[part 4 of 23: package /Cluster]
AUTOSAR XML (schema 4-3-0)
package /Cluster  (continued)
  can cluster E3V_EVCANFD: baudrate=500000, protocol-name=CAN, protocol-version=2.0, bus-off-recovery={bor-counter-l-1-to-l-2=1, bor-time-l-1=0.05, bor-time-l-2=0.2}, can-fd-baudrate=2000000  (continued)
    can physical channel CHNL: comm-connectors=CN_E3V_EVCANFD  (continued)
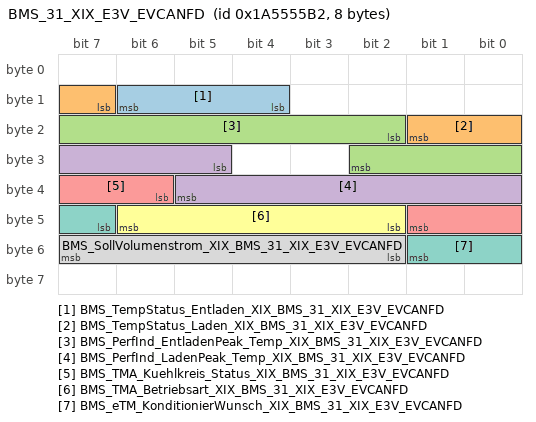
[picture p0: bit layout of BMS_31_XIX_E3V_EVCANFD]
      frame BMS_31_XIX_E3V_EVCANFD: id 0x1A5555B2, to Klima, frame-length=8, can-addressing-mode=EXTENDED, can-frame-rx-behavior=CAN-FD, can-frame-tx-behavior=CAN-FD
        pdu BMS_31_XIX_E3V_EVCANFD: length=8, transmission-mode-true-timing=cyclic-timing={time-offset=0.0, time-period=0.5}, unused-bit-pattern=0
          signal BMS_TempStatus_Entladen_XIX_BMS_31_XIX_E3V_EVCANFD: start 12, 3 bit, little-endian, data-type-policy=OVERRIDE, i-signal-type=PRIMITIVE, init-value=0, base-type=BT_BMS_TempStatus_Entladen, invalid-value=Invalid_BMS_TempStatus_Entladen_XIX_BMS_31_XIX_E3V_EVCANFD:7, compu {0=Cx0_Init (CM_BMS_TempStatus_Entladen_Cx0_Init), 1=Cx1_Temperatur_kleiner_optimal (CM_BMS_TempStatus_Entladen_Cx1_Temperatur_kleiner_optimal), 2=Cx2_Temperatur_optimal (CM_BMS_TempStatus_Entladen_Cx2_Temperatur_optimal), 3=Cx3_Temperatur_groesser_optimal (CM_BMS_TempStatus_Entladen_Cx3_Temperatur_groesser_optimal), 7=Cx7_Fehler (CM_BMS_TempStatus_Entladen_Cx7_Fehler)}, range raw 0..7, transfer-property=PENDING  # Signalisiert den Temperaturzustand der Batterie aufgrund dessen eine evt. Leistungseinschränkung beim Entladen besteht.
          signal BMS_TempStatus_Laden_XIX_BMS_31_XIX_E3V_EVCANFD: start 15, 3 bit, little-endian, data-type-policy=OVERRIDE, i-signal-type=PRIMITIVE, init-value=0, base-type=BT_BMS_TempStatus_Laden, invalid-value=Invalid_BMS_TempStatus_Laden_XIX_BMS_31_XIX_E3V_EVCANFD:7, compu {0=Cx0_Init (CM_BMS_TempStatus_Laden_Cx0_Init), 1=Cx1_Temperatur_kleiner_optimal (CM_BMS_TempStatus_Laden_Cx1_Temperatur_kleiner_optimal), 2=Cx2_Temperatur_optimal (CM_BMS_TempStatus_Laden_Cx2_Temperatur_optimal), 3=Cx3_Temperatur_groesser_optimal (CM_BMS_TempStatus_Laden_Cx3_Temperatur_groesser_optimal), 7=Cx7_Fehler (CM_BMS_TempStatus_Laden_Cx7_Fehler)}, range raw 0..7, transfer-property=PENDING  # Signalisiert den Temperaturzustand der Batterie aufgrund dessen eine evt. Leistungseinschränkung beim Laden besteht.
          signal BMS_PerfInd_EntladenPeak_Temp_XIX_BMS_31_XIX_E3V_EVCANFD: start 18, 9 bit, little-endian, data-type-policy=OVERRIDE, i-signal-type=PRIMITIVE, init-value=510, base-type=BT_BMS_PerfInd_EntladenPeak_Temp, invalid-value=Invalid_BMS_PerfInd_EntladenPeak_Temp_XIX_BMS_31_XIX_E3V_EVCANFD:511, compu {phys=raw*0.2 for raw 0..500, 510=Cx1fe_Init (CM_BMS_PerfInd_EntladenPeak_Temp_Cx1fe_Init), 511=Cx1ff_Fehler (CM_BMS_PerfInd_EntladenPeak_Temp_Cx1ff_Fehler); unit Unit_PerCent}, range phys 0..100 Unit_PerCent, raw 0..511, unit=Unit_PerCent, transfer-property=PENDING  # Peformanceindikator für temperaturabhängige Leistungsreduzierung beim Entladen (bezogen auf Peakleistung entsprechend des SOCs bei Wohlfühltemperatur)
          signal BMS_PerfInd_LadenPeak_Temp_XIX_BMS_31_XIX_E3V_EVCANFD: start 29, 9 bit, little-endian, data-type-policy=OVERRIDE, i-signal-type=PRIMITIVE, init-value=510, base-type=BT_BMS_PerfInd_LadenPeak_Temp, invalid-value=Invalid_BMS_PerfInd_LadenPeak_Temp_XIX_BMS_31_XIX_E3V_EVCANFD:511, compu {phys=raw*0.2 for raw 0..500, 510=Cx1fe_Init (CM_BMS_PerfInd_LadenPeak_Temp_Cx1fe_Init), 511=Cx1ff_Fehler (CM_BMS_PerfInd_LadenPeak_Temp_Cx1ff_Fehler); unit Unit_PerCent}, range phys 0..100 Unit_PerCent, raw 0..511, unit=Unit_PerCent, transfer-property=PENDING  # Peformanceindikator für temperaturabhängige Leistungsreduzierung beim Laden (bezogen auf Peakleistung entsprechend des SOCs bei Wohlfühltemperatur)
          signal BMS_TMA_Kuehlkreis_Status_XIX_BMS_31_XIX_E3V_EVCANFD: start 38, 4 bit, little-endian, data-type-policy=OVERRIDE, i-signal-type=PRIMITIVE, init-value=0, base-type=BT_BMS_TMA_Kuehlkreis_Status, invalid-value=Invalid_BMS_TMA_Kuehlkreis_Status_XIX_BMS_31_XIX_E3V_EVCANFD:15, compu {0=Cx0_Off (CM_BMS_TMA_Kuehlkreis_Status_Cx0_Off), 1=Cx1_Umwaelzbetrieb (CM_BMS_TMA_Kuehlkreis_Status_Cx1_Umwaelzbetrieb), 2=Cx2_Kuehlung_1_Kreis_Betrieb (CM_BMS_TMA_Kuehlkreis_Status_Cx2_Kuehlung_1_Kreis_Betrieb), 3=Cx3_Heizung_1_Kreis_Betrieb (CM_BMS_TMA_Kuehlkreis_Status_Cx3_Heizung_1_Kreis_Betrieb), 4=Cx4_Aktive_Kuehlung_2_Kreis_Betrieb (CM_BMS_TMA_Kuehlkreis_Status_Cx4_Aktive_Kuehlung_2_Kreis_Betrieb), 5=Cx5_Aktive_Heizung_2_Kreis_Betrieb (CM_BMS_TMA_Kuehlkreis_Status_Cx5_Aktive_Heizung_2_Kreis_Betrieb), 15=Cxf_Fehler (CM_BMS_TMA_Kuehlkreis_Status_Cxf_Fehler)}, range raw 0..15, transfer-property=PENDING, to Klima(timeout 5 s)  # HVBat meldet den seitens Batterie gerade aktiven Zustand des Kühlkreises/Kühlsystems. 0 = Batterieklimatisierung abgeschaltet, Pumpe abgeschaltet. Ventilstellung im 2-Kreis-Betrieb, so daß NT-Kreis weiterhin betrieben werden kann. 1 = Umwälzbetrieb, thermisches Balancing; Batteriekreis vom NT-Kreis getrennt. 2 = Batteriekühlung im 1-Kreis-Betrieb, Batterie-Kühlkreis mit NT-Kreis gekoppelt. 3 = Batterieheizung im 1-Kreis-Betrieb, Batterie-Kühlkreis mit NT-Kreis gekoppelt. 4 = aktive Batteriekühlung über Chiller im 2-Kreis-Betrieb; Batteriekreis vom NT-Kreis getrennt.. 5 = aktive Batterieheizung über HV-Heizer im 2-Kreis-Betrieb; Batteriekreis vom NT-Kreis getrennt. 15 = Allgemeiner Kühlsystem-Fehler
          signal BMS_TMA_Betriebsart_XIX_BMS_31_XIX_E3V_EVCANFD: start 42, 5 bit, little-endian, data-type-policy=OVERRIDE, i-signal-type=PRIMITIVE, init-value=30, base-type=BT_BMS_TMA_Betriebsart, invalid-value=Invalid_BMS_TMA_Betriebsart_XIX_BMS_31_XIX_E3V_EVCANFD:31, compu {0=Cx0_BA_TMA_Off (CM_BMS_TMA_Betriebsart_Cx0_BA_TMA_Off), 1=Cx1_BA_TMA_Drv (CM_BMS_TMA_Betriebsart_Cx1_BA_TMA_Drv), 2=Cx2_BA_TMA_DrvLadVoKo (CM_BMS_TMA_Betriebsart_Cx2_BA_TMA_DrvLadVoKo), 3=Cx3_BA_TMA_AC (CM_BMS_TMA_Betriebsart_Cx3_BA_TMA_AC), 4=Cx4_BA_TMA_DC (CM_BMS_TMA_Betriebsart_Cx4_BA_TMA_DC), 5=Cx5_BA_TMA_BiDi (CM_BMS_TMA_Betriebsart_Cx5_BA_TMA_BiDi), 6=Cx6_BA_TMA_HeatTransferWP (CM_BMS_TMA_Betriebsart_Cx6_BA_TMA_HeatTransferWP), 7=Cx7_BA_TMA_VoKo (CM_BMS_TMA_Betriebsart_Cx7_BA_TMA_VoKo), 8=Cx8_BA_TMA_Nachlauf (CM_BMS_TMA_Betriebsart_Cx8_BA_TMA_Nachlauf), 9=Cx9_BA_TMA_OffgridAuto (CM_BMS_TMA_Betriebsart_Cx9_BA_TMA_OffgridAuto), 10=Cxa_BA_TMA_OffgridBCCM (CM_BMS_TMA_Betriebsart_Cxa_BA_TMA_OffgridBCCM), 11=Cxb_BA_TMA_KonservierungBCCM (CM_BMS_TMA_Betriebsart_Cxb_BA_TMA_KonservierungBCCM), 12=Cxc_BA_TMA_NachlaufBCCM (CM_BMS_TMA_Betriebsart_Cxc_BA_TMA_NachlaufBCCM), 13=Cxd_BA_TMA_Enteisung_Klima (CM_BMS_TMA_Betriebsart_Cxd_BA_TMA_Enteisung_Klima), 26=Cx1a_BA_TMA_Transport (CM_BMS_TMA_Betriebsart_Cx1a_BA_TMA_Transport), 27=Cx1b_BA_TMA_BremsReku (CM_BMS_TMA_Betriebsart_Cx1b_BA_TMA_BremsReku), 28=Cx1c_BA_TMA_Befuellung (CM_BMS_TMA_Betriebsart_Cx1c_BA_TMA_Befuellung), 29=Cx1d_BA_TMA_RoutineControl (CM_BMS_TMA_Betriebsart_Cx1d_BA_TMA_RoutineControl), 30=Cx1e_Init (CM_BMS_TMA_Betriebsart_Cx1e_Init), 31=Cx1f_Fehler (CM_BMS_TMA_Betriebsart_Cx1f_Fehler)}, range raw 0..31, transfer-property=PENDING, to Klima(timeout 5 s)  # Interne Betriebsart des Batterie-Thermomanagements. 0 = Klimatisierung abgeschaltet 1 = für "normalen" Fahrbetrieb aktiv 2 = Vorkonditionierung auf Schnelladung während Fahrt 3 = reduzierte Klimatisierung im AC-Laden 4 = maximale Klimatisierung im DC-Schnelladen 5 = reduzierte Klimatisierung im Bidirektionalen Laden 6 = Wärmetransfer Batterie zu Innenraum 7 = Vorkonditionierung/Standklima 8 = Klimatisierungs-Nachlauf 9 = Dauerkond. selbständig ausgelösst 10= Dauerkond. Care-Mode-getriggert 11= Konservierung; lebensdauerschonendes Einlagern der Batterie, veranlasst durch Care-Mode 12= Erweiterter Klimatisierungs-Nachlauf, veranlasst durch Care-Mode 13= Enteisung NTK; Klima hat Priorität, HVBat stellt ihren Bedarf zurück. 26= Transportmode / Transportschutz aktiv; Thermomanagement deaktiviert 27= Heizer für Bremsrekuperation aktiviert 28= Kühlkreis-Befüllung/Entlüftung 29= Stellgliedtest/Routine Control 30= Init 31= Fehler
          signal BMS_eTM_KonditionierWunsch_XIX_BMS_31_XIX_E3V_EVCANFD: start 47, 3 bit, little-endian, data-type-policy=OVERRIDE, i-signal-type=PRIMITIVE, init-value=0, base-type=BT_BMS_eTM_KonditionierWunsch, compu {0=Cx0_kein_Temperierwunsch (CM_BMS_eTM_KonditionierWunsch_Cx0_kein_Temperierwunsch), 1=Cx1_Kuehlwunsch (CM_BMS_eTM_KonditionierWunsch_Cx1_Kuehlwunsch), 2=Cx2_Heizwunsch (CM_BMS_eTM_KonditionierWunsch_Cx2_Heizwunsch)}, range raw 0..2, transfer-property=PENDING  # Über dieses Signal teilt die HV-Batterie mit, daß sie gerne über den NT-Kreis gekühlt oder geheizt werden möchte. Die potentielle Umsetzbarkeit dieses Konditionierungswunsches muß über ein CAN-Signal von der Antriebssteuerung bestätigt werden, bevor die HV-Batterie ihr Kühlsystem in den NT-Kreis schaltet.
          signal BMS_SollVolumenstrom_XIX_BMS_31_XIX_E3V_EVCANFD: start 50, 6 bit, little-endian, data-type-policy=OVERRIDE, i-signal-type=PRIMITIVE, init-value=62, base-type=BT_BMS_SollVolumenstrom, invalid-value=Invalid_BMS_SollVolumenstrom_XIX_BMS_31_XIX_E3V_EVCANFD:63, compu {phys=raw for raw 0..61, 62=Cx3e_Init (CM_BMS_SollVolumenstrom_Cx3e_Init), 63=Cx3f_Fehler (CM_BMS_SollVolumenstrom_Cx3f_Fehler); unit Unit_LiterPerMinut}, range phys 0..61 Unit_LiterPerMinut, raw 0..63, unit=Unit_LiterPerMinut, transfer-property=PENDING  # Soll Volumenstrom für Kühlkreislauf Batterie
      frame BMS_34_XIX_E3V_EVCANFD: id 0xAF95450, to Klima, frame-length=32, can-addressing-mode=EXTENDED, can-frame-rx-behavior=CAN-FD, can-frame-tx-behavior=CAN-FD
        pdu BMS_34_XIX_E3V_EVCANFD: length=24, minimum-delay=0.01, transmission-mode-true-timing={cyclic-timing={time-offset=0.0, time-period=0.1}, event-controlled-timing={number-of-repetitions=0, repetition-period=0.0}}, unused-bit-pattern=0
          signal BMS_Crashfall_erkannt_XIX_BMS_34_XIX_E3V_EVCANFD: start 14, 2 bit, little-endian, data-type-policy=OVERRIDE, i-signal-type=PRIMITIVE, init-value=0, base-type=BT_BMS_Crashfall_erkannt, compu {0=Cx0_Kein_Crash_erkannt (CM_BMS_Crashfall_erkannt_Cx0_Kein_Crash_erkannt), 1=Cx1_Crash_erkannt (CM_BMS_Crashfall_erkannt_Cx1_Crash_erkannt)}, range raw 0..1, transfer-property=PENDING  # Das Signal wird für den in der EU BattVO Art. 77 geforderten Batteriepass benötigt. Es zeigt an, ob die HV-Batterie einen Crashfall erlebt hat.
          signal BMS_UBE_XIX_BMS_34_XIX_E3V_EVCANFD: start 16, 16 bit, little-endian, data-type-policy=OVERRIDE, i-signal-type=PRIMITIVE, init-value=65534, base-type=BT_BMS_UBE, invalid-value=Invalid_BMS_UBE_XIX_BMS_34_XIX_E3V_EVCANFD:65535, compu {phys=raw*5-7400 for raw 0..65480, 65534=Cxfffe_Init (CM_BMS_UBE_Cxfffe_Init), 65535=Cxffff_Fehler (CM_BMS_UBE_Cxffff_Fehler); unit Unit_WattHour}, range phys -7400..320000 Unit_WattHour, raw 0..65535, unit=Unit_WattHour, transfer-property=PENDING  # „Usable Battery Energy“ = Nutzbare Entladeenergie der HV Batterie vom aktuellen Ladezustand bis zum Ende des elektrischen Fahrens unter Annahme von Homologationsbedingungen (Lastprofil, Temperatur). Ein negativer Wert bedeutet, dass der aktuelle Ladezustand kleiner als EV Abwurfschwelle ist. Bei BMS_UBE <= 0 muss die Betriebsstrategie das normale EV Fahrenn (homologierte Reichweite) beenden. Unter Einhaltung der Strom- und Leistungsgrenzen darf der Nullwert z.B. für Notstarts und Hybridstrategie unterschritten werden.
          signal BMS_UBE_T_XIX_BMS_34_XIX_E3V_EVCANFD: start 32, 16 bit, little-endian, data-type-policy=OVERRIDE, i-signal-type=PRIMITIVE, init-value=65534, base-type=BT_BMS_UBE_T, invalid-value=Invalid_BMS_UBE_T_XIX_BMS_34_XIX_E3V_EVCANFD:65535, compu {phys=raw*5-7400 for raw 0..65480, 65534=Cxfffe_Init (CM_BMS_UBE_T_Cxfffe_Init), 65535=Cxffff_Fehler (CM_BMS_UBE_T_Cxffff_Fehler); unit Unit_WattHour}, range phys -7400..320000 Unit_WattHour, raw 0..65535, unit=Unit_WattHour, transfer-property=PENDING, to Klima(timeout 1 s)  # Gleiche Bedeutung wie das Signal BMS_UBE unter Berücksichtigung der aktuellen Batterietemperatur. Eine Temperaturänderung wird nicht angenommen. Dieses Signal kann zum Beispiel verwendet werden, um eine Restenergie der HV Batterie zu berechnen.
          signal BMS_Max_UBE_XIX_BMS_34_XIX_E3V_EVCANFD: start 48, 16 bit, little-endian, data-type-policy=OVERRIDE, i-signal-type=PRIMITIVE, init-value=65534, base-type=BT_BMS_Max_UBE, invalid-value=Invalid_BMS_Max_UBE_XIX_BMS_34_XIX_E3V_EVCANFD:65535, compu {phys=raw*5-7400 for raw 0..65480, 65534=Cxfffe_Init (CM_BMS_Max_UBE_Cxfffe_Init), 65535=Cxffff_Fehler (CM_BMS_Max_UBE_Cxffff_Fehler); unit Unit_WattHour}, range phys -7400..320000 Unit_WattHour, raw 0..65535, unit=Unit_WattHour, transfer-property=PENDING  # BMS_UBE bei BMS_Ladezustand = BMS_Max_Ladezustand. Das Verhältnis BMS_UBE/BMS_UBE_Max ergibt den energetischen Kunden-SOC (ohne Berücksichtigung eventueller Anzeigereserven)
          signal BMS_Nennspannung_XIX_BMS_34_XIX_E3V_EVCANFD: start 64, 11 bit, little-endian, data-type-policy=OVERRIDE, i-signal-type=PRIMITIVE, init-value=2046, base-type=BT_BMS_Nennspannung, compu {phys=raw*0.5 for raw 0..2000, 2046=Cx7fe_Init (CM_BMS_Nennspannung_Cx7fe_Init); unit Unit_Volt}, range phys 0..1000 Unit_Volt, raw 0..2046, unit=Unit_Volt, transfer-property=PENDING  # Nennspannung der HV Batterie (Nennspannung der Zelle nach PV8450 multipliziert mal Anzahl in Serie geschalteter Zellen)
          signal BMS_DC_Ladeschuetze_Ist_XIX_BMS_34_XIX_E3V_EVCANFD: start 75, 3 bit, little-endian, data-type-policy=OVERRIDE, i-signal-type=PRIMITIVE, init-value=6, base-type=BT_BMS_DC_Ladeschuetze_Ist, compu {0=Cx0_geoeffnet (CM_BMS_DC_Ladeschuetze_Ist_Cx0_geoeffnet), 1=Cx1_geschlossen (CM_BMS_DC_Ladeschuetze_Ist_Cx1_geschlossen), 2=Cx2_reserviert (CM_BMS_DC_Ladeschuetze_Ist_Cx2_reserviert), 3=Cx3_reserviert (CM_BMS_DC_Ladeschuetze_Ist_Cx3_reserviert), 4=Cx4_reserviert (CM_BMS_DC_Ladeschuetze_Ist_Cx4_reserviert), 5=Cx5_nicht_verbaut (CM_BMS_DC_Ladeschuetze_Ist_Cx5_nicht_verbaut), 6=Cx6_Init (CM_BMS_DC_Ladeschuetze_Ist_Cx6_Init), 7=Cx7_Schuetzfehler (CM_BMS_DC_Ladeschuetze_Ist_Cx7_Schuetzfehler)}, range raw 0..7, transfer-property=TRIGGERED-ON-CHANGE-WITHOUT-REPETITION  # Status der DC-Ladeschütze der HV-Batterie
          signal BMS_Hauptschuetze_Ist_XIX_BMS_34_XIX_E3V_EVCANFD: start 78, 3 bit, little-endian, data-type-policy=OVERRIDE, i-signal-type=PRIMITIVE, init-value=6, base-type=BT_BMS_Hauptschuetze_Ist, compu {0=Cx0_geoeffnet (CM_BMS_Hauptschuetze_Ist_Cx0_geoeffnet), 1=Cx1_geschlossen (CM_BMS_Hauptschuetze_Ist_Cx1_geschlossen), 2=Cx2_reserviert (CM_BMS_Hauptschuetze_Ist_Cx2_reserviert), 3=Cx3_reserviert (CM_BMS_Hauptschuetze_Ist_Cx3_reserviert), 4=Cx4_reserviert (CM_BMS_Hauptschuetze_Ist_Cx4_reserviert), 5=Cx5_nicht_verbaut (CM_BMS_Hauptschuetze_Ist_Cx5_nicht_verbaut), 6=Cx6_Init (CM_BMS_Hauptschuetze_Ist_Cx6_Init), 7=Cx7_Schuetzfehler (CM_BMS_Hauptschuetze_Ist_Cx7_Schuetzfehler)}, range raw 0..7, transfer-property=TRIGGERED-ON-CHANGE-WITHOUT-REPETITION  # Status der Hauptschütze der HV-Batterie
          signal BMS_UBE_Indikator_XIX_BMS_34_XIX_E3V_EVCANFD: start 81, 11 bit, little-endian, data-type-policy=OVERRIDE, i-signal-type=PRIMITIVE, init-value=2046, base-type=BT_BMS_UBE_Indikator, invalid-value=Invalid_BMS_UBE_Indikator_XIX_BMS_34_XIX_E3V_EVCANFD:2047, compu {phys=raw*0.05 for raw 0..2000, 2042=Cx7fa_Funktion_nicht_vorhanden (CM_BMS_UBE_Indikator_Cx7fa_Funktion_nicht_vorhanden), 2043=Cx7fb_kleiner_0 (CM_BMS_UBE_Indikator_Cx7fb_kleiner_0), 2044=Cx7fc_groesser_100 (CM_BMS_UBE_Indikator_Cx7fc_groesser_100), 2045=Cx7fd_nicht_angelernt (CM_BMS_UBE_Indikator_Cx7fd_nicht_angelernt), 2046=Cx7fe_Init (CM_BMS_UBE_Indikator_Cx7fe_Init), 2047=Cx7ff_Fehler (CM_BMS_UBE_Indikator_Cx7ff_Fehler); unit Unit_PerCent}, range phys 0..100 Unit_PerCent, raw 0..2047, unit=Unit_PerCent, transfer-property=PENDING  # Der UBE Indikator gibt das Verhältnis der aktuellen maximalen UBE (BMS_Max_UBE) zur maximalen UBE einer neuen HV Batterie wieder.
          signal BMS_UBE_Indik_last_update_km_XIX_BMS_34_XIX_E3V_EVCANFD: start 92, 20 bit, little-endian, data-type-policy=OVERRIDE, i-signal-type=PRIMITIVE, init-value=1048574, base-type=BT_BMS_UBE_Indik_last_update_km, invalid-value=Invalid_BMS_UBE_Indik_last_update_km_XIX_BMS_34_XIX_E3V_EVCANFD:1048575, compu {phys=raw for raw 0..1000000, 1048573=Cxffffd_Funktion_nicht_umgesetzt (CM_BMS_UBE_Indik_last_update_km_Cxffffd_Funktion_nicht_umgesetzt), 1048574=Cxffffe_Init (CM_BMS_UBE_Indik_last_update_km_Cxffffe_Init), 1048575=Cxfffff_Fehler (CM_BMS_UBE_Indik_last_update_km_Cxfffff_Fehler); unit Unit_KiloMeter}, range phys 0..1000000 Unit_KiloMeter, raw 0..1048575, unit=Unit_KiloMeter, transfer-property=PENDING  # Strecke seit letzter Aktualisierung des UBE-Indikators. Ausgabe in der Einheit [km]
          signal BMS_OCV_Dauer_Relaxation_XIX_BMS_34_XIX_E3V_EVCANFD: start 112, 8 bit, little-endian, data-type-policy=OVERRIDE, i-signal-type=PRIMITIVE, init-value=0, base-type=BT_BMS_OCV_Dauer_Relaxation, invalid-value=Invalid_BMS_OCV_Dauer_Relaxation_XIX_BMS_34_XIX_E3V_EVCANFD:255, compu {phys=raw for raw 0..250, 254=Cxfe_Init (CM_BMS_OCV_Dauer_Relaxation_Cxfe_Init), 255=Cxff_Fehler (CM_BMS_OCV_Dauer_Relaxation_Cxff_Fehler); unit Unit_Minut}, range phys 0..250 Unit_Minut, raw 0..255, unit=Unit_Minut, transfer-property=PENDING  # Erforderliche Dauer der Relaxation für SOC-Kalibrierung
          signal BMS_SoC_Genauigkeit_XIX_BMS_34_XIX_E3V_EVCANFD: start 120, 7 bit, little-endian, data-type-policy=OVERRIDE, i-signal-type=PRIMITIVE, init-value=0, base-type=BT_BMS_SoC_Genauigkeit, invalid-value=Invalid_BMS_SoC_Genauigkeit_XIX_BMS_34_XIX_E3V_EVCANFD:127, compu {phys=raw for raw 0..100, 126=Cx7e_Init (CM_BMS_SoC_Genauigkeit_Cx7e_Init), 127=Cx7f_Fehler (CM_BMS_SoC_Genauigkeit_Cx7f_Fehler); unit Unit_PerCent}, range phys 0..100 Unit_PerCent, raw 0..127, unit=Unit_PerCent, transfer-property=PENDING  # Worst-Case-Wert für Fehler der SOC-Bestimmung
          signal BMS_VTD_FreezeReq_XIX_BMS_34_XIX_E3V_EVCANFD: start 127, 1 bit, little-endian, data-type-policy=OVERRIDE, i-signal-type=PRIMITIVE, init-value=0, base-type=BT_BMS_VTD_FreezeReq, compu {0=Cx0_Update_VDT (CM_BMS_VTD_FreezeReq_Cx0_Update_VDT), 1=Cx1_Freeze_VDT (CM_BMS_VTD_FreezeReq_Cx1_Freeze_VDT)}, range raw 0..1, transfer-property=PENDING  # Freeze-Request des BECM (BMC) zum Stoppen der fahrzeugweiten Berechnung der VehicleTrackingData
          signal BMS_EnergieVorhalt_XIX_BMS_34_XIX_E3V_EVCANFD: start 128, 16 bit, little-endian, data-type-policy=OVERRIDE, i-signal-type=PRIMITIVE, init-value=65534, base-type=BT_BMS_EnergieVorhalt, invalid-value=Invalid_BMS_EnergieVorhalt_XIX_BMS_34_XIX_E3V_EVCANFD:65535, compu {phys=raw*0.1 for raw 0..64000, 65533=Cxfffd_Funktion_nicht_umgesetzt (CM_BMS_EnergieVorhalt_Cxfffd_Funktion_nicht_umgesetzt), 65534=Cxfffe_Init (CM_BMS_EnergieVorhalt_Cxfffe_Init), 65535=Cxffff_Fehler (CM_BMS_EnergieVorhalt_Cxffff_Fehler); unit Unit_KiloWattHour}, range phys 0..6400 Unit_KiloWattHour, raw 0..65535, unit=Unit_KiloWattHour, transfer-property=PENDING  # Energievorhalt der Batterie (z.B. als Alterungsreserve), welcher nicht in der aktuellen Betriebsstrategie verwendet werden kann, aber zur Kompensation der Alterung genutzt werden kann.
          signal BMS_Range_Indikator_XIX_BMS_34_XIX_E3V_EVCANFD: start 144, 11 bit, little-endian, data-type-policy=OVERRIDE, i-signal-type=PRIMITIVE, init-value=2046, base-type=BT_BMS_Range_Indikator, invalid-value=Invalid_BMS_Range_Indikator_XIX_BMS_34_XIX_E3V_EVCANFD:2047, compu {phys=raw*0.05 for raw 0..2000, 2042=Cx7fa_Funktion_nicht_vorhanden (CM_BMS_Range_Indikator_Cx7fa_Funktion_nicht_vorhanden), 2043=Cx7fb_kleiner_0 (CM_BMS_Range_Indikator_Cx7fb_kleiner_0), 2044=Cx7fc_groesser_100 (CM_BMS_Range_Indikator_Cx7fc_groesser_100), 2045=Cx7fd_nicht_angelernt (CM_BMS_Range_Indikator_Cx7fd_nicht_angelernt), 2046=Cx7fe_Init (CM_BMS_Range_Indikator_Cx7fe_Init), 2047=Cx7ff_Fehler (CM_BMS_Range_Indikator_Cx7ff_Fehler); unit Unit_PerCent}, range phys 0..100 Unit_PerCent, raw 0..2047, unit=Unit_PerCent, transfer-property=PENDING  # Der Range-Indikator gibt das Verhältnis der aktuellen maximalen Reichweite zur maximalen Reichweite eines Neufahrzeugs wieder. Da die Reichweite primär von der UBE abhängt, wird dieser Wert im BMS berechnet.
          signal BMS_Nom_Ladeleistung_XIX_BMS_34_XIX_E3V_EVCANFD: start 155, 13 bit, little-endian, data-type-policy=OVERRIDE, i-signal-type=PRIMITIVE, init-value=0, base-type=BT_BMS_Nom_Ladeleistung, compu {phys=raw*100 for raw 0..8180, 8190=Cx1ffe_Init (CM_BMS_Nom_Ladeleistung_Cx1ffe_Init); unit Unit_Watt}, range phys 0..818000 Unit_Watt, raw 0..8190, unit=Unit_Watt, transfer-property=PENDING  # Nominelle Ladeleistung der HV-Batterie zur Verwendung als Bezugsgröße
          signal BMS_Relaxation_Status_XIX_BMS_34_XIX_E3V_EVCANFD: start 170, 3 bit, little-endian, data-type-policy=OVERRIDE, i-signal-type=PRIMITIVE, init-value=0, base-type=BT_BMS_Relaxation_Status, invalid-value=Invalid_BMS_Relaxation_Status_XIX_BMS_34_XIX_E3V_EVCANFD:7, compu {0=Cx0_Init (CM_BMS_Relaxation_Status_Cx0_Init), 1=Cx1_Relaxation_aktiv (CM_BMS_Relaxation_Status_Cx1_Relaxation_aktiv), 2=Cx2_Relaxation_unterbrochen (CM_BMS_Relaxation_Status_Cx2_Relaxation_unterbrochen), 3=Cx3_Relaxation_abgebrochen (CM_BMS_Relaxation_Status_Cx3_Relaxation_abgebrochen), 4=Cx4_Relaxation_abgeschlossen (CM_BMS_Relaxation_Status_Cx4_Relaxation_abgeschlossen), 5=Cx5_Relaxation_inaktiv (CM_BMS_Relaxation_Status_Cx5_Relaxation_inaktiv), 7=Cx7_Fehler (CM_BMS_Relaxation_Status_Cx7_Fehler)}, range raw 0..7, transfer-property=PENDING  # Status der Relaxation für SOC-Kalibrierung
          signal BMS_VTD_LifetimeResetReq_XIX_BMS_34_XIX_E3V_EVCANFD: start 173, 1 bit, little-endian, data-type-policy=OVERRIDE, i-signal-type=PRIMITIVE, init-value=0, base-type=BT_BMS_VTD_LifetimeResetReq, compu {0=Cx0_Update_VTD (CM_BMS_VTD_LifetimeResetReq_Cx0_Update_VTD), 1=Cx1_Reset_VTD (CM_BMS_VTD_LifetimeResetReq_Cx1_Reset_VTD)}, range raw 0..1, transfer-property=PENDING  # Reset-Request des BECM (BMC) zum Zurücksetzen der fahrzeugweiten Berechnung der Lifetime VehicleTrackingData nach Updateprogrammierung
          signal BMS_VTD_LifetimeResetResp_XIX_BMS_34_XIX_E3V_EVCANFD: start 174, 2 bit, little-endian, data-type-policy=OVERRIDE, i-signal-type=PRIMITIVE, init-value=0, base-type=BT_BMS_VTD_LifetimeResetResp, compu {0=Cx0_Not_Reset (CM_BMS_VTD_LifetimeResetResp_Cx0_Not_Reset), 1=Cx1_Reset (CM_BMS_VTD_LifetimeResetResp_Cx1_Reset), 2=Cx2_Not_Supported (CM_BMS_VTD_LifetimeResetResp_Cx2_Not_Supported), 3=Cx3_reserved (CM_BMS_VTD_LifetimeResetResp_Cx3_reserved)}, range raw 0..3, transfer-property=PENDING  # Reset-Response des BECM (BMC) zur Signalisierung der zurückgesetzten Lifetime VehicleTrackingData auf einen Reset-Lifetime-Request
          signal BMS_VTD_DivideLifetimeCntReq_XIX_BMS_34_XIX_E3V_EVCANFD: start 176, 1 bit, little-endian, data-type-policy=OVERRIDE, i-signal-type=PRIMITIVE, init-value=0, base-type=BT_BMS_VTD_DivideLifetimeCntReq, compu {0=Cx0_Update_VTD (CM_BMS_VTD_DivideLifetimeCntReq_Cx0_Update_VTD), 1=Cx1_Divide_VTD (CM_BMS_VTD_DivideLifetimeCntReq_Cx1_Divide_VTD)}, range raw 0..1, transfer-property=PENDING  # Aufforderung vom BECM (BMC) zum halbieren aller "Lifetime" VehicleTrackingData wenn ein VTD-Lifetime-Zähler im BECM seinen Höchstwert erreicht - Request from BECM to divide all lifetime VehicleTrackingData by two when a VTD lifetime counter in the BECM reaches its maximum value
          signal BMS_VTD_DivideLifetimeCntResp_XIX_BMS_34_XIX_E3V_EVCANFD: start 177, 2 bit, little-endian, data-type-policy=OVERRIDE, i-signal-type=PRIMITIVE, init-value=2, base-type=BT_BMS_VTD_DivideLifetimeCntResp, compu {0=Cx0_Not_Divided (CM_BMS_VTD_DivideLifetimeCntResp_Cx0_Not_Divided), 1=Cx1_Divided (CM_BMS_VTD_DivideLifetimeCntResp_Cx1_Divided), 2=Cx2_Not_Supported (CM_BMS_VTD_DivideLifetimeCntResp_Cx2_Not_Supported), 3=Cx3_reserved (CM_BMS_VTD_DivideLifetimeCntResp_Cx3_reserved)}, range raw 0..3, transfer-property=PENDING  # Antwort des BECM (BMC) zur Signalisierung der Halbierung aller "Lifetime" VehicleTrackingData - Response from BECM that lifetime VehicleTrackingData where divided by two
      frame CCP_Klima_CRO_01_XIX_E3V_EVCANFD: id 0x1BFE3600, to Klima, frame-length=8, can-addressing-mode=EXTENDED, can-frame-rx-behavior=CAN-FD, can-frame-tx-behavior=CAN-FD
        user defined pdu CDD_CCP_Klima_CRO_01_XIX_E3V_EVCANFD: length=8, cdd-type=EID
      frame CCP_Klima_CRO_02_XIX_E3V_EVCANFD: id 0x1BFE3602, to Klima, frame-length=8, can-addressing-mode=EXTENDED, can-frame-rx-behavior=CAN-FD, can-frame-tx-behavior=CAN-FD
        user defined pdu CDD_CCP_Klima_CRO_02_XIX_E3V_EVCANFD: length=8, cdd-type=EID
      frame CCP_Klima_DTO_01_XIX_E3V_EVCANFD: id 0x1BFE3601, from Klima, frame-length=8, can-addressing-mode=EXTENDED, can-frame-rx-behavior=CAN-FD, can-frame-tx-behavior=CAN-FD
        user defined pdu CDD_CCP_Klima_DTO_01_XIX_E3V_EVCANFD: length=8, cdd-type=EID
      frame Charisma_03_XIX_E3V_EVCANFD: id 0x386, to Klima, frame-length=8, can-addressing-mode=STANDARD, can-frame-rx-behavior=CAN-FD, can-frame-tx-behavior=CAN-FD
        pdu Charisma_03_XIX_E3V_EVCANFD: length=8, minimum-delay=0.05, transmission-mode-true-timing={cyclic-timing={time-offset=0.0, time-period=1.0}, event-controlled-timing={number-of-repetitions=0, repetition-period=0.0}}, unused-bit-pattern=0  # ab MQB 7.2.1
          signal CHA_Charisma_Taste2_LED_XIX_Charisma_03_XIX_E3V_EVCANFD: start 0, 2 bit, little-endian, data-type-policy=OVERRIDE, i-signal-type=PRIMITIVE, init-value=0, base-type=BT_CHA_Charisma_Taste2_LED, invalid-value=Invalid_CHA_Charisma_Taste2_LED_XIX_Charisma_03_XIX_E3V_EVCANFD:3, compu {0=Cx0_LED_aus (CM_CHA_Charisma_Taste2_LED_Cx0_LED_aus), 1=Cx1_LED_ein (CM_CHA_Charisma_Taste2_LED_Cx1_LED_ein), 2=Cx2_LED_blinken (CM_CHA_Charisma_Taste2_LED_Cx2_LED_blinken), 3=Cx3_Fehler (CM_CHA_Charisma_Taste2_LED_Cx3_Fehler)}, range raw 0..3, transfer-property=TRIGGERED-ON-CHANGE-WITHOUT-REPETITION  # Ansteuerung der 2. Charisma-Taste-LED
          signal CHA_ReqPrgDispSetup_XIX_Charisma_03_XIX_E3V_EVCANFD: start 2, 4 bit, little-endian, data-type-policy=OVERRIDE, i-signal-type=PRIMITIVE, init-value=0, base-type=BT_CHA_ReqPrgDispSetup, compu {0=Cx0_init (CM_CHA_ReqPrgDispSetup_Cx0_init), 1=Cx1_layout_comfort (CM_CHA_ReqPrgDispSetup_Cx1_layout_comfort), 2=Cx2_layout_eco (CM_CHA_ReqPrgDispSetup_Cx2_layout_eco), 3=Cx3_layout_sport (CM_CHA_ReqPrgDispSetup_Cx3_layout_sport), 4=Cx4_layout_offroad (CM_CHA_ReqPrgDispSetup_Cx4_layout_offroad), 5=Cx5_layout_sportplus (CM_CHA_ReqPrgDispSetup_Cx5_layout_sportplus), 6=Cx6_program_6 (CM_CHA_ReqPrgDispSetup_Cx6_program_6), 7=Cx7_program_7 (CM_CHA_ReqPrgDispSetup_Cx7_program_7), 8=Cx8_program_8 (CM_CHA_ReqPrgDispSetup_Cx8_program_8), 9=Cx9_program_9 (CM_CHA_ReqPrgDispSetup_Cx9_program_9), 10=Cxa_program_10 (CM_CHA_ReqPrgDispSetup_Cxa_program_10), 11=Cxb_program_11 (CM_CHA_ReqPrgDispSetup_Cxb_program_11), 12=Cxc_program_12 (CM_CHA_ReqPrgDispSetup_Cxc_program_12), 13=Cxd_program_13 (CM_CHA_ReqPrgDispSetup_Cxd_program_13), 14=Cxe_program_14 (CM_CHA_ReqPrgDispSetup_Cxe_program_14), 15=Cxf_program_15 (CM_CHA_ReqPrgDispSetup_Cxf_program_15)}, range raw 0..15, transfer-property=TRIGGERED-ON-CHANGE-WITHOUT-REPETITION  # Requested Charisma-programm to Kombi to change display setup.
          signal CHA_Current_Mode_FPA_XIX_Charisma_03_XIX_E3V_EVCANFD: start 6, 6 bit, little-endian, data-type-policy=OVERRIDE, i-signal-type=PRIMITIVE, init-value=0, base-type=BT_CHA_Current_Mode_FPA, compu {0=Cx0_keine_Funktion (CM_CHA_Current_Mode_FPA_Cx0_keine_Funktion), 1=Cx1_Programm_1 (CM_CHA_Current_Mode_FPA_Cx1_Programm_1), 2=Cx2_Programm_2 (CM_CHA_Current_Mode_FPA_Cx2_Programm_2), 3=Cx3_Programm_3 (CM_CHA_Current_Mode_FPA_Cx3_Programm_3), 4=Cx4_Programm_4 (CM_CHA_Current_Mode_FPA_Cx4_Programm_4), 5=Cx5_Programm_5 (CM_CHA_Current_Mode_FPA_Cx5_Programm_5), 6=Cx6_Programm_6 (CM_CHA_Current_Mode_FPA_Cx6_Programm_6), 7=Cx7_Programm_7 (CM_CHA_Current_Mode_FPA_Cx7_Programm_7), 8=Cx8_Programm_8 (CM_CHA_Current_Mode_FPA_Cx8_Programm_8), 9=Cx9_Programm_9 (CM_CHA_Current_Mode_FPA_Cx9_Programm_9), 10=Cxa_Programm_10 (CM_CHA_Current_Mode_FPA_Cxa_Programm_10), 11=Cxb_Programm_11 (CM_CHA_Current_Mode_FPA_Cxb_Programm_11), 12=Cxc_Programm_12 (CM_CHA_Current_Mode_FPA_Cxc_Programm_12), 13=Cxd_Programm_13 (CM_CHA_Current_Mode_FPA_Cxd_Programm_13), 14=Cxe_Programm_14 (CM_CHA_Current_Mode_FPA_Cxe_Programm_14), 15=Cxf_Programm_15 (CM_CHA_Current_Mode_FPA_Cxf_Programm_15), 16=Cx10_Programm_16 (CM_CHA_Current_Mode_FPA_Cx10_Programm_16), 17=Cx11_Programm_17 (CM_CHA_Current_Mode_FPA_Cx11_Programm_17), 18=Cx12_Programm_18 (CM_CHA_Current_Mode_FPA_Cx12_Programm_18), 19=Cx13_Programm_19 (CM_CHA_Current_Mode_FPA_Cx13_Programm_19), 20=Cx14_Programm_20 (CM_CHA_Current_Mode_FPA_Cx14_Programm_20), 21=Cx15_Programm_21 (CM_CHA_Current_Mode_FPA_Cx15_Programm_21), 22=Cx16_Programm_22 (CM_CHA_Current_Mode_FPA_Cx16_Programm_22), 23=Cx17_Programm_23 (CM_CHA_Current_Mode_FPA_Cx17_Programm_23), 24=Cx18_Programm_24 (CM_CHA_Current_Mode_FPA_Cx18_Programm_24), 25=Cx19_Programm_25 (CM_CHA_Current_Mode_FPA_Cx19_Programm_25), 26=Cx1a_Programm_26 (CM_CHA_Current_Mode_FPA_Cx1a_Programm_26), 27=Cx1b_Programm_27 (CM_CHA_Current_Mode_FPA_Cx1b_Programm_27), 28=Cx1c_Programm_28 (CM_CHA_Current_Mode_FPA_Cx1c_Programm_28), 29=Cx1d_Programm_29 (CM_CHA_Current_Mode_FPA_Cx1d_Programm_29), 30=Cx1e_Programm_30 (CM_CHA_Current_Mode_FPA_Cx1e_Programm_30), 31=Cx1f_Programm_31 (CM_CHA_Current_Mode_FPA_Cx1f_Programm_31), 32=Cx20_Programm_32 (CM_CHA_Current_Mode_FPA_Cx20_Programm_32)}, range raw 0..32, transfer-property=TRIGGERED-ON-CHANGE-WITHOUT-REPETITION  # Aktuell eingestelltes Charisma Fahrprogramm
          signal CHA_Eco_Charisma_LED_XIX_Charisma_03_XIX_E3V_EVCANFD: start 12, 2 bit, little-endian, data-type-policy=OVERRIDE, i-signal-type=PRIMITIVE, init-value=0, base-type=BT_CHA_Eco_Charisma_LED, compu {0=Cx0_LED_aus_und_Blinken_aus (CM_CHA_Eco_Charisma_LED_Cx0_LED_aus_und_Blinken_aus), 1=Cx1_LED_ein_und_Blinken_aus (CM_CHA_Eco_Charisma_LED_Cx1_LED_ein_und_Blinken_aus), 2=Cx2_LED_ein_und_Blinken_ein_50_percent (CM_CHA_Eco_Charisma_LED_Cx2_LED_ein_und_Blinken_ein_50_percent), 3=Cx3_reserviert (CM_CHA_Eco_Charisma_LED_Cx3_reserviert)}, range raw 0..3, transfer-property=TRIGGERED-ON-CHANGE-WITHOUT-REPETITION  # Ansteuerung der Funktions-LED der ECO alias Bluekey Taste bzw. Charisma-Taste. Der Master der Fahrmodus-Funktion soll die Funktionsleuchte ansteuern, in der MQB Architektur ist der Master im Gateway untergebracht.
          signal CHA_Fahrer_Umschaltung_XIX_Charisma_03_XIX_E3V_EVCANFD: start 14, 1 bit, little-endian, data-type-policy=OVERRIDE, i-signal-type=PRIMITIVE, init-value=0, base-type=BT_CHA_Fahrer_Umschaltung, compu {0=Cx0_keine_oder_automatische_Umschaltung (CM_CHA_Fahrer_Umschaltung_Cx0_keine_oder_automatische_Umschaltung), 1=Cx1_manuelle_Umschaltung (CM_CHA_Fahrer_Umschaltung_Cx1_manuelle_Umschaltung)}, range raw 0..1, transfer-property=TRIGGERED-ON-CHANGE-WITHOUT-REPETITION, to Klima(timeout 5 s)  # Die manuelle Umschaltung durch den Fahrer soll signalisiert werden, um zu automatischen Umschaltungen (z.B. Retries) differenzieren zu können.
          signal CHA_EV_LED_XIX_Charisma_03_XIX_E3V_EVCANFD: start 15, 1 bit, little-endian, data-type-policy=OVERRIDE, i-signal-type=PRIMITIVE, init-value=0, base-type=BT_CHA_EV_LED, compu {0=Cx0_LED_aus (CM_CHA_EV_LED_Cx0_LED_aus), 1=Cx1_LED_an (CM_CHA_EV_LED_Cx1_LED_an)}, range raw 0..1, transfer-property=TRIGGERED-ON-CHANGE-WITHOUT-REPETITION  # Ansteuerung der LED am EV-Taster durch Charisma im PHEV
          signal CHA_Ziel_FahrPr_AMB_XIX_Charisma_03_XIX_E3V_EVCANFD: start 16, 4 bit, little-endian, data-type-policy=OVERRIDE, i-signal-type=PRIMITIVE, init-value=0, base-type=BT_CHA_Ziel_FahrPr_AMB, compu {0=Cx0_keine_Funktion (CM_CHA_Ziel_FahrPr_AMB_Cx0_keine_Funktion), 1=Cx1_Programm_1 (CM_CHA_Ziel_FahrPr_AMB_Cx1_Programm_1), 2=Cx2_Programm_2 (CM_CHA_Ziel_FahrPr_AMB_Cx2_Programm_2), 3=Cx3_Programm_3 (CM_CHA_Ziel_FahrPr_AMB_Cx3_Programm_3), 4=Cx4_Programm_4 (CM_CHA_Ziel_FahrPr_AMB_Cx4_Programm_4), 5=Cx5_Programm_5 (CM_CHA_Ziel_FahrPr_AMB_Cx5_Programm_5), 6=Cx6_Programm_6 (CM_CHA_Ziel_FahrPr_AMB_Cx6_Programm_6), 7=Cx7_Programm_7 (CM_CHA_Ziel_FahrPr_AMB_Cx7_Programm_7), 8=Cx8_Programm_8 (CM_CHA_Ziel_FahrPr_AMB_Cx8_Programm_8), 9=Cx9_Programm_9 (CM_CHA_Ziel_FahrPr_AMB_Cx9_Programm_9), 10=Cxa_Programm_10 (CM_CHA_Ziel_FahrPr_AMB_Cxa_Programm_10), 11=Cxb_Programm_11 (CM_CHA_Ziel_FahrPr_AMB_Cxb_Programm_11), 12=Cxc_Programm_12 (CM_CHA_Ziel_FahrPr_AMB_Cxc_Programm_12), 13=Cxd_Programm_13 (CM_CHA_Ziel_FahrPr_AMB_Cxd_Programm_13), 14=Cxe_Programm_14 (CM_CHA_Ziel_FahrPr_AMB_Cxe_Programm_14), 15=Cxf_Programm_15 (CM_CHA_Ziel_FahrPr_AMB_Cxf_Programm_15)}, range raw 0..15, transfer-property=TRIGGERED-ON-CHANGE-WITHOUT-REPETITION  # Anforderung Ziel-Fahrprogramm Ambientelichtmodul
          signal CHA_Ziel_FahrPr_IVB_XIX_Charisma_03_XIX_E3V_EVCANFD: start 20, 4 bit, little-endian, data-type-policy=OVERRIDE, i-signal-type=PRIMITIVE, init-value=0, base-type=BT_CHA_Ziel_FahrPr_IVB, compu {0=Cx0_keine_Funktion (CM_CHA_Ziel_FahrPr_IVB_Cx0_keine_Funktion), 1=Cx1_Programm_1 (CM_CHA_Ziel_FahrPr_IVB_Cx1_Programm_1), 2=Cx2_Programm_2 (CM_CHA_Ziel_FahrPr_IVB_Cx2_Programm_2), 3=Cx3_Programm_3 (CM_CHA_Ziel_FahrPr_IVB_Cx3_Programm_3), 4=Cx4_Programm_4 (CM_CHA_Ziel_FahrPr_IVB_Cx4_Programm_4), 5=Cx5_Programm_5 (CM_CHA_Ziel_FahrPr_IVB_Cx5_Programm_5), 6=Cx6_Programm_6 (CM_CHA_Ziel_FahrPr_IVB_Cx6_Programm_6), 7=Cx7_Programm_7 (CM_CHA_Ziel_FahrPr_IVB_Cx7_Programm_7), 8=Cx8_Programm_8 (CM_CHA_Ziel_FahrPr_IVB_Cx8_Programm_8), 9=Cx9_Programm_9 (CM_CHA_Ziel_FahrPr_IVB_Cx9_Programm_9), 10=Cxa_Programm_10 (CM_CHA_Ziel_FahrPr_IVB_Cxa_Programm_10), 11=Cxb_Programm_11 (CM_CHA_Ziel_FahrPr_IVB_Cxb_Programm_11), 12=Cxc_Programm_12 (CM_CHA_Ziel_FahrPr_IVB_Cxc_Programm_12), 13=Cxd_Programm_13 (CM_CHA_Ziel_FahrPr_IVB_Cxd_Programm_13), 14=Cxe_Programm_14 (CM_CHA_Ziel_FahrPr_IVB_Cxe_Programm_14), 15=Cxf_Programm_15 (CM_CHA_Ziel_FahrPr_IVB_Cxf_Programm_15)}, range raw 0..15, transfer-property=TRIGGERED-ON-CHANGE-WITHOUT-REPETITION  # Anforderung Ziel-Fahrprogramm IVB
          signal CHA_Kombi_Texte_XIX_Charisma_03_XIX_E3V_EVCANFD: start 24, 4 bit, little-endian, data-type-policy=OVERRIDE, i-signal-type=PRIMITIVE, init-value=0, base-type=BT_CHA_Kombi_Texte, compu {0=Cx0_keine_Anzeige (CM_CHA_Kombi_Texte_Cx0_keine_Anzeige), 1=Cx1_Text_1 (CM_CHA_Kombi_Texte_Cx1_Text_1), 2=Cx2_Text_2 (CM_CHA_Kombi_Texte_Cx2_Text_2), 3=Cx3_Text_3 (CM_CHA_Kombi_Texte_Cx3_Text_3), 4=Cx4_Text_4 (CM_CHA_Kombi_Texte_Cx4_Text_4), 5=Cx5_Text_5 (CM_CHA_Kombi_Texte_Cx5_Text_5), 6=Cx6_Text_6 (CM_CHA_Kombi_Texte_Cx6_Text_6), 7=Cx7_Text_7 (CM_CHA_Kombi_Texte_Cx7_Text_7), 8=Cx8_Text_8 (CM_CHA_Kombi_Texte_Cx8_Text_8), 9=Cx9_Text_9 (CM_CHA_Kombi_Texte_Cx9_Text_9), 10=Cxa_Text_10 (CM_CHA_Kombi_Texte_Cxa_Text_10), 11=Cxb_Text_11 (CM_CHA_Kombi_Texte_Cxb_Text_11), 12=Cxc_Text_12 (CM_CHA_Kombi_Texte_Cxc_Text_12), 13=Cxd_Text_13 (CM_CHA_Kombi_Texte_Cxd_Text_13), 14=Cxe_Text_14 (CM_CHA_Kombi_Texte_Cxe_Text_14), 15=Cxf_Text_15 (CM_CHA_Kombi_Texte_Cxf_Text_15)}, range raw 0..15, transfer-property=TRIGGERED-ON-CHANGE-WITHOUT-REPETITION  # Anzeige des aktuellen Charisma-Fahrprofiles im Kombi. Die Texte werden HUT-Spezifisch in einem Schnittstellen-LAH definiert.
          signal CHA_Ziel_FahrPr_KL_XIX_Charisma_03_XIX_E3V_EVCANFD: start 28, 4 bit, little-endian, data-type-policy=OVERRIDE, i-signal-type=PRIMITIVE, init-value=0, base-type=BT_CHA_Ziel_FahrPr_KL, compu {0=Cx0_keine_Funktion (CM_CHA_Ziel_FahrPr_KL_Cx0_keine_Funktion), 1=Cx1_Programm_1 (CM_CHA_Ziel_FahrPr_KL_Cx1_Programm_1), 2=Cx2_Programm_2 (CM_CHA_Ziel_FahrPr_KL_Cx2_Programm_2), 3=Cx3_Programm_3 (CM_CHA_Ziel_FahrPr_KL_Cx3_Programm_3), 4=Cx4_Programm_4 (CM_CHA_Ziel_FahrPr_KL_Cx4_Programm_4), 5=Cx5_Programm_5 (CM_CHA_Ziel_FahrPr_KL_Cx5_Programm_5), 6=Cx6_Programm_6 (CM_CHA_Ziel_FahrPr_KL_Cx6_Programm_6), 7=Cx7_Programm_7 (CM_CHA_Ziel_FahrPr_KL_Cx7_Programm_7), 8=Cx8_Programm_8 (CM_CHA_Ziel_FahrPr_KL_Cx8_Programm_8), 9=Cx9_Programm_9 (CM_CHA_Ziel_FahrPr_KL_Cx9_Programm_9), 10=Cxa_Programm_10 (CM_CHA_Ziel_FahrPr_KL_Cxa_Programm_10), 11=Cxb_Programm_11 (CM_CHA_Ziel_FahrPr_KL_Cxb_Programm_11), 12=Cxc_Programm_12 (CM_CHA_Ziel_FahrPr_KL_Cxc_Programm_12), 13=Cxd_Programm_13 (CM_CHA_Ziel_FahrPr_KL_Cxd_Programm_13), 14=Cxe_Programm_14 (CM_CHA_Ziel_FahrPr_KL_Cxe_Programm_14), 15=Cxf_Programm_15 (CM_CHA_Ziel_FahrPr_KL_Cxf_Programm_15)}, range raw 0..15, transfer-property=TRIGGERED-ON-CHANGE-WITHOUT-REPETITION, to Klima(timeout 5 s)  # Anforderung Ziel-Fahrprogramm Klima
          signal CHA_Ziel_FahrPr_HSP_XIX_Charisma_03_XIX_E3V_EVCANFD: start 32, 4 bit, little-endian, data-type-policy=OVERRIDE, i-signal-type=PRIMITIVE, init-value=0, base-type=BT_CHA_Ziel_FahrPr_HSP, compu {0=Cx0_keine_Funktion (CM_CHA_Ziel_FahrPr_HSP_Cx0_keine_Funktion), 1=Cx1_Programm_1 (CM_CHA_Ziel_FahrPr_HSP_Cx1_Programm_1), 2=Cx2_Programm_2 (CM_CHA_Ziel_FahrPr_HSP_Cx2_Programm_2), 3=Cx3_Programm_3 (CM_CHA_Ziel_FahrPr_HSP_Cx3_Programm_3), 4=Cx4_Programm_4 (CM_CHA_Ziel_FahrPr_HSP_Cx4_Programm_4), 5=Cx5_Programm_5 (CM_CHA_Ziel_FahrPr_HSP_Cx5_Programm_5), 6=Cx6_Programm_6 (CM_CHA_Ziel_FahrPr_HSP_Cx6_Programm_6), 7=Cx7_Programm_7 (CM_CHA_Ziel_FahrPr_HSP_Cx7_Programm_7), 8=Cx8_Programm_8 (CM_CHA_Ziel_FahrPr_HSP_Cx8_Programm_8), 9=Cx9_Programm_9 (CM_CHA_Ziel_FahrPr_HSP_Cx9_Programm_9), 10=Cxa_Programm_10 (CM_CHA_Ziel_FahrPr_HSP_Cxa_Programm_10), 11=Cxb_Programm_11 (CM_CHA_Ziel_FahrPr_HSP_Cxb_Programm_11), 12=Cxc_Programm_12 (CM_CHA_Ziel_FahrPr_HSP_Cxc_Programm_12), 13=Cxd_Programm_13 (CM_CHA_Ziel_FahrPr_HSP_Cxd_Programm_13), 14=Cxe_Programm_14 (CM_CHA_Ziel_FahrPr_HSP_Cxe_Programm_14), 15=Cxf_Programm_15 (CM_CHA_Ziel_FahrPr_HSP_Cxf_Programm_15)}, range raw 0..15, transfer-property=TRIGGERED-ON-CHANGE-WITHOUT-REPETITION  # Anforderung Ziel-Fahrprogramm Heckspoiler
          signal CHA_StCurProfDft_XIX_Charisma_03_XIX_E3V_EVCANFD: start 36, 2 bit, little-endian, data-type-policy=OVERRIDE, i-signal-type=PRIMITIVE, init-value=0, base-type=BT_CHA_StCurProfDft, compu {0=Cx0_Init (CM_CHA_StCurProfDft_Cx0_Init), 1=Cx1_profile_is_not_configurable (CM_CHA_StCurProfDft_Cx1_profile_is_not_configurable), 2=Cx2_profile_is_default (CM_CHA_StCurProfDft_Cx2_profile_is_default), 3=Cx3_profile_is_not_default (CM_CHA_StCurProfDft_Cx3_profile_is_not_default)}, range raw 0..3, transfer-property=TRIGGERED-ON-CHANGE-WITHOUT-REPETITION  # Signal indicates if the current Charisma-profile
          signal CHA_Ziel_FahrPr_RWB_XIX_Charisma_03_XIX_E3V_EVCANFD: start 40, 4 bit, little-endian, data-type-policy=OVERRIDE, i-signal-type=PRIMITIVE, init-value=0, base-type=BT_CHA_Ziel_FahrPr_RWB, compu {0=Cx0_keine_Funktion (CM_CHA_Ziel_FahrPr_RWB_Cx0_keine_Funktion), 1=Cx1_Programm_1 (CM_CHA_Ziel_FahrPr_RWB_Cx1_Programm_1), 2=Cx2_Programm_2 (CM_CHA_Ziel_FahrPr_RWB_Cx2_Programm_2), 3=Cx3_Programm_3 (CM_CHA_Ziel_FahrPr_RWB_Cx3_Programm_3), 4=Cx4_Programm_4 (CM_CHA_Ziel_FahrPr_RWB_Cx4_Programm_4), 5=Cx5_Programm_5 (CM_CHA_Ziel_FahrPr_RWB_Cx5_Programm_5), 6=Cx6_Programm_6 (CM_CHA_Ziel_FahrPr_RWB_Cx6_Programm_6), 7=Cx7_Programm_7 (CM_CHA_Ziel_FahrPr_RWB_Cx7_Programm_7), 8=Cx8_Programm_8 (CM_CHA_Ziel_FahrPr_RWB_Cx8_Programm_8), 9=Cx9_Programm_9 (CM_CHA_Ziel_FahrPr_RWB_Cx9_Programm_9), 10=Cxa_Programm_10 (CM_CHA_Ziel_FahrPr_RWB_Cxa_Programm_10), 11=Cxb_Programm_11 (CM_CHA_Ziel_FahrPr_RWB_Cxb_Programm_11), 12=Cxc_Programm_12 (CM_CHA_Ziel_FahrPr_RWB_Cxc_Programm_12), 13=Cxd_Programm_13 (CM_CHA_Ziel_FahrPr_RWB_Cxd_Programm_13), 14=Cxe_Programm_14 (CM_CHA_Ziel_FahrPr_RWB_Cxe_Programm_14), 15=Cxf_Programm_15 (CM_CHA_Ziel_FahrPr_RWB_Cxf_Programm_15)}, range raw 0..15, transfer-property=TRIGGERED-ON-CHANGE-WITHOUT-REPETITION  # Anforderung Zielfahrprogramm Reichweitenberechnung (RWB)
          signal CHA_Ziel_FahrPr_03_01_XIX_Charisma_03_XIX_E3V_EVCANFD: start 44, 4 bit, little-endian, data-type-policy=OVERRIDE, i-signal-type=PRIMITIVE, init-value=0, base-type=BT_CHA_Ziel_FahrPr_03_01, compu {0=Cx0_keine_Funktion (CM_CHA_Ziel_FahrPr_03_01_Cx0_keine_Funktion), 1=Cx1_Programm_1 (CM_CHA_Ziel_FahrPr_03_01_Cx1_Programm_1), 2=Cx2_Programm_2 (CM_CHA_Ziel_FahrPr_03_01_Cx2_Programm_2), 3=Cx3_Programm_3 (CM_CHA_Ziel_FahrPr_03_01_Cx3_Programm_3), 4=Cx4_Programm_4 (CM_CHA_Ziel_FahrPr_03_01_Cx4_Programm_4), 5=Cx5_Programm_5 (CM_CHA_Ziel_FahrPr_03_01_Cx5_Programm_5), 6=Cx6_Programm_6 (CM_CHA_Ziel_FahrPr_03_01_Cx6_Programm_6), 7=Cx7_Programm_7 (CM_CHA_Ziel_FahrPr_03_01_Cx7_Programm_7), 8=Cx8_Programm_8 (CM_CHA_Ziel_FahrPr_03_01_Cx8_Programm_8), 9=Cx9_Programm_9 (CM_CHA_Ziel_FahrPr_03_01_Cx9_Programm_9), 10=Cxa_Programm_10 (CM_CHA_Ziel_FahrPr_03_01_Cxa_Programm_10), 11=Cxb_Programm_11 (CM_CHA_Ziel_FahrPr_03_01_Cxb_Programm_11), 12=Cxc_Programm_12 (CM_CHA_Ziel_FahrPr_03_01_Cxc_Programm_12), 13=Cxd_Programm_13 (CM_CHA_Ziel_FahrPr_03_01_Cxd_Programm_13), 14=Cxe_Programm_14 (CM_CHA_Ziel_FahrPr_03_01_Cxe_Programm_14), 15=Cxf_Programm_15 (CM_CHA_Ziel_FahrPr_03_01_Cxf_Programm_15)}, range raw 0..15, transfer-property=TRIGGERED-ON-CHANGE-WITHOUT-REPETITION  # reserviert für Anforderung Ziel-Fahrprogramm
          signal CHA_Ziel_FahrPr_03_02_XIX_Charisma_03_XIX_E3V_EVCANFD: start 48, 4 bit, little-endian, data-type-policy=OVERRIDE, i-signal-type=PRIMITIVE, init-value=0, base-type=BT_CHA_Ziel_FahrPr_03_02, compu {0=Cx0_keine_Funktion (CM_CHA_Ziel_FahrPr_03_02_Cx0_keine_Funktion), 1=Cx1_Programm_1 (CM_CHA_Ziel_FahrPr_03_02_Cx1_Programm_1), 2=Cx2_Programm_2 (CM_CHA_Ziel_FahrPr_03_02_Cx2_Programm_2), 3=Cx3_Programm_3 (CM_CHA_Ziel_FahrPr_03_02_Cx3_Programm_3), 4=Cx4_Programm_4 (CM_CHA_Ziel_FahrPr_03_02_Cx4_Programm_4), 5=Cx5_Programm_5 (CM_CHA_Ziel_FahrPr_03_02_Cx5_Programm_5), 6=Cx6_Programm_6 (CM_CHA_Ziel_FahrPr_03_02_Cx6_Programm_6), 7=Cx7_Programm_7 (CM_CHA_Ziel_FahrPr_03_02_Cx7_Programm_7), 8=Cx8_Programm_8 (CM_CHA_Ziel_FahrPr_03_02_Cx8_Programm_8), 9=Cx9_Programm_9 (CM_CHA_Ziel_FahrPr_03_02_Cx9_Programm_9), 10=Cxa_Programm_10 (CM_CHA_Ziel_FahrPr_03_02_Cxa_Programm_10), 11=Cxb_Programm_11 (CM_CHA_Ziel_FahrPr_03_02_Cxb_Programm_11), 12=Cxc_Programm_12 (CM_CHA_Ziel_FahrPr_03_02_Cxc_Programm_12), 13=Cxd_Programm_13 (CM_CHA_Ziel_FahrPr_03_02_Cxd_Programm_13), 14=Cxe_Programm_14 (CM_CHA_Ziel_FahrPr_03_02_Cxe_Programm_14), 15=Cxf_Programm_15 (CM_CHA_Ziel_FahrPr_03_02_Cxf_Programm_15)}, range raw 0..15, transfer-property=TRIGGERED-ON-CHANGE-WITHOUT-REPETITION  # reserviert für Anforderung Ziel-Fahrprogramm
          signal CHA_Current_Mode_XIX_Charisma_03_XIX_E3V_EVCANFD: start 52, 4 bit, little-endian, data-type-policy=OVERRIDE, i-signal-type=PRIMITIVE, init-value=0, base-type=BT_CHA_Current_Mode, compu {0=Cx0_keine_Funktion (CM_CHA_Current_Mode_Cx0_keine_Funktion), 1=Cx1_Programm_1 (CM_CHA_Current_Mode_Cx1_Programm_1), 2=Cx2_Programm_2 (CM_CHA_Current_Mode_Cx2_Programm_2), 3=Cx3_Programm_3 (CM_CHA_Current_Mode_Cx3_Programm_3), 4=Cx4_Programm_4 (CM_CHA_Current_Mode_Cx4_Programm_4), 5=Cx5_Programm_5 (CM_CHA_Current_Mode_Cx5_Programm_5), 6=Cx6_Programm_6 (CM_CHA_Current_Mode_Cx6_Programm_6), 7=Cx7_Programm_7 (CM_CHA_Current_Mode_Cx7_Programm_7), 8=Cx8_Programm_8 (CM_CHA_Current_Mode_Cx8_Programm_8), 9=Cx9_Programm_9 (CM_CHA_Current_Mode_Cx9_Programm_9), 10=Cxa_Programm_10 (CM_CHA_Current_Mode_Cxa_Programm_10), 11=Cxb_Programm_11 (CM_CHA_Current_Mode_Cxb_Programm_11), 12=Cxc_Programm_12 (CM_CHA_Current_Mode_Cxc_Programm_12), 13=Cxd_Programm_13 (CM_CHA_Current_Mode_Cxd_Programm_13), 14=Cxe_Programm_14 (CM_CHA_Current_Mode_Cxe_Programm_14), 15=Cxf_Programm_15 (CM_CHA_Current_Mode_Cxf_Programm_15)}, range raw 0..15, transfer-property=TRIGGERED-ON-CHANGE-WITHOUT-REPETITION  # Aktuell eingestelltes Charisma Fahrprogramm
          signal CHA_Ziel_FahrPr_HVBatt_XIX_Charisma_03_XIX_E3V_EVCANFD: start 56, 4 bit, little-endian, data-type-policy=OVERRIDE, i-signal-type=PRIMITIVE, init-value=0, base-type=BT_CHA_Ziel_FahrPr_HVBatt, compu {0=Cx0_keine_Funktion (CM_CHA_Ziel_FahrPr_HVBatt_Cx0_keine_Funktion), 1=Cx1_Programm_1 (CM_CHA_Ziel_FahrPr_HVBatt_Cx1_Programm_1), 2=Cx2_Programm_2 (CM_CHA_Ziel_FahrPr_HVBatt_Cx2_Programm_2), 3=Cx3_Programm_3 (CM_CHA_Ziel_FahrPr_HVBatt_Cx3_Programm_3), 4=Cx4_Programm_4 (CM_CHA_Ziel_FahrPr_HVBatt_Cx4_Programm_4), 5=Cx5_Programm_5 (CM_CHA_Ziel_FahrPr_HVBatt_Cx5_Programm_5), 6=Cx6_Programm_6 (CM_CHA_Ziel_FahrPr_HVBatt_Cx6_Programm_6), 7=Cx7_Programm_7 (CM_CHA_Ziel_FahrPr_HVBatt_Cx7_Programm_7), 8=Cx8_Programm_8 (CM_CHA_Ziel_FahrPr_HVBatt_Cx8_Programm_8), 9=Cx9_Programm_9 (CM_CHA_Ziel_FahrPr_HVBatt_Cx9_Programm_9), 10=Cxa_Programm_10 (CM_CHA_Ziel_FahrPr_HVBatt_Cxa_Programm_10), 11=Cxb_Programm_11 (CM_CHA_Ziel_FahrPr_HVBatt_Cxb_Programm_11), 12=Cxc_Programm_12 (CM_CHA_Ziel_FahrPr_HVBatt_Cxc_Programm_12), 13=Cxd_Programm_13 (CM_CHA_Ziel_FahrPr_HVBatt_Cxd_Programm_13), 14=Cxe_Programm_14 (CM_CHA_Ziel_FahrPr_HVBatt_Cxe_Programm_14), 15=Cxf_Programm_15 (CM_CHA_Ziel_FahrPr_HVBatt_Cxf_Programm_15)}, range raw 0..15, transfer-property=TRIGGERED-ON-CHANGE-WITHOUT-REPETITION  # Signal zur Ansteuerung des Teilnehmers Hochvolt Batterie durch den Charisma-Koordinator
          signal CHA_Kombi_Texte_02_XIX_Charisma_03_XIX_E3V_EVCANFD: start 60, 4 bit, little-endian, data-type-policy=OVERRIDE, i-signal-type=PRIMITIVE, init-value=0, base-type=BT_CHA_Kombi_Texte_02, compu {0=Cx0_Init (CM_CHA_Kombi_Texte_02_Cx0_Init), 1=Cx1_Text_1 (CM_CHA_Kombi_Texte_02_Cx1_Text_1), 2=Cx2_Text_2 (CM_CHA_Kombi_Texte_02_Cx2_Text_2), 3=Cx3_Text_3 (CM_CHA_Kombi_Texte_02_Cx3_Text_3), 4=Cx4_Text_4 (CM_CHA_Kombi_Texte_02_Cx4_Text_4), 5=Cx5_Text_5 (CM_CHA_Kombi_Texte_02_Cx5_Text_5), 6=Cx6_Text_6 (CM_CHA_Kombi_Texte_02_Cx6_Text_6), 7=Cx7_Text_7 (CM_CHA_Kombi_Texte_02_Cx7_Text_7), 8=Cx8_Text_8 (CM_CHA_Kombi_Texte_02_Cx8_Text_8), 9=Cx9_Text_9 (CM_CHA_Kombi_Texte_02_Cx9_Text_9), 10=Cxa_Text_10 (CM_CHA_Kombi_Texte_02_Cxa_Text_10), 11=Cxb_Text_11 (CM_CHA_Kombi_Texte_02_Cxb_Text_11), 12=Cxc_Text_12 (CM_CHA_Kombi_Texte_02_Cxc_Text_12), 13=Cxd_Text_13 (CM_CHA_Kombi_Texte_02_Cxd_Text_13), 14=Cxe_Text_14 (CM_CHA_Kombi_Texte_02_Cxe_Text_14), 15=Cxf_Text_15 (CM_CHA_Kombi_Texte_02_Cxf_Text_15)}, range raw 0..15, transfer-property=TRIGGERED-ON-CHANGE-WITHOUT-REPETITION  # Anzeige von Hinweistexten bzgl. Charismaumschaltungen im Kombi. Die Texte werden HUT-Spezifisch in einem Schnittstellen-LAH definiert.
      frame DEV_Klima_BET_Req_01_XIX_E3V_EVCANFD: id 0x1BFE3228, to Klima, frame-length=64, can-addressing-mode=EXTENDED, can-frame-rx-behavior=CAN-FD, can-frame-tx-behavior=CAN-FD
        user defined pdu CDD_DEV_Klima_BET_Req_01_XIX_E3V_EVCANFD: length=64, cdd-type=EID
      frame DEV_Klima_BET_Resp_01_XIX_E3V_EVCANFD: id 0x1BFE3229, from Klima, frame-length=64, can-addressing-mode=EXTENDED, can-frame-rx-behavior=CAN-FD, can-frame-tx-behavior=CAN-FD
        user defined pdu CDD_DEV_Klima_BET_Resp_01_XIX_E3V_EVCANFD: length=64, cdd-type=EID
      frame DEV_Klima_Tx_00_XIX_E3V_EVCANFD: id 0x1BFE3200, from Klima, frame-length=8, can-addressing-mode=EXTENDED, can-frame-rx-behavior=CAN-FD, can-frame-tx-behavior=CAN-FD
        user defined pdu CDD_DEV_Klima_Tx_00_XIX_E3V_EVCANFD: length=8, cdd-type=EID
      frame DEV_Klima_Tx_01_XIX_E3V_EVCANFD: id 0x1BFE3201, from Klima, frame-length=8, can-addressing-mode=EXTENDED, can-frame-rx-behavior=CAN-FD, can-frame-tx-behavior=CAN-FD
        user defined pdu CDD_DEV_Klima_Tx_01_XIX_E3V_EVCANFD: length=8, cdd-type=EID
      frame DEV_Klima_Tx_02_XIX_E3V_EVCANFD: id 0x1BFE3202, from Klima, frame-length=8, can-addressing-mode=EXTENDED, can-frame-rx-behavior=CAN-FD, can-frame-tx-behavior=CAN-FD
        user defined pdu CDD_DEV_Klima_Tx_02_XIX_E3V_EVCANFD: length=8, cdd-type=EID
      frame DEV_Klima_Tx_03_XIX_E3V_EVCANFD: id 0x1BFE3203, from Klima, frame-length=8, can-addressing-mode=EXTENDED, can-frame-rx-behavior=CAN-FD, can-frame-tx-behavior=CAN-FD
        user defined pdu CDD_DEV_Klima_Tx_03_XIX_E3V_EVCANFD: length=8, cdd-type=EID
      frame DEV_Klima_Tx_04_XIX_E3V_EVCANFD: id 0x1BFE3204, from Klima, frame-length=8, can-addressing-mode=EXTENDED, can-frame-rx-behavior=CAN-FD, can-frame-tx-behavior=CAN-FD
        user defined pdu CDD_DEV_Klima_Tx_04_XIX_E3V_EVCANFD: length=8, cdd-type=EID
      frame DEV_Klima_Tx_05_XIX_E3V_EVCANFD: id 0x1BFE3205, from Klima, frame-length=8, can-addressing-mode=EXTENDED, can-frame-rx-behavior=CAN-FD, can-frame-tx-behavior=CAN-FD
        user defined pdu CDD_DEV_Klima_Tx_05_XIX_E3V_EVCANFD: length=8, cdd-type=EID
      frame DEV_Klima_Tx_06_XIX_E3V_EVCANFD: id 0x1BFE3206, from Klima, frame-length=8, can-addressing-mode=EXTENDED, can-frame-rx-behavior=CAN-FD, can-frame-tx-behavior=CAN-FD
        user defined pdu CDD_DEV_Klima_Tx_06_XIX_E3V_EVCANFD: length=8, cdd-type=EID
      frame DEV_Klima_Tx_07_XIX_E3V_EVCANFD: id 0x1BFE3207, from Klima, frame-length=8, can-addressing-mode=EXTENDED, can-frame-rx-behavior=CAN-FD, can-frame-tx-behavior=CAN-FD
        user defined pdu CDD_DEV_Klima_Tx_07_XIX_E3V_EVCANFD: length=8, cdd-type=EID
      frame DEV_Klima_Tx_08_XIX_E3V_EVCANFD: id 0x1BFE3208, from Klima, frame-length=8, can-addressing-mode=EXTENDED, can-frame-rx-behavior=CAN-FD, can-frame-tx-behavior=CAN-FD
        user defined pdu CDD_DEV_Klima_Tx_08_XIX_E3V_EVCANFD: length=8, cdd-type=EID
      frame DEV_Klima_Tx_09_XIX_E3V_EVCANFD: id 0x1BFE3209, from Klima, frame-length=8, can-addressing-mode=EXTENDED, can-frame-rx-behavior=CAN-FD, can-frame-tx-behavior=CAN-FD
        user defined pdu CDD_DEV_Klima_Tx_09_XIX_E3V_EVCANFD: length=8, cdd-type=EID
      frame DEV_Klima_Tx_0A_XIX_E3V_EVCANFD: id 0x1BFE320A, from Klima, frame-length=8, can-addressing-mode=EXTENDED, can-frame-rx-behavior=CAN-FD, can-frame-tx-behavior=CAN-FD
        user defined pdu CDD_DEV_Klima_Tx_0A_XIX_E3V_EVCANFD: length=8, cdd-type=EID
      frame DEV_Klima_Tx_0B_XIX_E3V_EVCANFD: id 0x1BFE320B, from Klima, frame-length=8, can-addressing-mode=EXTENDED, can-frame-rx-behavior=CAN-FD, can-frame-tx-behavior=CAN-FD
        user defined pdu CDD_DEV_Klima_Tx_0B_XIX_E3V_EVCANFD: length=8, cdd-type=EID
      frame DEV_Klima_Tx_0C_XIX_E3V_EVCANFD: id 0x1BFE320C, from Klima, frame-length=8, can-addressing-mode=EXTENDED, can-frame-rx-behavior=CAN-FD, can-frame-tx-behavior=CAN-FD
        user defined pdu CDD_DEV_Klima_Tx_0C_XIX_E3V_EVCANFD: length=8, cdd-type=EID
      frame DEV_Klima_Tx_0D_XIX_E3V_EVCANFD: id 0x1BFE320D, from Klima, frame-length=8, can-addressing-mode=EXTENDED, can-frame-rx-behavior=CAN-FD, can-frame-tx-behavior=CAN-FD
        user defined pdu CDD_DEV_Klima_Tx_0D_XIX_E3V_EVCANFD: length=8, cdd-type=EID
      frame DEV_Klima_Tx_0E_XIX_E3V_EVCANFD: id 0x1BFE320E, from Klima, frame-length=8, can-addressing-mode=EXTENDED, can-frame-rx-behavior=CAN-FD, can-frame-tx-behavior=CAN-FD
        user defined pdu CDD_DEV_Klima_Tx_0E_XIX_E3V_EVCANFD: length=8, cdd-type=EID
      frame DEV_Klima_Tx_0F_XIX_E3V_EVCANFD: id 0x1BFE320F, from Klima, frame-length=8, can-addressing-mode=EXTENDED, can-frame-rx-behavior=CAN-FD, can-frame-tx-behavior=CAN-FD
        user defined pdu CDD_DEV_Klima_Tx_0F_XIX_E3V_EVCANFD: length=8, cdd-type=EID
      frame DEV_Klima_Tx_10_XIX_E3V_EVCANFD: id 0x1BFE3210, from Klima, frame-length=8, can-addressing-mode=EXTENDED, can-frame-rx-behavior=CAN-FD, can-frame-tx-behavior=CAN-FD
        user defined pdu CDD_DEV_Klima_Tx_10_XIX_E3V_EVCANFD: length=8, cdd-type=EID
      frame DEV_Klima_Tx_11_XIX_E3V_EVCANFD: id 0x1BFE3211, from Klima, frame-length=8, can-addressing-mode=EXTENDED, can-frame-rx-behavior=CAN-FD, can-frame-tx-behavior=CAN-FD
        user defined pdu CDD_DEV_Klima_Tx_11_XIX_E3V_EVCANFD: length=8, cdd-type=EID
      frame DEV_Klima_Tx_12_XIX_E3V_EVCANFD: id 0x1BFE3212, from Klima, frame-length=8, can-addressing-mode=EXTENDED, can-frame-rx-behavior=CAN-FD, can-frame-tx-behavior=CAN-FD
        user defined pdu CDD_DEV_Klima_Tx_12_XIX_E3V_EVCANFD: length=8, cdd-type=EID
      frame DEV_Klima_Tx_13_XIX_E3V_EVCANFD: id 0x1BFE3213, from Klima, frame-length=8, can-addressing-mode=EXTENDED, can-frame-rx-behavior=CAN-FD, can-frame-tx-behavior=CAN-FD
        user defined pdu CDD_DEV_Klima_Tx_13_XIX_E3V_EVCANFD: length=8, cdd-type=EID
      frame DEV_Klima_Tx_14_XIX_E3V_EVCANFD: id 0x1BFE3214, from Klima, frame-length=8, can-addressing-mode=EXTENDED, can-frame-rx-behavior=CAN-FD, can-frame-tx-behavior=CAN-FD
        user defined pdu CDD_DEV_Klima_Tx_14_XIX_E3V_EVCANFD: length=8, cdd-type=EID
      frame DEV_Klima_Tx_15_XIX_E3V_EVCANFD: id 0x1BFE3215, from Klima, frame-length=8, can-addressing-mode=EXTENDED, can-frame-rx-behavior=CAN-FD, can-frame-tx-behavior=CAN-FD
        user defined pdu CDD_DEV_Klima_Tx_15_XIX_E3V_EVCANFD: length=8, cdd-type=EID
      frame DEV_Klima_Tx_16_XIX_E3V_EVCANFD: id 0x1BFE3216, from Klima, frame-length=8, can-addressing-mode=EXTENDED, can-frame-rx-behavior=CAN-FD, can-frame-tx-behavior=CAN-FD
        user defined pdu CDD_DEV_Klima_Tx_16_XIX_E3V_EVCANFD: length=8, cdd-type=EID
      frame DEV_Klima_Tx_17_XIX_E3V_EVCANFD: id 0x1BFE3217, from Klima, frame-length=8, can-addressing-mode=EXTENDED, can-frame-rx-behavior=CAN-FD, can-frame-tx-behavior=CAN-FD
        user defined pdu CDD_DEV_Klima_Tx_17_XIX_E3V_EVCANFD: length=8, cdd-type=EID
      frame DEV_Klima_Tx_18_XIX_E3V_EVCANFD: id 0x1BFE3218, from Klima, frame-length=8, can-addressing-mode=EXTENDED, can-frame-rx-behavior=CAN-FD, can-frame-tx-behavior=CAN-FD
        user defined pdu CDD_DEV_Klima_Tx_18_XIX_E3V_EVCANFD: length=8, cdd-type=EID
      frame DEV_Klima_Tx_19_XIX_E3V_EVCANFD: id 0x1BFE3219, from Klima, frame-length=8, can-addressing-mode=EXTENDED, can-frame-rx-behavior=CAN-FD, can-frame-tx-behavior=CAN-FD
        user defined pdu CDD_DEV_Klima_Tx_19_XIX_E3V_EVCANFD: length=8, cdd-type=EID
      frame DEV_Klima_Tx_1A_XIX_E3V_EVCANFD: id 0x1BFE321A, from Klima, frame-length=8, can-addressing-mode=EXTENDED, can-frame-rx-behavior=CAN-FD, can-frame-tx-behavior=CAN-FD
        user defined pdu CDD_DEV_Klima_Tx_1A_XIX_E3V_EVCANFD: length=8, cdd-type=EID
      frame DEV_Klima_Tx_1B_XIX_E3V_EVCANFD: id 0x1BFE321B, from Klima, frame-length=8, can-addressing-mode=EXTENDED, can-frame-rx-behavior=CAN-FD, can-frame-tx-behavior=CAN-FD
        user defined pdu CDD_DEV_Klima_Tx_1B_XIX_E3V_EVCANFD: length=8, cdd-type=EID
      frame DEV_Klima_Tx_1C_XIX_E3V_EVCANFD: id 0x1BFE321C, from Klima, frame-length=8, can-addressing-mode=EXTENDED, can-frame-rx-behavior=CAN-FD, can-frame-tx-behavior=CAN-FD
        user defined pdu CDD_DEV_Klima_Tx_1C_XIX_E3V_EVCANFD: length=8, cdd-type=EID
      frame DEV_Klima_Tx_1D_XIX_E3V_EVCANFD: id 0x1BFE321D, from Klima, frame-length=8, can-addressing-mode=EXTENDED, can-frame-rx-behavior=CAN-FD, can-frame-tx-behavior=CAN-FD
        user defined pdu CDD_DEV_Klima_Tx_1D_XIX_E3V_EVCANFD: length=8, cdd-type=EID
      frame DEV_Klima_Tx_1E_XIX_E3V_EVCANFD: id 0x1BFE321E, from Klima, frame-length=8, can-addressing-mode=EXTENDED, can-frame-rx-behavior=CAN-FD, can-frame-tx-behavior=CAN-FD
        user defined pdu CDD_DEV_Klima_Tx_1E_XIX_E3V_EVCANFD: length=8, cdd-type=EID
      frame DEV_Klima_Tx_1F_XIX_E3V_EVCANFD: id 0x1BFE321F, from Klima, frame-length=8, can-addressing-mode=EXTENDED, can-frame-rx-behavior=CAN-FD, can-frame-tx-behavior=CAN-FD
        user defined pdu CDD_DEV_Klima_Tx_1F_XIX_E3V_EVCANFD: length=8, cdd-type=EID
      frame DEV_Klima_Tx_20_XIX_E3V_EVCANFD: id 0x1BFE3220, from Klima, frame-length=8, can-addressing-mode=EXTENDED, can-frame-rx-behavior=CAN-FD, can-frame-tx-behavior=CAN-FD
        user defined pdu CDD_DEV_Klima_Tx_20_XIX_E3V_EVCANFD: length=8, cdd-type=EID
      frame DEV_Klima_Tx_21_XIX_E3V_EVCANFD: id 0x1BFE3221, from Klima, frame-length=8, can-addressing-mode=EXTENDED, can-frame-rx-behavior=CAN-FD, can-frame-tx-behavior=CAN-FD
        user defined pdu CDD_DEV_Klima_Tx_21_XIX_E3V_EVCANFD: length=8, cdd-type=EID
      frame DEV_Klima_Tx_22_XIX_E3V_EVCANFD: id 0x1BFE3222, from Klima, frame-length=8, can-addressing-mode=EXTENDED, can-frame-rx-behavior=CAN-FD, can-frame-tx-behavior=CAN-FD
        user defined pdu CDD_DEV_Klima_Tx_22_XIX_E3V_EVCANFD: length=8, cdd-type=EID
      frame DEV_Klima_Tx_23_XIX_E3V_EVCANFD: id 0x1BFE3223, from Klima, frame-length=8, can-addressing-mode=EXTENDED, can-frame-rx-behavior=CAN-FD, can-frame-tx-behavior=CAN-FD
        user defined pdu CDD_DEV_Klima_Tx_23_XIX_E3V_EVCANFD: length=8, cdd-type=EID
      frame DEV_Klima_Tx_24_XIX_E3V_EVCANFD: id 0x1BFE3224, from Klima, frame-length=8, can-addressing-mode=EXTENDED, can-frame-rx-behavior=CAN-FD, can-frame-tx-behavior=CAN-FD
        user defined pdu CDD_DEV_Klima_Tx_24_XIX_E3V_EVCANFD: length=8, cdd-type=EID
      frame DEV_Klima_Tx_25_XIX_E3V_EVCANFD: id 0x1BFE3225, from Klima, frame-length=8, can-addressing-mode=EXTENDED, can-frame-rx-behavior=CAN-FD, can-frame-tx-behavior=CAN-FD
        user defined pdu CDD_DEV_Klima_Tx_25_XIX_E3V_EVCANFD: length=8, cdd-type=EID
      frame DEV_Klima_Tx_26_XIX_E3V_EVCANFD: id 0x1BFE3226, from Klima, frame-length=8, can-addressing-mode=EXTENDED, can-frame-rx-behavior=CAN-FD, can-frame-tx-behavior=CAN-FD
        user defined pdu CDD_DEV_Klima_Tx_26_XIX_E3V_EVCANFD: length=8, cdd-type=EID
      frame DEV_Klima_Tx_27_XIX_E3V_EVCANFD: id 0x1BFE3227, from Klima, frame-length=8, can-addressing-mode=EXTENDED, can-frame-rx-behavior=CAN-FD, can-frame-tx-behavior=CAN-FD
        user defined pdu CDD_DEV_Klima_Tx_27_XIX_E3V_EVCANFD: length=8, cdd-type=EID
      frame DEV_Klima_Tx_2C_XIX_E3V_EVCANFD: id 0x1BFE322C, from Klima, frame-length=8, can-addressing-mode=EXTENDED, can-frame-rx-behavior=CAN-FD, can-frame-tx-behavior=CAN-FD
        user defined pdu CDD_DEV_Klima_Tx_2C_XIX_E3V_EVCANFD: length=8, cdd-type=EID
      frame DEV_Klima_Tx_2D_XIX_E3V_EVCANFD: id 0x1BFE322D, from Klima, frame-length=8, can-addressing-mode=EXTENDED, can-frame-rx-behavior=CAN-FD, can-frame-tx-behavior=CAN-FD
        user defined pdu CDD_DEV_Klima_Tx_2D_XIX_E3V_EVCANFD: length=8, cdd-type=EID
      frame DEV_Klima_Tx_2E_XIX_E3V_EVCANFD: id 0x1BFE322E, from Klima, frame-length=8, can-addressing-mode=EXTENDED, can-frame-rx-behavior=CAN-FD, can-frame-tx-behavior=CAN-FD
        user defined pdu CDD_DEV_Klima_Tx_2E_XIX_E3V_EVCANFD: length=8, cdd-type=EID
      frame DEV_Klima_Tx_2F_XIX_E3V_EVCANFD: id 0x1BFE322F, from Klima, frame-length=8, can-addressing-mode=EXTENDED, can-frame-rx-behavior=CAN-FD, can-frame-tx-behavior=CAN-FD
        user defined pdu CDD_DEV_Klima_Tx_2F_XIX_E3V_EVCANFD: length=8, cdd-type=EID
      frame DEV_Klima_Tx_30_XIX_E3V_EVCANFD: id 0x1BFE3230, from Klima, frame-length=8, can-addressing-mode=EXTENDED, can-frame-rx-behavior=CAN-FD, can-frame-tx-behavior=CAN-FD
        user defined pdu CDD_DEV_Klima_Tx_30_XIX_E3V_EVCANFD: length=8, cdd-type=EID
      frame DEV_Klima_Tx_31_XIX_E3V_EVCANFD: id 0x1BFE3231, from Klima, frame-length=8, can-addressing-mode=EXTENDED, can-frame-rx-behavior=CAN-FD, can-frame-tx-behavior=CAN-FD
        user defined pdu CDD_DEV_Klima_Tx_31_XIX_E3V_EVCANFD: length=8, cdd-type=EID
      frame DEV_Klima_Tx_32_XIX_E3V_EVCANFD: id 0x1BFE3232, from Klima, frame-length=8, can-addressing-mode=EXTENDED, can-frame-rx-behavior=CAN-FD, can-frame-tx-behavior=CAN-FD
        user defined pdu CDD_DEV_Klima_Tx_32_XIX_E3V_EVCANFD: length=8, cdd-type=EID
      frame DEV_Klima_Tx_33_XIX_E3V_EVCANFD: id 0x1BFE3233, from Klima, frame-length=8, can-addressing-mode=EXTENDED, can-frame-rx-behavior=CAN-FD, can-frame-tx-behavior=CAN-FD
        user defined pdu CDD_DEV_Klima_Tx_33_XIX_E3V_EVCANFD: length=8, cdd-type=EID
      frame DEV_Klima_Tx_34_XIX_E3V_EVCANFD: id 0x1BFE3234, from Klima, frame-length=8, can-addressing-mode=EXTENDED, can-frame-rx-behavior=CAN-FD, can-frame-tx-behavior=CAN-FD
        user defined pdu CDD_DEV_Klima_Tx_34_XIX_E3V_EVCANFD: length=8, cdd-type=EID
      frame DEV_Klima_Tx_35_XIX_E3V_EVCANFD: id 0x1BFE3235, from Klima, frame-length=8, can-addressing-mode=EXTENDED, can-frame-rx-behavior=CAN-FD, can-frame-tx-behavior=CAN-FD
        user defined pdu CDD_DEV_Klima_Tx_35_XIX_E3V_EVCANFD: length=8, cdd-type=EID
      frame DEV_Klima_Tx_36_XIX_E3V_EVCANFD: id 0x1BFE3236, from Klima, frame-length=8, can-addressing-mode=EXTENDED, can-frame-rx-behavior=CAN-FD, can-frame-tx-behavior=CAN-FD
        user defined pdu CDD_DEV_Klima_Tx_36_XIX_E3V_EVCANFD: length=8, cdd-type=EID
      frame DEV_Klima_Tx_37_XIX_E3V_EVCANFD: id 0x1BFE3237, from Klima, frame-length=8, can-addressing-mode=EXTENDED, can-frame-rx-behavior=CAN-FD, can-frame-tx-behavior=CAN-FD
        user defined pdu CDD_DEV_Klima_Tx_37_XIX_E3V_EVCANFD: length=8, cdd-type=EID
      frame DEV_Klima_Tx_38_XIX_E3V_EVCANFD: id 0x1BFE3238, from Klima, frame-length=8, can-addressing-mode=EXTENDED, can-frame-rx-behavior=CAN-FD, can-frame-tx-behavior=CAN-FD
        user defined pdu CDD_DEV_Klima_Tx_38_XIX_E3V_EVCANFD: length=8, cdd-type=EID
      frame DEV_Klima_Tx_39_XIX_E3V_EVCANFD: id 0x1BFE3239, from Klima, frame-length=8, can-addressing-mode=EXTENDED, can-frame-rx-behavior=CAN-FD, can-frame-tx-behavior=CAN-FD
        user defined pdu CDD_DEV_Klima_Tx_39_XIX_E3V_EVCANFD: length=8, cdd-type=EID
      frame DEV_Klima_Tx_3A_XIX_E3V_EVCANFD: id 0x1BFE323A, from Klima, frame-length=8, can-addressing-mode=EXTENDED, can-frame-rx-behavior=CAN-FD, can-frame-tx-behavior=CAN-FD
        user defined pdu CDD_DEV_Klima_Tx_3A_XIX_E3V_EVCANFD: length=8, cdd-type=EID
      frame DEV_Klima_Tx_3B_XIX_E3V_EVCANFD: id 0x1BFE323B, from Klima, frame-length=8, can-addressing-mode=EXTENDED, can-frame-rx-behavior=CAN-FD, can-frame-tx-behavior=CAN-FD
        user defined pdu CDD_DEV_Klima_Tx_3B_XIX_E3V_EVCANFD: length=8, cdd-type=EID
      frame DEV_Klima_Tx_3C_XIX_E3V_EVCANFD: id 0x1BFE323C, from Klima, frame-length=8, can-addressing-mode=EXTENDED, can-frame-rx-behavior=CAN-FD, can-frame-tx-behavior=CAN-FD
        user defined pdu CDD_DEV_Klima_Tx_3C_XIX_E3V_EVCANFD: length=8, cdd-type=EID
      frame DEV_Klima_Tx_3D_XIX_E3V_EVCANFD: id 0x1BFE323D, from Klima, frame-length=8, can-addressing-mode=EXTENDED, can-frame-rx-behavior=CAN-FD, can-frame-tx-behavior=CAN-FD
        user defined pdu CDD_DEV_Klima_Tx_3D_XIX_E3V_EVCANFD: length=8, cdd-type=EID
      frame DEV_Klima_Tx_3E_XIX_E3V_EVCANFD: id 0x1BFE323E, from Klima, frame-length=8, can-addressing-mode=EXTENDED, can-frame-rx-behavior=CAN-FD, can-frame-tx-behavior=CAN-FD
        user defined pdu CDD_DEV_Klima_Tx_3E_XIX_E3V_EVCANFD: length=8, cdd-type=EID
      frame DEV_Klima_Tx_3F_XIX_E3V_EVCANFD: id 0x1BFE323F, from Klima, frame-length=8, can-addressing-mode=EXTENDED, can-frame-rx-behavior=CAN-FD, can-frame-tx-behavior=CAN-FD
        user defined pdu CDD_DEV_Klima_Tx_3F_XIX_E3V_EVCANFD: length=8, cdd-type=EID
      frame DEV_Klima_Tx_40_XIX_E3V_EVCANFD: id 0x1BFE3240, from Klima, frame-length=8, can-addressing-mode=EXTENDED, can-frame-rx-behavior=CAN-FD, can-frame-tx-behavior=CAN-FD
        user defined pdu CDD_DEV_Klima_Tx_40_XIX_E3V_EVCANFD: length=8, cdd-type=EID
      frame DEV_Klima_Tx_41_XIX_E3V_EVCANFD: id 0x1BFE3241, from Klima, frame-length=8, can-addressing-mode=EXTENDED, can-frame-rx-behavior=CAN-FD, can-frame-tx-behavior=CAN-FD
        user defined pdu CDD_DEV_Klima_Tx_41_XIX_E3V_EVCANFD: length=8, cdd-type=EID
      frame DEV_Klima_Tx_42_XIX_E3V_EVCANFD: id 0x1BFE3242, from Klima, frame-length=8, can-addressing-mode=EXTENDED, can-frame-rx-behavior=CAN-FD, can-frame-tx-behavior=CAN-FD
        user defined pdu CDD_DEV_Klima_Tx_42_XIX_E3V_EVCANFD: length=8, cdd-type=EID
      frame DEV_Klima_Tx_43_XIX_E3V_EVCANFD: id 0x1BFE3243, from Klima, frame-length=8, can-addressing-mode=EXTENDED, can-frame-rx-behavior=CAN-FD, can-frame-tx-behavior=CAN-FD
        user defined pdu CDD_DEV_Klima_Tx_43_XIX_E3V_EVCANFD: length=8, cdd-type=EID
      frame DEV_Klima_Tx_44_XIX_E3V_EVCANFD: id 0x1BFE3244, from Klima, frame-length=8, can-addressing-mode=EXTENDED, can-frame-rx-behavior=CAN-FD, can-frame-tx-behavior=CAN-FD
        user defined pdu CDD_DEV_Klima_Tx_44_XIX_E3V_EVCANFD: length=8, cdd-type=EID
      frame DEV_Klima_Tx_45_XIX_E3V_EVCANFD: id 0x1BFE3245, from Klima, frame-length=8, can-addressing-mode=EXTENDED, can-frame-rx-behavior=CAN-FD, can-frame-tx-behavior=CAN-FD
        user defined pdu CDD_DEV_Klima_Tx_45_XIX_E3V_EVCANFD: length=8, cdd-type=EID
      frame DEV_Klima_Tx_46_XIX_E3V_EVCANFD: id 0x1BFE3246, from Klima, frame-length=8, can-addressing-mode=EXTENDED, can-frame-rx-behavior=CAN-FD, can-frame-tx-behavior=CAN-FD
        user defined pdu CDD_DEV_Klima_Tx_46_XIX_E3V_EVCANFD: length=8, cdd-type=EID
      frame DEV_Klima_Tx_47_XIX_E3V_EVCANFD: id 0x1BFE3247, from Klima, frame-length=8, can-addressing-mode=EXTENDED, can-frame-rx-behavior=CAN-FD, can-frame-tx-behavior=CAN-FD
        user defined pdu CDD_DEV_Klima_Tx_47_XIX_E3V_EVCANFD: length=8, cdd-type=EID
      frame DEV_Klima_Tx_48_XIX_E3V_EVCANFD: id 0x1BFE3248, from Klima, frame-length=8, can-addressing-mode=EXTENDED, can-frame-rx-behavior=CAN-FD, can-frame-tx-behavior=CAN-FD
        user defined pdu CDD_DEV_Klima_Tx_48_XIX_E3V_EVCANFD: length=8, cdd-type=EID
      frame DEV_Klima_Tx_49_XIX_E3V_EVCANFD: id 0x1BFE3249, from Klima, frame-length=8, can-addressing-mode=EXTENDED, can-frame-rx-behavior=CAN-FD, can-frame-tx-behavior=CAN-FD
        user defined pdu CDD_DEV_Klima_Tx_49_XIX_E3V_EVCANFD: length=8, cdd-type=EID
      frame DEV_Klima_Tx_4A_XIX_E3V_EVCANFD: id 0x1BFE324A, from Klima, frame-length=8, can-addressing-mode=EXTENDED, can-frame-rx-behavior=CAN-FD, can-frame-tx-behavior=CAN-FD
        user defined pdu CDD_DEV_Klima_Tx_4A_XIX_E3V_EVCANFD: length=8, cdd-type=EID
      frame DEV_Klima_Tx_4B_XIX_E3V_EVCANFD: id 0x1BFE324B, from Klima, frame-length=64, can-addressing-mode=EXTENDED, can-frame-rx-behavior=CAN-FD, can-frame-tx-behavior=CAN-FD
        user defined pdu CDD_DEV_Klima_Tx_4B_XIX_E3V_EVCANFD: length=64, cdd-type=EID
      frame DEV_Klima_Tx_4C_XIX_E3V_EVCANFD: id 0x1BFE324C, from Klima, frame-length=64, can-addressing-mode=EXTENDED, can-frame-rx-behavior=CAN-FD, can-frame-tx-behavior=CAN-FD
        user defined pdu CDD_DEV_Klima_Tx_4C_XIX_E3V_EVCANFD: length=64, cdd-type=EID
      frame DEV_Klima_Tx_4D_XIX_E3V_EVCANFD: id 0x1BFE324D, from Klima, frame-length=64, can-addressing-mode=EXTENDED, can-frame-rx-behavior=CAN-FD, can-frame-tx-behavior=CAN-FD
        user defined pdu CDD_DEV_Klima_Tx_4D_XIX_E3V_EVCANFD: length=64, cdd-type=EID
      frame DEV_Klima_Tx_4E_XIX_E3V_EVCANFD: id 0x1BFE324E, from Klima, frame-length=64, can-addressing-mode=EXTENDED, can-frame-rx-behavior=CAN-FD, can-frame-tx-behavior=CAN-FD
        user defined pdu CDD_DEV_Klima_Tx_4E_XIX_E3V_EVCANFD: length=64, cdd-type=EID
      frame DEV_Klima_Tx_4F_XIX_E3V_EVCANFD: id 0x1BFE324F, from Klima, frame-length=64, can-addressing-mode=EXTENDED, can-frame-rx-behavior=CAN-FD, can-frame-tx-behavior=CAN-FD
        user defined pdu CDD_DEV_Klima_Tx_4F_XIX_E3V_EVCANFD: length=64, cdd-type=EID
      frame DEV_Klima_Val_Req_02_XIX_E3V_EVCANFD: id 0x1BFE322A, to Klima, frame-length=8, can-addressing-mode=EXTENDED, can-frame-rx-behavior=CAN-FD, can-frame-tx-behavior=CAN-FD
        user defined pdu CDD_DEV_Klima_Val_Req_02_XIX_E3V_EVCANFD: length=8, cdd-type=EID
      frame DEV_Klima_Val_Resp_02_XIX_E3V_EVCANFD: id 0x1BFE322B, from Klima, frame-length=8, can-addressing-mode=EXTENDED, can-frame-rx-behavior=CAN-FD, can-frame-tx-behavior=CAN-FD
        user defined pdu CDD_DEV_Klima_Val_Resp_02_XIX_E3V_EVCANFD: length=8, cdd-type=EID
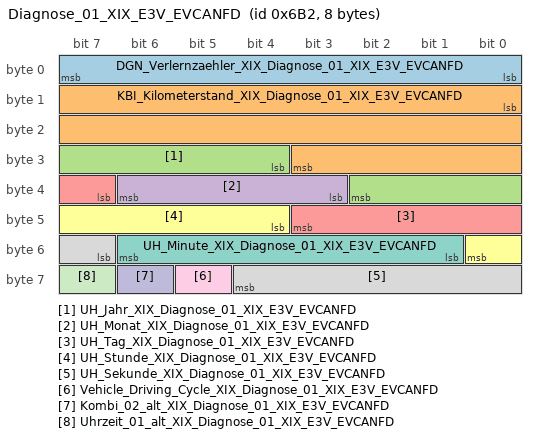
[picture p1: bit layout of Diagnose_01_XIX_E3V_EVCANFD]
      frame Diagnose_01_XIX_E3V_EVCANFD: id 0x6B2, to Klima, frame-length=8, can-addressing-mode=STANDARD, can-frame-rx-behavior=CAN-FD, can-frame-tx-behavior=CAN-FD
        pdu Diagnose_01_XIX_E3V_EVCANFD: length=8, transmission-mode-true-timing=cyclic-timing={time-offset=0.0, time-period=1.0}, unused-bit-pattern=0
          signal DGN_Verlernzaehler_XIX_Diagnose_01_XIX_E3V_EVCANFD: start 0, 8 bit, little-endian, data-type-policy=OVERRIDE, i-signal-type=PRIMITIVE, init-value=0, base-type=BT_DGN_Verlernzaehler, compu {phys=raw for raw 0..254, 255=Cxff_ungueltiger_Zaehlerstand_oder_kein_gueltiger_Fahrzyklus (CM_DGN_Verlernzaehler_Cxff_ungueltiger_Zaehlerstand_oder_kein_gueltiger_Fahrzyklus) (ungültiger Zählerstand oder kein gültiger Fahrzyklus)}, range phys 0..254, raw 0..255, transfer-property=PENDING, to Klima(timeout 5 s)  # wrap around 254 --> 0
          signal KBI_Kilometerstand_XIX_Diagnose_01_XIX_E3V_EVCANFD: start 8, 20 bit, little-endian, data-type-policy=OVERRIDE, i-signal-type=PRIMITIVE, init-value=1048574, base-type=BT_KBI_Kilometerstand, invalid-value=Invalid_KBI_Kilometerstand_XIX_Diagnose_01_XIX_E3V_EVCANFD:1048575, compu {phys=raw for raw 0..1048573, 1048574=Cxffffe_Init (CM_KBI_Kilometerstand_Cxffffe_Init), 1048575=Cxfffff_Fehler (CM_KBI_Kilometerstand_Cxfffff_Fehler); unit Unit_KiloMeter}, range phys 0..1048573 Unit_KiloMeter, raw 0..1048575, unit=Unit_KiloMeter, transfer-property=PENDING, to Klima(timeout 5 s)  # Fehler wird ausgegeben, falls Kilometerstand nicht restaurierbar
          signal UH_Jahr_XIX_Diagnose_01_XIX_E3V_EVCANFD: start 28, 7 bit, little-endian, data-type-policy=OVERRIDE, i-signal-type=PRIMITIVE, init-value=0, base-type=BT_UH_Jahr, compu {phys=raw+2000 for raw 0..127; unit Unit_Year}, range phys 2000..2127 Unit_Year, raw 0..127, unit=Unit_Year, transfer-property=PENDING, to Klima(timeout 5 s)
          signal UH_Monat_XIX_Diagnose_01_XIX_E3V_EVCANFD: start 35, 4 bit, little-endian, data-type-policy=OVERRIDE, i-signal-type=PRIMITIVE, init-value=0, base-type=BT_UH_Monat, invalid-value=Invalid_UH_Monat_XIX_Diagnose_01_XIX_E3V_EVCANFD:15, compu {0=Cx0_Init (CM_UH_Monat_Cx0_Init), phys=raw for raw 1..12, 14=Cxe_Relatives_Datum (CM_UH_Monat_Cxe_Relatives_Datum), 15=Cxf_Fehler (CM_UH_Monat_Cxf_Fehler); unit Unit_Month}, range phys 1..12 Unit_Month, raw 0..15, unit=Unit_Month, transfer-property=PENDING, to Klima(timeout 5 s)  # 0x0D, 0xF = Werte ungültig 0x0E = Relatives Datum (nur VW)
          signal UH_Tag_XIX_Diagnose_01_XIX_E3V_EVCANFD: start 39, 5 bit, little-endian, data-type-policy=OVERRIDE, i-signal-type=PRIMITIVE, init-value=0, base-type=BT_UH_Tag, compu {0=Cx0_Init (CM_UH_Tag_Cx0_Init), phys=raw for raw 1..31; unit Unit_Day}, range phys 1..31 Unit_Day, raw 0..31, unit=Unit_Day, transfer-property=PENDING, to Klima(timeout 5 s)  # 0x0: reserviert bei VW
          signal UH_Stunde_XIX_Diagnose_01_XIX_E3V_EVCANFD: start 44, 5 bit, little-endian, data-type-policy=OVERRIDE, i-signal-type=PRIMITIVE, init-value=0, base-type=BT_UH_Stunde, compu {phys=raw for raw 0..23; unit Unit_Hours}, range phys 0..23 Unit_Hours, raw 0..23, unit=Unit_Hours, transfer-property=PENDING, to Klima(timeout 5 s)  # 0x18 - 0x1F = Werte ungültig
          signal UH_Minute_XIX_Diagnose_01_XIX_E3V_EVCANFD: start 49, 6 bit, little-endian, data-type-policy=OVERRIDE, i-signal-type=PRIMITIVE, init-value=0, base-type=BT_UH_Minute, compu {phys=raw for raw 0..59; unit Unit_Minut}, range phys 0..59 Unit_Minut, raw 0..59, unit=Unit_Minut, transfer-property=PENDING, to Klima(timeout 5 s)  # 0x3C- 0x3f = Werte ungültig
          signal UH_Sekunde_XIX_Diagnose_01_XIX_E3V_EVCANFD: start 55, 6 bit, little-endian, data-type-policy=OVERRIDE, i-signal-type=PRIMITIVE, init-value=0, base-type=BT_UH_Sekunde, compu {phys=raw for raw 0..59; unit Unit_Secon}, range phys 0..59 Unit_Secon, raw 0..59, unit=Unit_Secon, transfer-property=PENDING, to Klima(timeout 5 s)  # 0x3C- 0x3f = Werte ungültig
          signal Vehicle_Driving_Cycle_XIX_Diagnose_01_XIX_E3V_EVCANFD: start 61, 1 bit, little-endian, data-type-policy=OVERRIDE, i-signal-type=PRIMITIVE, init-value=0, base-type=BT_Vehicle_Driving_Cycle, compu {0=Cx0_kein_Driving_Cycle_erkannt (CM_Vehicle_Driving_Cycle_Cx0_kein_Driving_Cycle_erkannt), 1=Cx1_Driving_Cycle_erkannt (CM_Vehicle_Driving_Cycle_Cx1_Driving_Cycle_erkannt)}, range raw 0..1, transfer-property=PENDING, to Klima(timeout 5 s)  # Optimierung der Inbetriebnahme von Steuergeräten in einem Teilverbau in der Produktion. Siehe VW80114. Signal bildet (durch eine Gateway-Funktion) den Inhalt des Signals OBD_Driving_Cycle ab.
          signal Kombi_02_alt_XIX_Diagnose_01_XIX_E3V_EVCANFD: start 62, 1 bit, little-endian, data-type-policy=OVERRIDE, i-signal-type=PRIMITIVE, init-value=1, base-type=BT_Kombi_02_alt, compu {0=Cx0_aktuell (CM_Kombi_02_alt_Cx0_aktuell), 1=Cx1_veraltet (CM_Kombi_02_alt_Cx1_veraltet)}, range raw 0..1, transfer-property=PENDING
          signal Uhrzeit_01_alt_XIX_Diagnose_01_XIX_E3V_EVCANFD: start 63, 1 bit, little-endian, data-type-policy=OVERRIDE, i-signal-type=PRIMITIVE, init-value=1, base-type=BT_Uhrzeit_01_alt, compu {0=Cx0_aktuell (CM_Uhrzeit_01_alt_Cx0_aktuell), 1=Cx1_veraltet (CM_Uhrzeit_01_alt_Cx1_veraltet)}, range raw 0..1, transfer-property=PENDING
      frame DiETa_01_XIX_E3V_EVCANFD: id 0x353, to Klima, frame-length=8, can-addressing-mode=STANDARD, can-frame-rx-behavior=CAN-FD, can-frame-tx-behavior=CAN-FD
        pdu DiETa_01_XIX_E3V_EVCANFD: length=8, transmission-mode-true-timing=cyclic-timing={time-offset=0.0, time-period=0.04}, unused-bit-pattern=0
          signal DiETas_01_CRC_XIX_DiETa_01_XIX_E3V_EVCANFD: start 0, 8 bit, little-endian, data-type-policy=OVERRIDE, i-signal-type=PRIMITIVE, base-type=BT_DiETas_01_CRC, compu {phys=raw for raw 0..255}, range phys 0..255, raw 0..255, transfer-property=PENDING  # Für MLB: Berechnung siehe Lastenheft "Kommunikationsabsicherung für FlexRay und CAN" Ab MQB und MLBevo: Berechnung siehe Lastenheft "End-to-End Kommunikationsabsicherung" Endwerte siehe Begleitdokument "S-PDU Kennungsfolgen"
          signal DiETas_01_BZ_XIX_DiETa_01_XIX_E3V_EVCANFD: start 8, 4 bit, little-endian, data-type-policy=OVERRIDE, i-signal-type=PRIMITIVE, base-type=BT_DiETas_01_BZ, compu {phys=raw for raw 0..15}, range phys 0..15, raw 0..15, transfer-property=PENDING  # 4bit Botschaftszähler, wird mit jeder Sendebotschaft inkrementiert
          signal DiETa_Reserve_Byte2_4_XIX_DiETa_01_XIX_E3V_EVCANFD: start 12, 1 bit, little-endian, data-type-policy=OVERRIDE, i-signal-type=PRIMITIVE, init-value=0, base-type=BT_DiETa_Reserve_Byte2_4, transfer-property=PENDING  # Vorhalt, Initialisierung mit '0'
          signal DiETa_Status_XIX_DiETa_01_XIX_E3V_EVCANFD: start 13, 2 bit, little-endian, data-type-policy=OVERRIDE, i-signal-type=PRIMITIVE, init-value=2, base-type=BT_DiETa_Status, compu {0=Cx0_DiETa_betriebsbereit (CM_DiETa_Status_Cx0_DiETa_betriebsbereit), 2=Cx2_Init (CM_DiETa_Status_Cx2_Init), 3=Cx3_Fehler_oder_defekt (CM_DiETa_Status_Cx3_Fehler_oder_defekt)}, range raw 0..3, transfer-property=PENDING  # Betriebszustand Direkteinstiegstasten
          signal DiETa_ResponseError_XIX_DiETa_01_XIX_E3V_EVCANFD: start 15, 1 bit, little-endian, data-type-policy=OVERRIDE, i-signal-type=PRIMITIVE, init-value=0, base-type=BT_DiETa_ResponseError, invalid-value=Invalid_DiETa_ResponseError_XIX_DiETa_01_XIX_E3V_EVCANFD:1, compu {0=Cx0_normal (CM_DiETa_ResponseError_Cx0_normal), 1=Cx1_Fehler (CM_DiETa_ResponseError_Cx1_Fehler)}, range raw 0..1, transfer-property=PENDING  # siehe LIN2.0-Specification (Darf nicht über ein Fehlergueltigkeitsbit abgesichtert werden!)
          signal DiETa_Car_XIX_DiETa_01_XIX_E3V_EVCANFD: start 16, 2 bit, little-endian, data-type-policy=OVERRIDE, i-signal-type=PRIMITIVE, init-value=0, base-type=BT_DiETa_Car, invalid-value=Invalid_DiETa_Car_XIX_DiETa_01_XIX_E3V_EVCANFD:3, compu {0=Cx0_Init_oder_nicht_verbaut (CM_DiETa_Car_Cx0_Init_oder_nicht_verbaut), 1=Cx1_Taste_unbetaetigt (CM_DiETa_Car_Cx1_Taste_unbetaetigt), 2=Cx2_Taste_betaetigt (CM_DiETa_Car_Cx2_Taste_betaetigt), 3=Cx3_Fehler (CM_DiETa_Car_Cx3_Fehler)}, range raw 0..3, transfer-property=PENDING  # Status Car-Taste
          signal DiETa_Klima_XIX_DiETa_01_XIX_E3V_EVCANFD: start 18, 2 bit, little-endian, data-type-policy=OVERRIDE, i-signal-type=PRIMITIVE, init-value=0, base-type=BT_DiETa_Klima, invalid-value=Invalid_DiETa_Klima_XIX_DiETa_01_XIX_E3V_EVCANFD:3, compu {0=Cx0_Init_oder_nicht_verbaut (CM_DiETa_Klima_Cx0_Init_oder_nicht_verbaut), 1=Cx1_Taste_unbetaetigt (CM_DiETa_Klima_Cx1_Taste_unbetaetigt), 2=Cx2_Taste_betaetigt (CM_DiETa_Klima_Cx2_Taste_betaetigt), 3=Cx3_Fehler (CM_DiETa_Klima_Cx3_Fehler)}, range raw 0..3, transfer-property=PENDING, to Klima(timeout 0.5 s)  # Status Klimataste
          signal DiETa_Mode_XIX_DiETa_01_XIX_E3V_EVCANFD: start 20, 2 bit, little-endian, data-type-policy=OVERRIDE, i-signal-type=PRIMITIVE, init-value=0, base-type=BT_DiETa_Mode, invalid-value=Invalid_DiETa_Mode_XIX_DiETa_01_XIX_E3V_EVCANFD:3, compu {0=Cx0_Init_oder_nicht_verbaut (CM_DiETa_Mode_Cx0_Init_oder_nicht_verbaut), 1=Cx1_Taste_unbetaetigt (CM_DiETa_Mode_Cx1_Taste_unbetaetigt), 2=Cx2_Taste_betaetigt (CM_DiETa_Mode_Cx2_Taste_betaetigt), 3=Cx3_Fehler (CM_DiETa_Mode_Cx3_Fehler)}, range raw 0..3, transfer-property=PENDING  # Status Modetaste
          signal DiETa_Parken_XIX_DiETa_01_XIX_E3V_EVCANFD: start 22, 2 bit, little-endian, data-type-policy=OVERRIDE, i-signal-type=PRIMITIVE, init-value=0, base-type=BT_DiETa_Parken, invalid-value=Invalid_DiETa_Parken_XIX_DiETa_01_XIX_E3V_EVCANFD:3, compu {0=Cx0_Init_oder_nicht_verbaut (CM_DiETa_Parken_Cx0_Init_oder_nicht_verbaut), 1=Cx1_Taste_unbetaetigt (CM_DiETa_Parken_Cx1_Taste_unbetaetigt), 2=Cx2_Taste_betaetigt (CM_DiETa_Parken_Cx2_Taste_betaetigt), 3=Cx3_Fehler (CM_DiETa_Parken_Cx3_Fehler)}, range raw 0..3, transfer-property=PENDING  # Status Parkentaste
          signal DiETa_FSH_Taste_XIX_DiETa_01_XIX_E3V_EVCANFD: start 24, 2 bit, little-endian, data-type-policy=OVERRIDE, i-signal-type=PRIMITIVE, init-value=0, base-type=BT_DiETa_FSH_Taste, invalid-value=Invalid_DiETa_FSH_Taste_XIX_DiETa_01_XIX_E3V_EVCANFD:3, compu {0=Cx0_Init_oder_nicht_verbaut (CM_DiETa_FSH_Taste_Cx0_Init_oder_nicht_verbaut), 1=Cx1_Taste_unbetaetigt (CM_DiETa_FSH_Taste_Cx1_Taste_unbetaetigt), 2=Cx2_Taste_betaetigt (CM_DiETa_FSH_Taste_Cx2_Taste_betaetigt), 3=Cx3_Fehler (CM_DiETa_FSH_Taste_Cx3_Fehler)}, range raw 0..3, transfer-property=PENDING, to Klima(timeout 0.5 s)  # Frontscheibenheizung AN/AUS
          signal DiETa_HSH_Taste_XIX_DiETa_01_XIX_E3V_EVCANFD: start 26, 2 bit, little-endian, data-type-policy=OVERRIDE, i-signal-type=PRIMITIVE, init-value=0, base-type=BT_DiETa_HSH_Taste, invalid-value=Invalid_DiETa_HSH_Taste_XIX_DiETa_01_XIX_E3V_EVCANFD:3, compu {0=Cx0_Init_oder_nicht_verbaut (CM_DiETa_HSH_Taste_Cx0_Init_oder_nicht_verbaut), 1=Cx1_Taste_unbetaetigt (CM_DiETa_HSH_Taste_Cx1_Taste_unbetaetigt), 2=Cx2_Taste_betaetigt (CM_DiETa_HSH_Taste_Cx2_Taste_betaetigt), 3=Cx3_Fehler (CM_DiETa_HSH_Taste_Cx3_Fehler)}, range raw 0..3, transfer-property=PENDING, to Klima(timeout 0.5 s)  # Heckscheibenheizung AN/AUS
          signal DiETa_Warnblink_Taste_XIX_DiETa_01_XIX_E3V_EVCANFD: start 28, 2 bit, little-endian, data-type-policy=OVERRIDE, i-signal-type=PRIMITIVE, init-value=0, base-type=BT_DiETa_Warnblink_Taste, invalid-value=Invalid_DiETa_Warnblink_Taste_XIX_DiETa_01_XIX_E3V_EVCANFD:3, compu {0=Cx0_Init_oder_nicht_verbaut (CM_DiETa_Warnblink_Taste_Cx0_Init_oder_nicht_verbaut), 1=Cx1_Taste_unbetaetigt (CM_DiETa_Warnblink_Taste_Cx1_Taste_unbetaetigt), 2=Cx2_Taste_betaetigt (CM_DiETa_Warnblink_Taste_Cx2_Taste_betaetigt), 3=Cx3_Fehler (CM_DiETa_Warnblink_Taste_Cx3_Fehler)}, range raw 0..3, transfer-property=PENDING  # Status Warnblinktaster
          signal DiETa_FAS_Stufe_XIX_DiETa_01_XIX_E3V_EVCANFD: start 30, 2 bit, little-endian, data-type-policy=OVERRIDE, i-signal-type=PRIMITIVE, init-value=0, base-type=BT_DiETa_FAS_Stufe, invalid-value=Invalid_DiETa_FAS_Stufe_XIX_DiETa_01_XIX_E3V_EVCANFD:3, compu {0=Cx0_Init_oder_nicht_verbaut (CM_DiETa_FAS_Stufe_Cx0_Init_oder_nicht_verbaut), 1=Cx1_Taste_unbetaetigt (CM_DiETa_FAS_Stufe_Cx1_Taste_unbetaetigt), 2=Cx2_Taste_betaetigt (CM_DiETa_FAS_Stufe_Cx2_Taste_betaetigt), 3=Cx3_Fehler (CM_DiETa_FAS_Stufe_Cx3_Fehler)}, range raw 0..3, transfer-property=PENDING  # Status FAS-Taste
          signal DiETa_PAO_ON_Status_XIX_DiETa_01_XIX_E3V_EVCANFD: start 32, 2 bit, little-endian, data-type-policy=OVERRIDE, i-signal-type=PRIMITIVE, init-value=0, base-type=BT_DiETa_PAO_ON_Status, compu {0=Cx0_LED_Aus (CM_DiETa_PAO_ON_Status_Cx0_LED_Aus), 1=Cx1_LED_Ein (CM_DiETa_PAO_ON_Status_Cx1_LED_Ein), 2=Cx2_LED_Blinkt (CM_DiETa_PAO_ON_Status_Cx2_LED_Blinkt), 3=Cx3_LED_defekt (CM_DiETa_PAO_ON_Status_Cx3_LED_defekt)}, range raw 0..3, transfer-property=PENDING  # Istwert für LED "ON" in Anzeige Passenger Airbag On/Off
          signal DiETa_PAO_OFF_Status_XIX_DiETa_01_XIX_E3V_EVCANFD: start 34, 2 bit, little-endian, data-type-policy=OVERRIDE, i-signal-type=PRIMITIVE, init-value=0, base-type=BT_DiETa_PAO_OFF_Status, compu {0=Cx0_LED_Aus (CM_DiETa_PAO_OFF_Status_Cx0_LED_Aus), 1=Cx1_LED_Ein (CM_DiETa_PAO_OFF_Status_Cx1_LED_Ein), 2=Cx2_LED_Blinkt (CM_DiETa_PAO_OFF_Status_Cx2_LED_Blinkt), 3=Cx3_LED_defekt (CM_DiETa_PAO_OFF_Status_Cx3_LED_defekt)}, range raw 0..3, transfer-property=PENDING  # Istwert für LED "OFF" in Anzeige Passenger Airbag On/Off
          signal DiETa_Defrost_Taste_XIX_DiETa_01_XIX_E3V_EVCANFD: start 36, 2 bit, little-endian, data-type-policy=OVERRIDE, i-signal-type=PRIMITIVE, init-value=0, base-type=BT_DiETa_Defrost_Taste, invalid-value=Invalid_DiETa_Defrost_Taste_XIX_DiETa_01_XIX_E3V_EVCANFD:3, compu {0=Cx0_Init_oder_nicht_verbaut (CM_DiETa_Defrost_Taste_Cx0_Init_oder_nicht_verbaut), 1=Cx1_Taste_unbetaetigt (CM_DiETa_Defrost_Taste_Cx1_Taste_unbetaetigt), 2=Cx2_Taste_betaetigt (CM_DiETa_Defrost_Taste_Cx2_Taste_betaetigt), 3=Cx3_Fehler (CM_DiETa_Defrost_Taste_Cx3_Fehler)}, range raw 0..3, transfer-property=PENDING, to Klima(timeout 0.5 s)  # Max. Defrost AN/AUS
          signal DiETa_Mode2_XIX_DiETa_01_XIX_E3V_EVCANFD: start 38, 2 bit, little-endian, data-type-policy=OVERRIDE, i-signal-type=PRIMITIVE, init-value=0, base-type=BT_DiETa_Mode2, invalid-value=Invalid_DiETa_Mode2_XIX_DiETa_01_XIX_E3V_EVCANFD:3, compu {0=Cx0_Init_oder_nicht_verbaut (CM_DiETa_Mode2_Cx0_Init_oder_nicht_verbaut), 1=Cx1_Taste_unbetaetigt (CM_DiETa_Mode2_Cx1_Taste_unbetaetigt), 2=Cx2_Taste_betaetigt (CM_DiETa_Mode2_Cx2_Taste_betaetigt), 3=Cx3_Fehler (CM_DiETa_Mode2_Cx3_Fehler)}, range raw 0..3, transfer-property=PENDING  # Status Mode2taste (GTE-Taster im VW380 PHEV)
          signal DiETa_Lock_Unlock_Taste_XIX_DiETa_01_XIX_E3V_EVCANFD: start 40, 3 bit, little-endian, data-type-policy=OVERRIDE, i-signal-type=PRIMITIVE, init-value=0, base-type=BT_DiETa_Lock_Unlock_Taste, invalid-value=Invalid_DiETa_Lock_Unlock_Taste_XIX_DiETa_01_XIX_E3V_EVCANFD:7, compu {0=Cx0_Init (CM_DiETa_Lock_Unlock_Taste_Cx0_Init), 1=Cx1_Taste_unbetaetigt (CM_DiETa_Lock_Unlock_Taste_Cx1_Taste_unbetaetigt), 2=Cx2_Taste_betaetigt_unlock (CM_DiETa_Lock_Unlock_Taste_Cx2_Taste_betaetigt_unlock), 3=Cx3_Taste_betaetigt_lock (CM_DiETa_Lock_Unlock_Taste_Cx3_Taste_betaetigt_lock), 4=Cx4_Reserviert (CM_DiETa_Lock_Unlock_Taste_Cx4_Reserviert), 5=Cx5_Reserviert (CM_DiETa_Lock_Unlock_Taste_Cx5_Reserviert), 6=Cx6_Reserviert (CM_DiETa_Lock_Unlock_Taste_Cx6_Reserviert), 7=Cx7_Fehler (CM_DiETa_Lock_Unlock_Taste_Cx7_Fehler)}, range raw 0..7, transfer-property=PENDING  # Lock-/Unlock-Taste
          signal DiETa_Mode_roh_XIX_DiETa_01_XIX_E3V_EVCANFD: start 43, 1 bit, little-endian, data-type-policy=OVERRIDE, i-signal-type=PRIMITIVE, init-value=0, base-type=BT_DiETa_Mode_roh, compu {0=Cx0_Taste_unbetaetigt (CM_DiETa_Mode_roh_Cx0_Taste_unbetaetigt), 1=Cx1_Taste_betaetigt (CM_DiETa_Mode_roh_Cx1_Taste_betaetigt)}, range raw 0..1, transfer-property=PENDING  # Erweitertes SIgnal zur Erfüllung der OBD-Relevanz für die Funktion Mode auf der DiETa
          signal ESP_Off_Taster_XIX_DiETa_01_XIX_E3V_EVCANFD: start 44, 2 bit, little-endian, data-type-policy=OVERRIDE, i-signal-type=PRIMITIVE, init-value=2, base-type=BT_ESP_Off_Taster, invalid-value=Invalid_ESP_Off_Taster_XIX_DiETa_01_XIX_E3V_EVCANFD:3, compu {0=Cx0_Taste_nicht_betaetigt (CM_ESP_Off_Taster_Cx0_Taste_nicht_betaetigt), 1=Cx1_Taste_entprellt_betaetigt (CM_ESP_Off_Taster_Cx1_Taste_entprellt_betaetigt), 2=Cx2_Init_oder_nicht_verbaut (CM_ESP_Off_Taster_Cx2_Init_oder_nicht_verbaut), 3=Cx3_Fehler (CM_ESP_Off_Taster_Cx3_Fehler)}, range raw 0..3, transfer-property=PENDING  # Das Signal beschreibt den Zustand der ESP Taste, die im MLBevo vom BCM1 eingelesen wird.
          signal DiETa_Reserve_Byte6_6_XIX_DiETa_01_XIX_E3V_EVCANFD: start 46, 2 bit, little-endian, data-type-policy=OVERRIDE, i-signal-type=PRIMITIVE, init-value=0, base-type=BT_DiETa_Reserve_Byte6_6, transfer-property=PENDING  # Vorhalt, Initialisierung mit '0'
          signal DiETa_Touch_Event_XIX_DiETa_01_XIX_E3V_EVCANFD: start 48, 4 bit, little-endian, data-type-policy=OVERRIDE, i-signal-type=PRIMITIVE, init-value=0, base-type=BT_DiETa_Touch_Event, invalid-value=Invalid_DiETa_Touch_Event_XIX_DiETa_01_XIX_E3V_EVCANFD:15, compu {0=Cx0_nicht_betaetigt (CM_DiETa_Touch_Event_Cx0_nicht_betaetigt), 1=Cx1_Tippen (CM_DiETa_Touch_Event_Cx1_Tippen), 2=Cx2_Wischen_Slide (CM_DiETa_Touch_Event_Cx2_Wischen_Slide), 3=Cx3_Geste (CM_DiETa_Touch_Event_Cx3_Geste), 4=Cx4_Doppeltippen (CM_DiETa_Touch_Event_Cx4_Doppeltippen), 5=Cx5_Longpress_1 (CM_DiETa_Touch_Event_Cx5_Longpress_1), 6=Cx6_Longpress_2 (CM_DiETa_Touch_Event_Cx6_Longpress_2), 7=Cx7_Longpress_3 (CM_DiETa_Touch_Event_Cx7_Longpress_3), 8=Cx8_Press (CM_DiETa_Touch_Event_Cx8_Press), 9=Cx9_Strongpress (CM_DiETa_Touch_Event_Cx9_Strongpress), 10=Cxa_reserviert (CM_DiETa_Touch_Event_Cxa_reserviert), 11=Cxb_reserviert (CM_DiETa_Touch_Event_Cxb_reserviert), 12=Cxc_reserviert (CM_DiETa_Touch_Event_Cxc_reserviert), 13=Cxd_reserviert (CM_DiETa_Touch_Event_Cxd_reserviert), 14=Cxe_Taktgeber_Inkrement (CM_DiETa_Touch_Event_Cxe_Taktgeber_Inkrement), 15=Cxf_Fehler (CM_DiETa_Touch_Event_Cxf_Fehler)}, range raw 0..15, transfer-property=PENDING  # Touch_Events für Informationen einer Funktionsauslösung auf DiETa, welches dann für bspw. ein akustisches Signal zentral umgesetzt werden können.
          signal DiETa_Reserve_Byte7_4_XIX_DiETa_01_XIX_E3V_EVCANFD: start 52, 4 bit, little-endian, data-type-policy=OVERRIDE, i-signal-type=PRIMITIVE, init-value=0, base-type=BT_DiETa_Reserve_Byte7_4, transfer-property=PENDING  # Vorhalt, Initialisierung mit '0'
          signal DiETa_Reserve_Byte8_XIX_DiETa_01_XIX_E3V_EVCANFD: start 56, 8 bit, little-endian, data-type-policy=OVERRIDE, i-signal-type=PRIMITIVE, init-value=0, base-type=BT_DiETa_Reserve_Byte8, transfer-property=PENDING  # Vorhalt, Initialisierung mit '0'
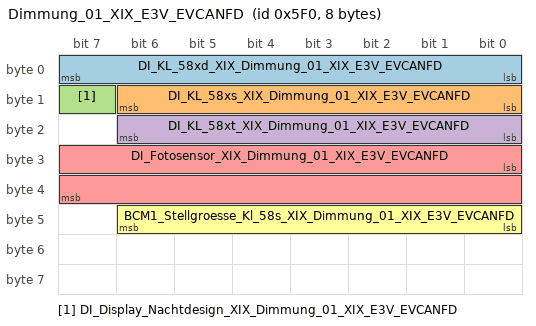
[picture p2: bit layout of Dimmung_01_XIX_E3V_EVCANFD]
      frame Dimmung_01_XIX_E3V_EVCANFD: id 0x5F0, to Klima, frame-length=8, can-addressing-mode=STANDARD, can-frame-rx-behavior=CAN-FD, can-frame-tx-behavior=CAN-FD
        pdu Dimmung_01_XIX_E3V_EVCANFD: length=8, minimum-delay=0.05, transmission-mode-true-timing={cyclic-timing={time-offset=0.0, time-period=0.2}, event-controlled-timing={number-of-repetitions=0, repetition-period=0.0}}, unused-bit-pattern=0  # ab MQB nach abgestimmten FLH Dimmung
          signal DI_KL_58xd_XIX_Dimmung_01_XIX_E3V_EVCANFD: start 0, 8 bit, little-endian, data-type-policy=OVERRIDE, i-signal-type=PRIMITIVE, init-value=254, base-type=BT_DI_KL_58xd, invalid-value=Invalid_DI_KL_58xd_XIX_Dimmung_01_XIX_E3V_EVCANFD:255, compu {phys=raw for raw 0..253, 254=Cxfe_Init (CM_DI_KL_58xd_Cxfe_Init), 255=Cxff_Fehler (CM_DI_KL_58xd_Cxff_Fehler)}, range phys 0..253, raw 0..255, transfer-property=TRIGGERED-ON-CHANGE-WITHOUT-REPETITION, to Klima(timeout 2 s)  # Klemme 58xd Display- und Funktionsbeleuchtung Mit der Klemme 58xd wird die Helligkeit der Display- und der Funktionsbeleuchtungen der Schalter gesteuert. Im Detail beschrieben im 'Funktionslastenheft Dimmung MQB'.
          signal DI_KL_58xs_XIX_Dimmung_01_XIX_E3V_EVCANFD: start 8, 7 bit, little-endian, data-type-policy=OVERRIDE, i-signal-type=PRIMITIVE, init-value=126, base-type=BT_DI_KL_58xs, invalid-value=Invalid_DI_KL_58xs_XIX_Dimmung_01_XIX_E3V_EVCANFD:127, compu {phys=raw for raw 0..100, 126=Cx7e_Init (CM_DI_KL_58xs_Cx7e_Init), 127=Cx7f_Fehler (CM_DI_KL_58xs_Cx7f_Fehler); unit Unit_PerCent}, range phys 0..100 Unit_PerCent, raw 0..127, unit=Unit_PerCent, transfer-property=TRIGGERED-ON-CHANGE-WITHOUT-REPETITION, to Klima(timeout 2 s)  # Suchbeleuchtung Schalter EIN-AUS-Schaltalgorithmus der allgemeinen Schaltersuchbeleuchtung. Im Detail beschrieben im 'Funktionslastenheft Dimmung MQB'.
          signal DI_Display_Nachtdesign_XIX_Dimmung_01_XIX_E3V_EVCANFD: start 15, 1 bit, little-endian, data-type-policy=OVERRIDE, i-signal-type=PRIMITIVE, init-value=0, base-type=BT_DI_Display_Nachtdesign, transfer-property=TRIGGERED-ON-CHANGE-WITHOUT-REPETITION  # Für Displays sind oft automatische Umschaltungen von Tag-/Nachtdesign vorgesehen. Es gibt jedoch Zustände, an denen auch tagsüber das Abblendlicht eingeschaltet ist. z.B. Dauerfahrlicht, Geschwindigkeitsabhängiges "Licht-An-Bei-Autobahn", "Regenlicht", etc. Die Aufgabe des Signals s_Display_Nachtdesign ist es, Fehlumschaltungen zu vermeiden. Es ist im Dimm-Master zu implementieren. Im Detail beschrieben im 'Funktionslastenheft Dimmung MQB'.
          signal DI_KL_58xt_XIX_Dimmung_01_XIX_E3V_EVCANFD: start 16, 7 bit, little-endian, data-type-policy=OVERRIDE, i-signal-type=PRIMITIVE, init-value=126, base-type=BT_DI_KL_58xt, invalid-value=Invalid_DI_KL_58xt_XIX_Dimmung_01_XIX_E3V_EVCANFD:127, compu {phys=raw for raw 0..100, 126=Cx7e_Init (CM_DI_KL_58xt_Cx7e_Init), 127=Cx7f_Fehler (CM_DI_KL_58xt_Cx7f_Fehler); unit Unit_PerCent}, range phys 0..100 Unit_PerCent, raw 0..127, unit=Unit_PerCent, transfer-property=TRIGGERED-ON-CHANGE-WITHOUT-REPETITION, to Klima  # Timergesteuerte Suchbeleuchtung Der EIN-AUS-Schaltalgorithmus für die vor- und nachlaufende Schaltersuchbeleuchtungen beim Ein- & Aussteigen; z.B.: Start/Stop-Taster. Im Detail beschrieben im 'Funktionslastenheft Dimmung MQB'.
          signal DI_Fotosensor_XIX_Dimmung_01_XIX_E3V_EVCANFD: start 24, 16 bit, little-endian, data-type-policy=OVERRIDE, i-signal-type=PRIMITIVE, init-value=0, base-type=BT_DI_Fotosensor, compu {phys=raw for raw 0..65535}, range phys 0..65535, raw 0..65535, transfer-property=TRIGGERED-ON-CHANGE-WITHOUT-REPETITION  # Helligkeitswert Fotosensor Für die Dimmung relevanter Wert zur Sensierung der Umgebungshelligkeit Im Detail beschrieben im 'Funktionslastenheft Dimmung MQB'.
          signal BCM1_Stellgroesse_Kl_58s_XIX_Dimmung_01_XIX_E3V_EVCANFD: start 40, 7 bit, little-endian, data-type-policy=OVERRIDE, i-signal-type=PRIMITIVE, init-value=126, base-type=BT_BCM1_Stellgroesse_Kl_58s, invalid-value=Invalid_BCM1_Stellgroesse_Kl_58s_XIX_Dimmung_01_XIX_E3V_EVCANFD:127, compu {phys=raw for raw 0..100, 125=Cx7d_Nicht_verbaut (CM_BCM1_Stellgroesse_Kl_58s_Cx7d_Nicht_verbaut), 126=Cx7e_Init (CM_BCM1_Stellgroesse_Kl_58s_Cx7e_Init), 127=Cx7f_Fehler (CM_BCM1_Stellgroesse_Kl_58s_Cx7f_Fehler)}, range phys 0..100, raw 0..127, transfer-property=TRIGGERED-ON-CHANGE-WITHOUT-REPETITION  # Rohwert Dimmpoti
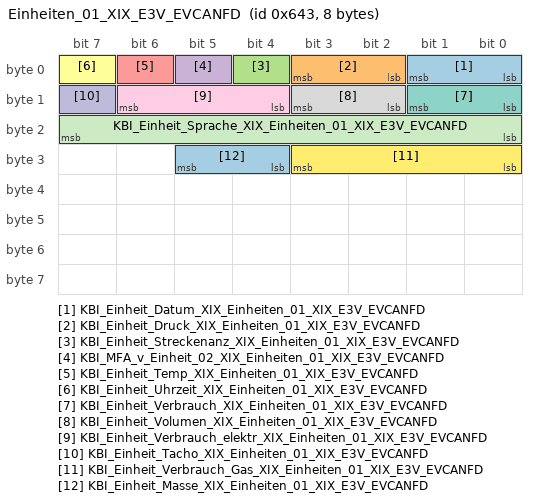
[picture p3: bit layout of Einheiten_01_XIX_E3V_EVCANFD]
      frame Einheiten_01_XIX_E3V_EVCANFD: id 0x643, to Klima, frame-length=8, can-addressing-mode=STANDARD, can-frame-rx-behavior=CAN-FD, can-frame-tx-behavior=CAN-FD
        pdu Einheiten_01_XIX_E3V_EVCANFD: length=8, minimum-delay=0.1, transmission-mode-true-timing={cyclic-timing={time-offset=0.0, time-period=1.0}, event-controlled-timing={number-of-repetitions=0, repetition-period=0.0}}, unused-bit-pattern=0  # ab MQB mit 8 Byte
          signal KBI_Einheit_Datum_XIX_Einheiten_01_XIX_E3V_EVCANFD: start 0, 2 bit, little-endian, data-type-policy=OVERRIDE, i-signal-type=PRIMITIVE, init-value=0, base-type=BT_KBI_Einheit_Datum, compu {0=Cx0_Tag_Monat_Jahr (CM_KBI_Einheit_Datum_Cx0_Tag_Monat_Jahr) (Tag/Monat/Jahr), 1=Cx1_Monat_Tag_Jahr (CM_KBI_Einheit_Datum_Cx1_Monat_Tag_Jahr) (Monat/Tag/Jahr), 2=Cx2_Jahr_Monat_Tag (CM_KBI_Einheit_Datum_Cx2_Jahr_Monat_Tag) (Jahr/Monat/Tag), 3=Cx3_reserviert (CM_KBI_Einheit_Datum_Cx3_reserviert)}, range raw 0..3, transfer-property=TRIGGERED-ON-CHANGE-WITHOUT-REPETITION  # Anzeigevariante des Datums
          signal KBI_Einheit_Druck_XIX_Einheiten_01_XIX_E3V_EVCANFD: start 2, 2 bit, little-endian, data-type-policy=OVERRIDE, i-signal-type=PRIMITIVE, init-value=0, base-type=BT_KBI_Einheit_Druck, compu {0=Cx0_Druckangabe_in_bar (CM_KBI_Einheit_Druck_Cx0_Druckangabe_in_bar) (Druckangabe in bar), 1=Cx1_Druckangabe_in_psi (CM_KBI_Einheit_Druck_Cx1_Druckangabe_in_psi) (Druckangabe in psi), 2=Cx2_Druckangabe_in_kPa (CM_KBI_Einheit_Druck_Cx2_Druckangabe_in_kPa) (Druckangabe in kPa), 3=Cx3_tbd (CM_KBI_Einheit_Druck_Cx3_tbd) (tbd.)}, range raw 0..3, transfer-property=TRIGGERED-ON-CHANGE-WITHOUT-REPETITION  # Einheit des Druckes
          signal KBI_Einheit_Streckenanz_XIX_Einheiten_01_XIX_E3V_EVCANFD: start 4, 1 bit, little-endian, data-type-policy=OVERRIDE, i-signal-type=PRIMITIVE, init-value=0, base-type=BT_KBI_Einheit_Streckenanz, compu {0=Cx0_Kilometer (CM_KBI_Einheit_Streckenanz_Cx0_Kilometer), 1=Cx1_Meilen (CM_KBI_Einheit_Streckenanz_Cx1_Meilen)}, range raw 0..1, transfer-property=TRIGGERED-ON-CHANGE-WITHOUT-REPETITION  # Einheit der Streckenanzeige
          signal KBI_MFA_v_Einheit_02_XIX_Einheiten_01_XIX_E3V_EVCANFD: start 5, 1 bit, little-endian, data-type-policy=OVERRIDE, i-signal-type=PRIMITIVE, init-value=0, base-type=BT_KBI_MFA_v_Einheit_02, compu {0=Cx0_kmh (CM_KBI_MFA_v_Einheit_02_Cx0_kmh), 1=Cx1_mph (CM_KBI_MFA_v_Einheit_02_Cx1_mph)}, range raw 0..1, transfer-property=TRIGGERED-ON-CHANGE-WITHOUT-REPETITION  # Einheit der Geschwindigkeit, die vom Fahrer im Car-Menü gewählt wurde. Veränderliche Grösse, im Gegensatz zur Einheit des Tachokranzes. Redundant in der Einheiten_01 Botschaft definiert, um Konsistenz zur BAP-Festlegung zu haben.
          signal KBI_Einheit_Temp_XIX_Einheiten_01_XIX_E3V_EVCANFD: start 6, 1 bit, little-endian, data-type-policy=OVERRIDE, i-signal-type=PRIMITIVE, init-value=0, base-type=BT_KBI_Einheit_Temp, compu {0=Cx0_Grad_Celsius_C (CM_KBI_Einheit_Temp_Cx0_Grad_Celsius_C) (Grad Celsius °C), 1=Cx1_Grad_Fahrenheit_F (CM_KBI_Einheit_Temp_Cx1_Grad_Fahrenheit_F) (Grad Fahrenheit °F)}, range raw 0..1, transfer-property=TRIGGERED-ON-CHANGE-WITHOUT-REPETITION, to Klima(timeout 5 s)  # Einheit der Temperatur
          signal KBI_Einheit_Uhrzeit_XIX_Einheiten_01_XIX_E3V_EVCANFD: start 7, 1 bit, little-endian, data-type-policy=OVERRIDE, i-signal-type=PRIMITIVE, init-value=0, base-type=BT_KBI_Einheit_Uhrzeit, compu {0=Cx0_24h (CM_KBI_Einheit_Uhrzeit_Cx0_24h), 1=Cx1_12h_AM_PM (CM_KBI_Einheit_Uhrzeit_Cx1_12h_AM_PM) (12h AM/PM)}, range raw 0..1, transfer-property=TRIGGERED-ON-CHANGE-WITHOUT-REPETITION, to Klima  # Anzeigevariante der Uhrzeit
          signal KBI_Einheit_Verbrauch_XIX_Einheiten_01_XIX_E3V_EVCANFD: start 8, 2 bit, little-endian, data-type-policy=OVERRIDE, i-signal-type=PRIMITIVE, init-value=0, base-type=BT_KBI_Einheit_Verbrauch, compu {0=Cx0_mpg_UK (CM_KBI_Einheit_Verbrauch_Cx0_mpg_UK) (mpg UK), 1=Cx1_mpg_USA (CM_KBI_Einheit_Verbrauch_Cx1_mpg_USA) (mpg USA), 2=Cx2_Liter_100km (CM_KBI_Einheit_Verbrauch_Cx2_Liter_100km) (Liter/100km), 3=Cx3_km_Liter (CM_KBI_Einheit_Verbrauch_Cx3_km_Liter) (km/Liter)}, range raw 0..3, transfer-property=TRIGGERED-ON-CHANGE-WITHOUT-REPETITION  # Einheit der Verbrauchs
          signal KBI_Einheit_Volumen_XIX_Einheiten_01_XIX_E3V_EVCANFD: start 10, 2 bit, little-endian, data-type-policy=OVERRIDE, i-signal-type=PRIMITIVE, init-value=0, base-type=BT_KBI_Einheit_Volumen, compu {0=Cx0_Liter (CM_KBI_Einheit_Volumen_Cx0_Liter), 1=Cx1_Gallonen_UK (CM_KBI_Einheit_Volumen_Cx1_Gallonen_UK) (Gallonen UK), 2=Cx2_Gallonen_USA (CM_KBI_Einheit_Volumen_Cx2_Gallonen_USA) (Gallonen USA), 3=Cx3_reserviert (CM_KBI_Einheit_Volumen_Cx3_reserviert)}, range raw 0..3, transfer-property=TRIGGERED-ON-CHANGE-WITHOUT-REPETITION  # Einheit des Volumens
          signal KBI_Einheit_Verbrauch_elektr_XIX_Einheiten_01_XIX_E3V_EVCANFD: start 12, 3 bit, little-endian, data-type-policy=OVERRIDE, i-signal-type=PRIMITIVE, init-value=0, base-type=BT_KBI_Einheit_Verbrauch_elektr, compu {0=Cx0_kWh_pro_100km (CM_KBI_Einheit_Verbrauch_elektr_Cx0_kWh_pro_100km), 1=Cx1_km_pro_kWh (CM_KBI_Einheit_Verbrauch_elektr_Cx1_km_pro_kWh), 2=Cx2_kWh_pro_100mls (CM_KBI_Einheit_Verbrauch_elektr_Cx2_kWh_pro_100mls), 3=Cx3_mls_pro_kWh (CM_KBI_Einheit_Verbrauch_elektr_Cx3_mls_pro_kWh), 4=Cx4_MPGe (CM_KBI_Einheit_Verbrauch_elektr_Cx4_MPGe)}, range raw 0..4, transfer-property=TRIGGERED-ON-CHANGE-WITHOUT-REPETITION  # Einheit elektrischer Verbrauch
          signal KBI_Einheit_Tacho_XIX_Einheiten_01_XIX_E3V_EVCANFD: start 15, 1 bit, little-endian, data-type-policy=OVERRIDE, i-signal-type=PRIMITIVE, init-value=0, base-type=BT_KBI_Einheit_Tacho, compu {0=Cx0_km_h (CM_KBI_Einheit_Tacho_Cx0_km_h) (km/h), 1=Cx1_mph (CM_KBI_Einheit_Tacho_Cx1_mph)}, range raw 0..1, transfer-property=TRIGGERED-ON-CHANGE-WITHOUT-REPETITION  # Information, ob es sich um Meilen- oder Kmh-Kombi handelt, Einheit des Tachos entspricht dem Zifferblatt, Grösse ist nicht veränderlich
          signal KBI_Einheit_Sprache_XIX_Einheiten_01_XIX_E3V_EVCANFD: start 16, 8 bit, little-endian, data-type-policy=OVERRIDE, i-signal-type=PRIMITIVE, init-value=0, base-type=BT_KBI_Einheit_Sprache, compu {phys=raw for raw 0..255}, range phys 0..255, raw 0..255, transfer-property=TRIGGERED-ON-CHANGE-WITHOUT-REPETITION  # Siehe BAP-Datenfestlegung UnitMaster
          signal KBI_Einheit_Verbrauch_Gas_XIX_Einheiten_01_XIX_E3V_EVCANFD: start 24, 4 bit, little-endian, data-type-policy=OVERRIDE, i-signal-type=PRIMITIVE, init-value=0, base-type=BT_KBI_Einheit_Verbrauch_Gas, compu {0=Cx0_kg_per_100km (CM_KBI_Einheit_Verbrauch_Gas_Cx0_kg_per_100km), 1=Cx1_km_per_kg (CM_KBI_Einheit_Verbrauch_Gas_Cx1_km_per_kg), 2=Cx2_m3_per_100km (CM_KBI_Einheit_Verbrauch_Gas_Cx2_m3_per_100km), 3=Cx3_km_per_m3 (CM_KBI_Einheit_Verbrauch_Gas_Cx3_km_per_m3), 4=Cx4_miles_per_lbs (CM_KBI_Einheit_Verbrauch_Gas_Cx4_miles_per_lbs), 5=Cx5_miles_per_yard3 (CM_KBI_Einheit_Verbrauch_Gas_Cx5_miles_per_yard3), 6=Cx6_miles_per_kg (CM_KBI_Einheit_Verbrauch_Gas_Cx6_miles_per_kg), 7=Cx7_miles_per_m3 (CM_KBI_Einheit_Verbrauch_Gas_Cx7_miles_per_m3), 8=Cx8_miles_per_gallon_equivalent_US (CM_KBI_Einheit_Verbrauch_Gas_Cx8_miles_per_gallon_equivalent_US)}, range raw 0..8, transfer-property=TRIGGERED-ON-CHANGE-WITHOUT-REPETITION  # Unterscheidung zwischen M3/h und kg/h für Komfortverbrauchsberechnung.
          signal KBI_Einheit_Masse_XIX_Einheiten_01_XIX_E3V_EVCANFD: start 28, 2 bit, little-endian, data-type-policy=OVERRIDE, i-signal-type=PRIMITIVE, init-value=0, base-type=BT_KBI_Einheit_Masse, compu {0=Cx0_kg (CM_KBI_Einheit_Masse_Cx0_kg), 1=Cx1_lbs (CM_KBI_Einheit_Masse_Cx1_lbs), 2=Cx2_reserviert (CM_KBI_Einheit_Masse_Cx2_reserviert)}, range raw 0..2, transfer-property=TRIGGERED-ON-CHANGE-WITHOUT-REPETITION  # Einheit der Masse (Verwendung z.B. ASTA)
      frame EM1_01_XIX_E3V_EVCANFD: id 0xC0, to Klima, frame-length=32, can-addressing-mode=STANDARD, can-frame-rx-behavior=CAN-FD, can-frame-tx-behavior=CAN-FD
        pdu EM1_01_XIX_E3V_EVCANFD: length=32, transmission-mode-true-timing=cyclic-timing={time-offset=0.0, time-period=0.05}, unused-bit-pattern=0
          signal EM1_01_CRC_XIX_EM1_01_XIX_E3V_EVCANFD: start 0, 8 bit, little-endian, data-type-policy=OVERRIDE, i-signal-type=PRIMITIVE, base-type=BT_EM1_01_CRC, compu {phys=raw for raw 0..255}, range phys 0..255, raw 0..255, transfer-property=PENDING  # Für MLB: Berechnung siehe Lastenheft "Kommunikationsabsicherung für FlexRay und CAN" Ab MQB und MLBevo: Berechnung siehe Lastenheft "End-to-End Kommunikationsabsicherung" Endwerte siehe Begleitdokument "S-PDU Kennungsfolgen"
          signal EM1_01_BZ_XIX_EM1_01_XIX_E3V_EVCANFD: start 8, 4 bit, little-endian, data-type-policy=OVERRIDE, i-signal-type=PRIMITIVE, base-type=BT_EM1_01_BZ, compu {phys=raw for raw 0..15}, range phys 0..15, raw 0..15, transfer-property=PENDING  # 4bit Botschaftszähler, wird mit jeder Sendebotschaft inkrementiert
          signal EM1_Istmodus_XIX_EM1_01_XIX_E3V_EVCANFD: start 12, 4 bit, little-endian, data-type-policy=OVERRIDE, i-signal-type=PRIMITIVE, init-value=15, base-type=BT_EM1_Istmodus, compu {0=Cx0_Standby (CM_EM1_Istmodus_Cx0_Standby), 1=Cx1_Momentenreg (CM_EM1_Istmodus_Cx1_Momentenreg), 2=Cx2_Int_Drehzahlreg (CM_EM1_Istmodus_Cx2_Int_Drehzahlreg), 3=Cx3_Spannungsreg (CM_EM1_Istmodus_Cx3_Spannungsreg), 4=Cx4_Ext_Drehzahlreg (CM_EM1_Istmodus_Cx4_Ext_Drehzahlreg), 5=Cx5_Inverter_Fehler (CM_EM1_Istmodus_Cx5_Inverter_Fehler), 6=Cx6_Kalibrierung (CM_EM1_Istmodus_Cx6_Kalibrierung), 7=Cx7_Sonderbremsbetrieb (CM_EM1_Istmodus_Cx7_Sonderbremsbetrieb), 8=Cx8_Freilauf (CM_EM1_Istmodus_Cx8_Freilauf), 9=Cx9_Autonome_Synchronisation (CM_EM1_Istmodus_Cx9_Autonome_Synchronisation), 15=Cxf_Initialisierung (CM_EM1_Istmodus_Cxf_Initialisierung)}, range raw 0..15, transfer-property=PENDING  # aktuelle Betriebsart der E-Maschine... 0: Standby; Kommunikation aktiv; PSM: Aktiver Kurzschluss eingenommen 1: Momentenreglung 2: Drehzahlregeung (interner Regelkreis) 3: Spannungsregelung 4: Drehzahlregelung (externer Regelkreis) 5: interner Inverter Fehler; angeforderter Sollmodus kann nicht eingestellt werden 6: Kalibrierung / Anlernen einer neuen EM 7: Sonderbremsbetrieb 8: Freilauf 9: Autonome Synchronisation 10..14: reserve 15: Initialisierung (Hinweis: der Kommandierung kann nicht gefolgt werden)
          signal EM1_IstMoment_XIX_EM1_01_XIX_E3V_EVCANFD: start 16, 12 bit, little-endian, data-type-policy=OVERRIDE, i-signal-type=PRIMITIVE, init-value=4094, base-type=BT_EM1_IstMoment, invalid-value=Invalid_EM1_IstMoment_XIX_EM1_01_XIX_E3V_EVCANFD:4095, compu {phys=raw*0.5-1023 for raw 0..4093, 4094=Cxffe_Init (CM_EM1_IstMoment_Cxffe_Init), 4095=Cxfff_Fehler (CM_EM1_IstMoment_Cxfff_Fehler); unit Unit_NewtoMeter}, range phys -1023..1023.5 Unit_NewtoMeter, raw 0..4095, unit=Unit_NewtoMeter, transfer-property=PENDING  # Momentanwert: E-Maschinen Moment
          signal EM1_Moment_AR_Eingriff_XIX_EM1_01_XIX_E3V_EVCANFD: start 28, 12 bit, little-endian, data-type-policy=OVERRIDE, i-signal-type=PRIMITIVE, init-value=4094, base-type=BT_EM1_Moment_AR_Eingriff, invalid-value=Invalid_EM1_Moment_AR_Eingriff_XIX_EM1_01_XIX_E3V_EVCANFD:4095, compu {phys=raw*0.5-1023 for raw 0..4093, 4094=Cxffe_Init (CM_EM1_Moment_AR_Eingriff_Cxffe_Init), 4095=Cxfff_Fehler (CM_EM1_Moment_AR_Eingriff_Cxfff_Fehler); unit Unit_NewtoMeter}, range phys -1023..1023.5 Unit_NewtoMeter, raw 0..4095, unit=Unit_NewtoMeter, transfer-property=PENDING  # Momentanwert: Eingriffsmoment der Anti-Ruckel-Funktion im PWR
          signal EM1_IstDrehzahl_XIX_EM1_01_XIX_E3V_EVCANFD: start 40, 15 bit, little-endian, data-type-policy=OVERRIDE, i-signal-type=PRIMITIVE, init-value=32766, base-type=BT_EM1_IstDrehzahl, invalid-value=Invalid_EM1_IstDrehzahl_XIX_EM1_01_XIX_E3V_EVCANFD:32767, compu {phys=raw-10000 for raw 0..32765, 32766=Cx7ffe_Init (CM_EM1_IstDrehzahl_Cx7ffe_Init), 32767=Cx7fff_Fehler (CM_EM1_IstDrehzahl_Cx7fff_Fehler); unit Unit_MinutInver}, range phys -10000..22765 Unit_MinutInver, raw 0..32767, unit=Unit_MinutInver, transfer-property=PENDING  # Momentanwert: E-Maschinen Drehzahl
          signal EM1_AR_aktiv_XIX_EM1_01_XIX_E3V_EVCANFD: start 55, 1 bit, little-endian, data-type-policy=OVERRIDE, i-signal-type=PRIMITIVE, init-value=0, base-type=BT_EM1_AR_aktiv, compu {0=Cx0_Init (CM_EM1_AR_aktiv_Cx0_Init), 1=Cx1_Ruckeldaempfer_aktiv (CM_EM1_AR_aktiv_Cx1_Ruckeldaempfer_aktiv)}, range raw 0..1, transfer-property=PENDING  # Ruckeldämpfer aktiv
          signal EM1_IstSpannung_XIX_EM1_01_XIX_E3V_EVCANFD: start 56, 12 bit, little-endian, data-type-policy=OVERRIDE, i-signal-type=PRIMITIVE, init-value=4094, base-type=BT_EM1_IstSpannung, invalid-value=Invalid_EM1_IstSpannung_XIX_EM1_01_XIX_E3V_EVCANFD:4095, compu {phys=raw*0.25 for raw 0..4093, 4094=Cxffe_Init (CM_EM1_IstSpannung_Cxffe_Init), 4095=Cxfff_Fehler (CM_EM1_IstSpannung_Cxfff_Fehler); unit Unit_Volt}, range phys 0..1023.25 Unit_Volt, raw 0..4095, unit=Unit_Volt, transfer-property=PENDING  # Momentanwert: HV-Spannung am PWR
          signal EM1_Strom_HV_XIX_EM1_01_XIX_E3V_EVCANFD: start 68, 12 bit, little-endian, data-type-policy=OVERRIDE, i-signal-type=PRIMITIVE, init-value=4094, base-type=BT_EM1_Strom_HV, invalid-value=Invalid_EM1_Strom_HV_XIX_EM1_01_XIX_E3V_EVCANFD:4095, compu {phys=raw*0.5-1023 for raw 0..4093, 4094=Cxffe_Init (CM_EM1_Strom_HV_Cxffe_Init), 4095=Cxfff_Fehler (CM_EM1_Strom_HV_Cxfff_Fehler); unit Unit_Amper}, range phys -1023..1023.5 Unit_Amper, raw 0..4095, unit=Unit_Amper, transfer-property=PENDING  # Momentanwert: HV DC-Strom des PWR
          signal EM1_Max_Moment_XIX_EM1_01_XIX_E3V_EVCANFD: start 80, 11 bit, little-endian, data-type-policy=OVERRIDE, i-signal-type=PRIMITIVE, init-value=2046, base-type=BT_EM1_Max_Moment, invalid-value=Invalid_EM1_Max_Moment_XIX_EM1_01_XIX_E3V_EVCANFD:2047, compu {phys=raw-1023 for raw 0..2045, 2046=Cx7fe_Init (CM_EM1_Max_Moment_Cx7fe_Init), 2047=Cx7ff_Fehler (CM_EM1_Max_Moment_Cx7ff_Fehler); unit Unit_NewtoMeter}, range phys -1023..1022 Unit_NewtoMeter, raw 0..2047, unit=Unit_NewtoMeter, transfer-property=PENDING  # maximal darstellbares Moment für eine im Funktionslastenheft definierte Dauer Die Berechnung der Momentengrenzen wird projektspezifisch festgelegt
          signal EM1_ErwGrenzen_aktiv_XIX_EM1_01_XIX_E3V_EVCANFD: start 91, 1 bit, little-endian, data-type-policy=OVERRIDE, i-signal-type=PRIMITIVE, init-value=0, base-type=BT_EM1_ErwGrenzen_aktiv, compu {0=Cx0_kein_extended_Range (CM_EM1_ErwGrenzen_aktiv_Cx0_kein_extended_Range), 1=Cx1_extended_Range (CM_EM1_ErwGrenzen_aktiv_Cx1_extended_Range)}, range raw 0..1, transfer-property=PENDING  # Die absoluten Momentengrenzen sind für die Durchführung eines VKM-Starts ggf. aufgeweitet
          signal EM1_Min_Moment_XIX_EM1_01_XIX_E3V_EVCANFD: start 92, 11 bit, little-endian, data-type-policy=OVERRIDE, i-signal-type=PRIMITIVE, init-value=2046, base-type=BT_EM1_Min_Moment, invalid-value=Invalid_EM1_Min_Moment_XIX_EM1_01_XIX_E3V_EVCANFD:2047, compu {phys=raw-1023 for raw 0..2045, 2046=Cx7fe_Init (CM_EM1_Min_Moment_Cx7fe_Init), 2047=Cx7ff_Fehler (CM_EM1_Min_Moment_Cx7ff_Fehler); unit Unit_NewtoMeter}, range phys -1023..1022 Unit_NewtoMeter, raw 0..2047, unit=Unit_NewtoMeter, transfer-property=PENDING  # minimal darstellbares Moment für eine im Funktionslastenheft definierte Dauer Die Berechnung der Momentengrenzen wird projektspezifisch festgelegt
          signal EM1_Fehler_ElAntriebAbschaltung_XIX_EM1_01_XIX_E3V_EVCANFD: start 103, 1 bit, little-endian, data-type-policy=OVERRIDE, i-signal-type=PRIMITIVE, init-value=0, base-type=BT_EM1_Fehler_ElAntriebAbschaltung, compu {0=Cx0_Init (CM_EM1_Fehler_ElAntriebAbschaltung_Cx0_Init), 1=Cx1_Abschaltung (CM_EM1_Fehler_ElAntriebAbschaltung_Cx1_Abschaltung)}, range raw 0..1, transfer-property=PENDING  # Fehler: PWR befindet sich im aktiven Kurzschluss alle vom EMS gesendeten Max- und Min-Momente und das aktuelle EM-Moment nehmen in diesem Zustand den Wert des für die aktuelle Drehzahl entsprechenden Schleppmoments der E-Maschine an
          signal EM1_Max_Moment_Lim_XIX_EM1_01_XIX_E3V_EVCANFD: start 104, 11 bit, little-endian, data-type-policy=OVERRIDE, i-signal-type=PRIMITIVE, init-value=2046, base-type=BT_EM1_Max_Moment_Lim, invalid-value=Invalid_EM1_Max_Moment_Lim_XIX_EM1_01_XIX_E3V_EVCANFD:2047, compu {phys=raw-1023 for raw 0..2045, 2046=Cx7fe_Init (CM_EM1_Max_Moment_Lim_Cx7fe_Init), 2047=Cx7ff_Fehler (CM_EM1_Max_Moment_Lim_Cx7ff_Fehler); unit Unit_NewtoMeter}, range phys -1023..1022 Unit_NewtoMeter, raw 0..2047, unit=Unit_NewtoMeter, transfer-property=PENDING  # Maximales Moment bei der momentanen Maschinendrehzahl, motorischer Betrieb, berechnet aus Abregelstrom MO_EMx_Max_Strom_Lim und aktueller Spannung
          signal EM1_Fehler_Notabschaltung_XIX_EM1_01_XIX_E3V_EVCANFD: start 115, 1 bit, little-endian, data-type-policy=OVERRIDE, i-signal-type=PRIMITIVE, init-value=0, base-type=BT_EM1_Fehler_Notabschaltung, invalid-value=Invalid_EM1_Fehler_Notabschaltung_XIX_EM1_01_XIX_E3V_EVCANFD:1, compu {0=Cx0_kein_Fehler (CM_EM1_Fehler_Notabschaltung_Cx0_kein_Fehler), 1=Cx1_Fehler (CM_EM1_Fehler_Notabschaltung_Cx1_Fehler)}, range raw 0..1, transfer-property=PENDING  # Fehler: Leistungselektronik fordert Abschaltung des HV-Netzes wegen eines schweren Fehlers an
          signal EM1_Min_Moment_Lim_XIX_EM1_01_XIX_E3V_EVCANFD: start 116, 11 bit, little-endian, data-type-policy=OVERRIDE, i-signal-type=PRIMITIVE, init-value=2046, base-type=BT_EM1_Min_Moment_Lim, invalid-value=Invalid_EM1_Min_Moment_Lim_XIX_EM1_01_XIX_E3V_EVCANFD:2047, compu {phys=raw-1023 for raw 0..2045, 2046=Cx7fe_Init (CM_EM1_Min_Moment_Lim_Cx7fe_Init), 2047=Cx7ff_Fehler (CM_EM1_Min_Moment_Lim_Cx7ff_Fehler); unit Unit_NewtoMeter}, range phys -1023..1022 Unit_NewtoMeter, raw 0..2047, unit=Unit_NewtoMeter, transfer-property=PENDING  # Minimales Moment bei der momentanen Maschinendrehzahl, generatorischer Betrieb, berechnet aus Abregelstrom MO_EMx_Min_Strom_Lim und aktueller Spannung
          signal EM1_Status_DrzEingriff_XIX_EM1_01_XIX_E3V_EVCANFD: start 127, 2 bit, little-endian, data-type-policy=OVERRIDE, i-signal-type=PRIMITIVE, init-value=0, base-type=BT_EM1_Status_DrzEingriff, invalid-value=Invalid_EM1_Status_DrzEingriff_XIX_EM1_01_XIX_E3V_EVCANFD:3, compu {0=Cx0_kein_Eingriff (CM_EM1_Status_DrzEingriff_Cx0_kein_Eingriff), 1=Cx1_Eingriff_Max_Drehzahlregler (CM_EM1_Status_DrzEingriff_Cx1_Eingriff_Max_Drehzahlregler), 2=Cx2_Eingriff_Min_Drehzahlregler (CM_EM1_Status_DrzEingriff_Cx2_Eingriff_Min_Drehzahlregler), 3=Cx3_Fehler (CM_EM1_Status_DrzEingriff_Cx3_Fehler)}, range raw 0..3, transfer-property=PENDING  # Status ASR-Eingriff über EM-Regelung
          signal EM1_Mom_DrzEingriff_XIX_EM1_01_XIX_E3V_EVCANFD: start 129, 11 bit, little-endian, data-type-policy=OVERRIDE, i-signal-type=PRIMITIVE, init-value=2046, base-type=BT_EM1_Mom_DrzEingriff, invalid-value=Invalid_EM1_Mom_DrzEingriff_XIX_EM1_01_XIX_E3V_EVCANFD:2047, compu {phys=raw-1023 for raw 0..2045, 2046=Cx7fe_Init (CM_EM1_Mom_DrzEingriff_Cx7fe_Init), 2047=Cx7ff_Fehler (CM_EM1_Mom_DrzEingriff_Cx7ff_Fehler); unit Unit_NewtoMeter}, range phys -1023..1022 Unit_NewtoMeter, raw 0..2047, unit=Unit_NewtoMeter, transfer-property=PENDING  # Wirksames Moment der EM zum Begrenzen der Drehzahl auf Drehzahlbegrenzung
          signal EM1_Raddrehzahl_links_XIX_EM1_01_XIX_E3V_EVCANFD: start 140, 13 bit, little-endian, data-type-policy=OVERRIDE, i-signal-type=PRIMITIVE, init-value=8190, base-type=BT_EM1_Raddrehzahl_links, invalid-value=Invalid_EM1_Raddrehzahl_links_XIX_EM1_01_XIX_E3V_EVCANFD:8191, compu {phys=raw*0.3 for raw 0..8187, 8188=Cx1ffc_reserviert (CM_EM1_Raddrehzahl_links_Cx1ffc_reserviert), 8189=Cx1ffd_reserviert (CM_EM1_Raddrehzahl_links_Cx1ffd_reserviert), 8190=Cx1ffe_Init (CM_EM1_Raddrehzahl_links_Cx1ffe_Init), 8191=Cx1fff_Fehler (CM_EM1_Raddrehzahl_links_Cx1fff_Fehler); unit Unit_MinutInver}, range phys 0..2456.1 Unit_MinutInver, raw 0..8191, unit=Unit_MinutInver, transfer-property=PENDING  # Momentanwert: Raddrehzahl links (Betrag) Wird im PWR unter Nutzung der ESC-HW-Schnittstelle (Drehzahlfühler-Ausgänge im ESC) berechnet Einschränkungen: 1. QM-Signal, kein ASIL möglich 2. Nur Betragswert möglich 3. Nach Stillstand oder Drehrichtungsumkehr des Rades erfolgt die erstmalige Berechnung bzw. Neuberechnung der Raddrehzahl (d.h. Ausgabe einer Raddrehzahl ungleich Null) nach drei empfangenen Signalflanken
          signal EM1_Raddrehzahl_rechts_XIX_EM1_01_XIX_E3V_EVCANFD: start 153, 13 bit, little-endian, data-type-policy=OVERRIDE, i-signal-type=PRIMITIVE, init-value=8190, base-type=BT_EM1_Raddrehzahl_rechts, invalid-value=Invalid_EM1_Raddrehzahl_rechts_XIX_EM1_01_XIX_E3V_EVCANFD:8191, compu {phys=raw*0.3 for raw 0..8187, 8188=Cx1ffc_reserviert (CM_EM1_Raddrehzahl_rechts_Cx1ffc_reserviert), 8189=Cx1ffd_reserviert (CM_EM1_Raddrehzahl_rechts_Cx1ffd_reserviert), 8190=Cx1ffe_Init (CM_EM1_Raddrehzahl_rechts_Cx1ffe_Init), 8191=Cx1fff_Fehler (CM_EM1_Raddrehzahl_rechts_Cx1fff_Fehler); unit Unit_MinutInver}, range phys 0..2456.1 Unit_MinutInver, raw 0..8191, unit=Unit_MinutInver, transfer-property=PENDING  # Momentanwert: Raddrehzahl rechts (Betrag) Wird im PWR unter Nutzung der ESC-HW-Schnittstelle (Drehzahlfühler-Ausgänge im ESC) berechnet Einschränkungen: 1. QM-Signal, kein ASIL möglich 2. Nur Betragswert möglich 3. Nach Stillstand oder Drehrichtungsumkehr des Rades erfolgt die erstmalige Berechnung bzw. Neuberechnung der Raddrehzahl (d.h. Ausgabe einer Raddrehzahl ungleich Null) nach drei empfangenen Signalflanken
          signal EM1_Max_Moment_Gesamt_XIX_EM1_01_XIX_E3V_EVCANFD: start 166, 11 bit, little-endian, data-type-policy=OVERRIDE, i-signal-type=PRIMITIVE, init-value=2046, base-type=BT_EM1_Max_Moment_Gesamt, invalid-value=Invalid_EM1_Max_Moment_Gesamt_XIX_EM1_01_XIX_E3V_EVCANFD:2047, compu {phys=raw-1023 for raw 0..2045, 2046=Cx7fe_Init (CM_EM1_Max_Moment_Gesamt_Cx7fe_Init), 2047=Cx7ff_Fehler (CM_EM1_Max_Moment_Gesamt_Cx7ff_Fehler); unit Unit_NewtoMeter}, range phys -1023..1022 Unit_NewtoMeter, raw 0..2047, unit=Unit_NewtoMeter, transfer-property=PENDING  # Maximal mögliches Moment bei der momentanen Maschinendrehzahl bezogen auf die im System verfügbare elektrische Gesamtleistung MO_EM1_Max_Leistung_Gesamt, motorischer Betrieb
          signal EM1_Min_Moment_Gesamt_XIX_EM1_01_XIX_E3V_EVCANFD: start 177, 11 bit, little-endian, data-type-policy=OVERRIDE, i-signal-type=PRIMITIVE, init-value=2046, base-type=BT_EM1_Min_Moment_Gesamt, invalid-value=Invalid_EM1_Min_Moment_Gesamt_XIX_EM1_01_XIX_E3V_EVCANFD:2047, compu {phys=raw-1023 for raw 0..2045, 2046=Cx7fe_Init (CM_EM1_Min_Moment_Gesamt_Cx7fe_Init), 2047=Cx7ff_Fehler (CM_EM1_Min_Moment_Gesamt_Cx7ff_Fehler); unit Unit_NewtoMeter}, range phys -1023..1022 Unit_NewtoMeter, raw 0..2047, unit=Unit_NewtoMeter, transfer-property=PENDING  # Minimal mögliches Moment bei der momentanen Maschinendrehzahl bezogen auf die vom System aufnehmbare elektrische Gesamtleistung MO_EM1_Min_Leistung_Gesamt, generatorischer Betrieb
          signal EM1_MinVorlauftemperatur_XIX_EM1_01_XIX_E3V_EVCANFD: start 188, 8 bit, little-endian, data-type-policy=OVERRIDE, i-signal-type=PRIMITIVE, init-value=0, base-type=BT_EM1_MinVorlauftemperatur, compu {phys=raw*0.5-40 for raw 0..253, 254=Cxfe_Init (CM_EM1_MinVorlauftemperatur_Cxfe_Init); unit Unit_DegreCelsi}, range phys -40..86.5 Unit_DegreCelsi, raw 0..254, unit=Unit_DegreCelsi, transfer-property=PENDING, to Klima(timeout 0.5 s)  # Gewünschte minimale Temperatur des Kühlmittels am Vorlauf des PWR
          signal ELM1_FacPwrPred_XIX_EM1_01_XIX_E3V_EVCANFD: start 196, 10 bit, little-endian, data-type-policy=OVERRIDE, i-signal-type=PRIMITIVE, init-value=1023, base-type=BT_ELM1_FacPwrPred, compu {phys=raw for raw 0..1022, 1023=Cx3ff_Init (CM_ELM1_FacPwrPred_Cx3ff_Init); unit Unit_None}, range phys 0..1022 Unit_None, raw 0..1023, unit=Unit_None, transfer-property=PENDING  # Faktor zur Leistungsbestimmung ausgehend von der aktuellen Sockel-Verlustleistung
          signal ELM1_PwrLosDrvTq0_XIX_EM1_01_XIX_E3V_EVCANFD: start 206, 10 bit, little-endian, data-type-policy=OVERRIDE, i-signal-type=PRIMITIVE, init-value=1022, base-type=BT_ELM1_PwrLosDrvTq0, invalid-value=Invalid_ELM1_PwrLosDrvTq0_XIX_EM1_01_XIX_E3V_EVCANFD:1023, compu {phys=raw*15 for raw 0..1021, 1022=Cx3fe_Init (CM_ELM1_PwrLosDrvTq0_Cx3fe_Init), 1023=Cx3ff_Fehler (CM_ELM1_PwrLosDrvTq0_Cx3ff_Fehler); unit Unit_Watt}, range phys 0..15315 Unit_Watt, raw 0..1023, unit=Unit_Watt, transfer-property=PENDING  # Verlustleistung der elektrischen Antriebseinheit bei Nullmoment und aktueller Drehzahl ("Sockelverlust")
      frame ESC_51_Auth_XIX_E3V_EVCANFD: id 0xFC, to Klima, frame-length=64, can-addressing-mode=STANDARD, can-frame-rx-behavior=CAN-FD, can-frame-tx-behavior=CAN-FD
        pdu ESC_51_Auth_XIX_E3V_EVCANFD: length=60, transmission-mode-true-timing=cyclic-timing={time-offset=0.0, time-period=0.01}, unused-bit-pattern=0
          signal ESC_51_CRC_XIX_ESC_51_Auth_XIX_E3V_EVCANFD: start 0, 8 bit, little-endian, data-type-policy=OVERRIDE, i-signal-type=PRIMITIVE, base-type=BT_ESC_51_CRC, compu {phys=raw for raw 0..255}, range phys 0..255, raw 0..255, transfer-property=PENDING  # Für MLB: Berechnung siehe Lastenheft "Kommunikationsabsicherung für FlexRay und CAN" Ab MQB und MLBevo: Berechnung siehe Lastenheft "End-to-End Kommunikationsabsicherung" Endwerte siehe Begleitdokument "S-PDU Kennungsfolgen"
          signal ESC_51_BZ_XIX_ESC_51_Auth_XIX_E3V_EVCANFD: start 8, 4 bit, little-endian, data-type-policy=OVERRIDE, i-signal-type=PRIMITIVE, base-type=BT_ESC_51_BZ, compu {phys=raw for raw 0..15}, range phys 0..15, raw 0..15, transfer-property=PENDING  # 4bit Botschaftszähler, wird mit jeder Sendebotschaft inkrementiert
          signal ESC_aktBR_Modus_02_XIX_ESC_51_Auth_XIX_E3V_EVCANFD: start 12, 2 bit, little-endian, data-type-policy=OVERRIDE, i-signal-type=PRIMITIVE, init-value=0, base-type=BT_ESC_aktBR_Modus_02, compu {0=Cx0_Aktivbremsung_Aus (CM_ESC_aktBR_Modus_02_Cx0_Aktivbremsung_Aus), 1=Cx1_Aktivbremsung_FastInit (CM_ESC_aktBR_Modus_02_Cx1_Aktivbremsung_FastInit), 2=Cx2_Aktivbremsung_Aktiv (CM_ESC_aktBR_Modus_02_Cx2_Aktivbremsung_Aktiv), 3=Cx3_Aktivbremsung_NoLimitAktiv (CM_ESC_aktBR_Modus_02_Cx3_Aktivbremsung_NoLimitAktiv)}, range raw 0..3, transfer-property=PENDING  # Kontext des Signals ESC_aktBr_Modus_02: 0: AktivBremsung per eBKV nicht aktiv 1: ESC fordert eine schnelle Initialisierung vom eBKV beim Wecken 2: Aktivbremsung per eBKV aktiv 3: Aktivbremsung per eBKV aktiv ohne Begrenzung durch "Fahrer bremst" Erkennung
          signal ESC_Blending_Solldruck_XIX_ESC_51_Auth_XIX_E3V_EVCANFD: start 14, 10 bit, little-endian, data-type-policy=OVERRIDE, i-signal-type=PRIMITIVE, init-value=1022, base-type=BT_ESC_Blending_Solldruck, invalid-value=Invalid_ESC_Blending_Solldruck_XIX_ESC_51_Auth_XIX_E3V_EVCANFD:1023, compu {phys=raw*0.25 for raw 0..1000, 1022=Cx3fe_Init (CM_ESC_Blending_Solldruck_Cx3fe_Init), 1023=Cx3ff_Fehler (CM_ESC_Blending_Solldruck_Cx3ff_Fehler); unit Unit_Bar}, range phys 0..250 Unit_Bar, raw 0..1023, unit=Unit_Bar, transfer-property=PENDING  # Zieldruck während Rekuperation. Das Signal ist spezifisch aufbereitet und wird für die Pedakraftkompensation im eBKV genutzt. MQB/MQB2020: Wird nur von einem blendfähigen ESC unterstützt, wie es in mHEV und pHEV Fahrzeugen eingesetzt wird.
          signal ESC_aktBr_Volumenstrom_XIX_ESC_51_Auth_XIX_E3V_EVCANFD: start 24, 16 bit, little-endian, data-type-policy=OVERRIDE, i-signal-type=PRIMITIVE, init-value=32256, base-type=BT_ESC_aktBr_Volumenstrom, compu {phys=raw/128-252 for raw 0..64512; unit Unit_MilliLiterPerSec}, range phys -252..252 Unit_MilliLiterPerSec, raw 0..64512, unit=Unit_MilliLiterPerSec, transfer-property=PENDING  # Volumenstromvorgabe für Aktivbremsung per eBKV, Kontext des Volumenstroms wird im Signal ESC_aktBr_Modus übertragen
          signal ESC_EBKV_Kraftblending_Modus_XIX_ESC_51_Auth_XIX_E3V_EVCANFD: start 40, 2 bit, little-endian, data-type-policy=OVERRIDE, i-signal-type=PRIMITIVE, init-value=0, base-type=BT_ESC_EBKV_Kraftblending_Modus, compu {0=Cx0_Inactive (CM_ESC_EBKV_Kraftblending_Modus_Cx0_Inactive), 1=Cx1_Hold (CM_ESC_EBKV_Kraftblending_Modus_Cx1_Hold), 2=Cx2_Active (CM_ESC_EBKV_Kraftblending_Modus_Cx2_Active)}, range raw 0..2, transfer-property=PENDING  # Freigabe der Pedalkraftkompensation (Funktion des eBKV) MQB/MQB2020: Wird nur von einem blendfähigen ESC unterstützt, wie es in mHEV und pHEV Fahrzeugen eingesetzt wird.
          signal ESC_Bremsdruck_Modell_XIX_ESC_51_Auth_XIX_E3V_EVCANFD: start 42, 10 bit, little-endian, data-type-policy=OVERRIDE, i-signal-type=PRIMITIVE, init-value=1022, base-type=BT_ESC_Bremsdruck_Modell, invalid-value=Invalid_ESC_Bremsdruck_Modell_XIX_ESC_51_Auth_XIX_E3V_EVCANFD:1023, compu {phys=raw*0.25 for raw 0..1000, 1022=Cx3fe_Init (CM_ESC_Bremsdruck_Modell_Cx3fe_Init), 1023=Cx3ff_Fehler (CM_ESC_Bremsdruck_Modell_Cx3ff_Fehler); unit Unit_Bar}, range phys 0..250 Unit_Bar, raw 0..1023, unit=Unit_Bar, transfer-property=PENDING  # Virtueller, aus dem Wert "EBKV_Stangenweg_Fahrerwunsch" berechneter Hauptzylinderdruck. Während einer hydraulischen Bremsung entspricht dieser Druck nahezu dem "ESC_Bremsdruck_02". Während einer Bremsung mit Rekuperation ist es ein berechneter Wert, der dem Fahrerwunschdruck entspricht. Dieser Wert wird z.B. für die Pedalkraftkompensation im eBKV genutzt.
          signal ESC_Bremsdruck_02_XIX_ESC_51_Auth_XIX_E3V_EVCANFD: start 52, 10 bit, little-endian, data-type-policy=OVERRIDE, i-signal-type=PRIMITIVE, init-value=100, base-type=BT_ESC_Bremsdruck_02, invalid-value=Invalid_ESC_Bremsdruck_02_XIX_ESC_51_Auth_XIX_E3V_EVCANFD:1023, compu {phys=raw*0.3-30 for raw 0..1022, 1023=Cx3ff_Fehler (CM_ESC_Bremsdruck_02_Cx3ff_Fehler); unit Unit_Bar}, range phys -30..276.6 Unit_Bar, raw 0..1023, unit=Unit_Bar, transfer-property=PENDING  # Rohwert des Bremsdrucks Für Fahrzeuge mit elektrischem Bremskraftverstärker gilt: Aus dem Signal ESC_Bremsdruck_02 lässt sich kein Fahrerbremswunsch ableiten. Das Signal bildet lediglich den hydraulischen Anteil der Fahrzeugverzögerung ab. Der Rohwert des Signals kann auch ohne Fahrerbeteiligung (ohne Betätigung des Bremspedals) variieren. (z.B. ACC,AWV, Autohold). Für HEV/PHEV gilt: Während einer Bremsung mit überlagertem Generatorbremsmoment ist der angezeigte Druck kleiner als der Fahrerbremswunsch. Für Fahrzeuge mit Vakuum-Bremskraftverstärker gilt: Rohwert des Bremsdrucks [Vordruck durch Fahrervorgabe (Pvor). Bei aktivem Druckaufbau (Stabilisierungseingriffe) kein Pvor]
          signal ESC_QBit_Bremsdruck_02_XIX_ESC_51_Auth_XIX_E3V_EVCANFD: start 62, 1 bit, little-endian, data-type-policy=OVERRIDE, i-signal-type=PRIMITIVE, init-value=1, base-type=BT_ESC_QBit_Bremsdruck_02, compu {0=Cx0_gueltiger_Wert (CM_ESC_QBit_Bremsdruck_02_Cx0_gueltiger_Wert), 1=Cx1_Ersatz_Init_oder_Fehlerwert (CM_ESC_QBit_Bremsdruck_02_Cx1_Ersatz_Init_oder_Fehlerwert)}, range raw 0..1, transfer-property=PENDING  # QBit des ESC_Bremsdruck_02. Gesetzt bei Ersatzwert, Init oder Fehler.
          signal ESC_Allradverteilung_aktiv_XIX_ESC_51_Auth_XIX_E3V_EVCANFD: start 63, 1 bit, little-endian, data-type-policy=OVERRIDE, i-signal-type=PRIMITIVE, init-value=0, base-type=BT_ESC_Allradverteilung_aktiv, compu {0=Cx0_kein_Eingriff (CM_ESC_Allradverteilung_aktiv_Cx0_kein_Eingriff), 1=Cx1_Allradeingriff_aktiv (CM_ESC_Allradverteilung_aktiv_Cx1_Allradeingriff_aktiv)}, range raw 0..1, transfer-property=PENDING  # Allradumverteilung aus BRS aktiv und vom ASG umzusetzen
          signal ESP_HL_Radgeschw_02_XIX_ESC_51_Auth_XIX_E3V_EVCANFD: start 64, 16 bit, little-endian, data-type-policy=OVERRIDE, i-signal-type=PRIMITIVE, init-value=65534, base-type=BT_ESP_HL_Radgeschw_02, invalid-value=Invalid_ESP_HL_Radgeschw_02_XIX_ESC_51_Auth_XIX_E3V_EVCANFD:65535, compu {phys=raw*0.0075 for raw 0..65532, 65533=Cxfffd_Unterspannung (CM_ESP_HL_Radgeschw_02_Cxfffd_Unterspannung), 65534=Cxfffe_Init (CM_ESP_HL_Radgeschw_02_Cxfffe_Init), 65535=Cxffff_Fehler (CM_ESP_HL_Radgeschw_02_Cxffff_Fehler); unit Unit_KiloMeterPerHour}, range phys 0..491.49 Unit_KiloMeterPerHour, raw 0..65535, unit=Unit_KiloMeterPerHour, transfer-property=PENDING  # Radgeschwindigkeit hinten links
          signal ESP_HR_Radgeschw_02_XIX_ESC_51_Auth_XIX_E3V_EVCANFD: start 80, 16 bit, little-endian, data-type-policy=OVERRIDE, i-signal-type=PRIMITIVE, init-value=65534, base-type=BT_ESP_HR_Radgeschw_02, invalid-value=Invalid_ESP_HR_Radgeschw_02_XIX_ESC_51_Auth_XIX_E3V_EVCANFD:65535, compu {phys=raw*0.0075 for raw 0..65532, 65533=Cxfffd_Unterspannung (CM_ESP_HR_Radgeschw_02_Cxfffd_Unterspannung), 65534=Cxfffe_Init (CM_ESP_HR_Radgeschw_02_Cxfffe_Init), 65535=Cxffff_Fehler (CM_ESP_HR_Radgeschw_02_Cxffff_Fehler); unit Unit_KiloMeterPerHour}, range phys 0..491.49 Unit_KiloMeterPerHour, raw 0..65535, unit=Unit_KiloMeterPerHour, transfer-property=PENDING  # Radgeschwindigkeit hinten rechts
          signal ESP_VL_Radgeschw_02_XIX_ESC_51_Auth_XIX_E3V_EVCANFD: start 96, 16 bit, little-endian, data-type-policy=OVERRIDE, i-signal-type=PRIMITIVE, init-value=65534, base-type=BT_ESP_VL_Radgeschw_02, invalid-value=Invalid_ESP_VL_Radgeschw_02_XIX_ESC_51_Auth_XIX_E3V_EVCANFD:65535, compu {phys=raw*0.0075 for raw 0..65532, 65533=Cxfffd_Unterspannung (CM_ESP_VL_Radgeschw_02_Cxfffd_Unterspannung), 65534=Cxfffe_Init (CM_ESP_VL_Radgeschw_02_Cxfffe_Init), 65535=Cxffff_Fehler (CM_ESP_VL_Radgeschw_02_Cxffff_Fehler); unit Unit_KiloMeterPerHour}, range phys 0..491.49 Unit_KiloMeterPerHour, raw 0..65535, unit=Unit_KiloMeterPerHour, transfer-property=PENDING  # Radgeschwindigkeit vorne links
          signal ESP_VR_Radgeschw_02_XIX_ESC_51_Auth_XIX_E3V_EVCANFD: start 112, 16 bit, little-endian, data-type-policy=OVERRIDE, i-signal-type=PRIMITIVE, init-value=65534, base-type=BT_ESP_VR_Radgeschw_02, invalid-value=Invalid_ESP_VR_Radgeschw_02_XIX_ESC_51_Auth_XIX_E3V_EVCANFD:65535, compu {phys=raw*0.0075 for raw 0..65532, 65533=Cxfffd_Unterspannung (CM_ESP_VR_Radgeschw_02_Cxfffd_Unterspannung), 65534=Cxfffe_Init (CM_ESP_VR_Radgeschw_02_Cxfffe_Init), 65535=Cxffff_Fehler (CM_ESP_VR_Radgeschw_02_Cxffff_Fehler); unit Unit_KiloMeterPerHour}, range phys 0..491.49 Unit_KiloMeterPerHour, raw 0..65535, unit=Unit_KiloMeterPerHour, transfer-property=PENDING  # Radgeschwindigkeit vorne rechts
          signal ESP_FZR_uebersteuern_XIX_ESC_51_Auth_XIX_E3V_EVCANFD: start 128, 8 bit, little-endian, data-type-policy=OVERRIDE, i-signal-type=PRIMITIVE, init-value=254, base-type=BT_ESP_FZR_uebersteuern, invalid-value=Invalid_ESP_FZR_uebersteuern_XIX_ESC_51_Auth_XIX_E3V_EVCANFD:255, compu {phys=raw*0.004 for raw 0..250, 254=Cxfe_Init (CM_ESP_FZR_uebersteuern_Cxfe_Init), 255=Cxff_Fehler (CM_ESP_FZR_uebersteuern_Cxff_Fehler)}, range phys 0..1, raw 0..255, transfer-property=PENDING  # Fahrzeug erkennt uebersteuern
          signal ESP_FZR_untersteuern_XIX_ESC_51_Auth_XIX_E3V_EVCANFD: start 136, 8 bit, little-endian, data-type-policy=OVERRIDE, i-signal-type=PRIMITIVE, init-value=254, base-type=BT_ESP_FZR_untersteuern, invalid-value=Invalid_ESP_FZR_untersteuern_XIX_ESC_51_Auth_XIX_E3V_EVCANFD:255, compu {phys=raw*0.004 for raw 0..250, 254=Cxfe_Init (CM_ESP_FZR_untersteuern_Cxfe_Init), 255=Cxff_Fehler (CM_ESP_FZR_untersteuern_Cxff_Fehler)}, range phys 0..1, raw 0..255, transfer-property=PENDING  # Fahrzeug erkennt untersteuern
          signal ESC_Anf_Mindestreku_XIX_ESC_51_Auth_XIX_E3V_EVCANFD: start 144, 1 bit, little-endian, data-type-policy=OVERRIDE, i-signal-type=PRIMITIVE, init-value=0, base-type=BT_ESC_Anf_Mindestreku, compu {0=Cx0_nicht_angefordert (CM_ESC_Anf_Mindestreku_Cx0_nicht_angefordert), 1=Cx1_angefordert (CM_ESC_Anf_Mindestreku_Cx1_angefordert)}, range raw 0..1, transfer-property=PENDING, to Klima(timeout 0.5 s)  # Bei Wert == 1 soll durch den Antrieb eine im Projekt definierte Mindestrekuperationsleistung des E-Antriebs zur Anforderung durch das Bremssystem schnellst möglich frei gegeben werden. Dies dient zur Entlastung der Reibbremse.
          signal ESC_GMV_aktiv_XIX_ESC_51_Auth_XIX_E3V_EVCANFD: start 145, 3 bit, little-endian, data-type-policy=OVERRIDE, i-signal-type=PRIMITIVE, init-value=0, base-type=BT_ESC_GMV_aktiv, compu {0=Cx0_keine_Aktivitaet (CM_ESC_GMV_aktiv_Cx0_keine_Aktivitaet), 1=Cx1_Aktivitaet_durch_AWA (CM_ESC_GMV_aktiv_Cx1_Aktivitaet_durch_AWA)}, range raw 0..1, transfer-property=PENDING  # Rueckmeldung Giermomentvorgabe aktiv
          signal ESC_GMV_nicht_verfuegbar_XIX_ESC_51_Auth_XIX_E3V_EVCANFD: start 148, 1 bit, little-endian, data-type-policy=OVERRIDE, i-signal-type=PRIMITIVE, init-value=1, base-type=BT_ESC_GMV_nicht_verfuegbar, compu {0=Cx0_verfuegbar (CM_ESC_GMV_nicht_verfuegbar_Cx0_verfuegbar), 1=Cx1_nicht_verfuegbar (CM_ESC_GMV_nicht_verfuegbar_Cx1_nicht_verfuegbar)}, range raw 0..1, transfer-property=PENDING  # Rueckmeldung Giermomentvorgabe nicht verfuegbar
          signal ESC_Status_vRef_Stuetzeingriff_XIX_ESC_51_Auth_XIX_E3V_EVCANFD: start 149, 1 bit, little-endian, data-type-policy=OVERRIDE, i-signal-type=PRIMITIVE, init-value=0, base-type=BT_ESC_Status_vRef_Stuetzeingriff, compu {0=Cx0_kein_Eingriff (CM_ESC_Status_vRef_Stuetzeingriff_Cx0_kein_Eingriff), 1=Cx1_Stuetzungseingriff (CM_ESC_Status_vRef_Stuetzeingriff_Cx1_Stuetzungseingriff)}, range raw 0..1, transfer-property=PENDING  # Das Signal qualifiziert eine Momentenreduzierung an der Hinterachse zur Stützung der ESC Referenzgeschwindigkeit. Die Reduzierung erfolgt über die Signale ESC_MomRad_Eingriff bzw ESC_MomRad_Eingriff_sek
          signal FDR_Allradverteilung_aktiv_XIX_ESC_51_Auth_XIX_E3V_EVCANFD: start 150, 1 bit, little-endian, data-type-policy=OVERRIDE, i-signal-type=PRIMITIVE, init-value=0, base-type=BT_FDR_Allradverteilung_aktiv, compu {0=Cx0_kein_Eingriff (CM_FDR_Allradverteilung_aktiv_Cx0_kein_Eingriff), 1=Cx1_Allradeingriff_aktiv (CM_FDR_Allradverteilung_aktiv_Cx1_Allradeingriff_aktiv)}, range raw 0..1, transfer-property=PENDING  # Allradumverteilung aus FDR aktiv und vom MSG umzusetzen
          signal FDR_Anf_Allradbetrieb_XIX_ESC_51_Auth_XIX_E3V_EVCANFD: start 151, 1 bit, little-endian, data-type-policy=OVERRIDE, i-signal-type=PRIMITIVE, init-value=0, base-type=BT_FDR_Anf_Allradbetrieb, compu {0=Cx0_keine_Anforderung (CM_FDR_Anf_Allradbetrieb_Cx0_keine_Anforderung), 1=Cx1_Kraftschluss_an_beiden_Achsen_herstellen (CM_FDR_Anf_Allradbetrieb_Cx1_Kraftschluss_an_beiden_Achsen_herstellen)}, range raw 0..1, transfer-property=PENDING  # Anforderung des Fahrdynamikreglers an MSG zur Aktivierung des Allradbetriebs.
          signal ESP_HL_Bremsmoment_XIX_ESC_51_Auth_XIX_E3V_EVCANFD: start 152, 8 bit, little-endian, data-type-policy=OVERRIDE, i-signal-type=PRIMITIVE, init-value=254, base-type=BT_ESP_HL_Bremsmoment, invalid-value=Invalid_ESP_HL_Bremsmoment_XIX_ESC_51_Auth_XIX_E3V_EVCANFD:255, compu {phys=raw*20 for raw 0..253, 254=Cxfe_Init (CM_ESP_HL_Bremsmoment_Cxfe_Init), 255=Cxff_Fehler (CM_ESP_HL_Bremsmoment_Cxff_Fehler); unit Unit_NewtoMeter}, range phys 0..5060 Unit_NewtoMeter, raw 0..255, unit=Unit_NewtoMeter, transfer-property=PENDING  # Bremsmoment HL Ausgabe nach LAH: Ausgabe der internen Radbremsmomente / Radbremsdrücke / durch das ESP
          signal ESP_HR_Bremsmoment_XIX_ESC_51_Auth_XIX_E3V_EVCANFD: start 160, 8 bit, little-endian, data-type-policy=OVERRIDE, i-signal-type=PRIMITIVE, init-value=254, base-type=BT_ESP_HR_Bremsmoment, invalid-value=Invalid_ESP_HR_Bremsmoment_XIX_ESC_51_Auth_XIX_E3V_EVCANFD:255, compu {phys=raw*20 for raw 0..253, 254=Cxfe_Init (CM_ESP_HR_Bremsmoment_Cxfe_Init), 255=Cxff_Fehler (CM_ESP_HR_Bremsmoment_Cxff_Fehler); unit Unit_NewtoMeter}, range phys 0..5060 Unit_NewtoMeter, raw 0..255, unit=Unit_NewtoMeter, transfer-property=PENDING  # Bremsmoment HR Ausgabe nach LAH: Ausgabe der internen Radbremsmomente / Radbremsdrücke / durch das ESP
          signal ESP_VR_Bremsmoment_XIX_ESC_51_Auth_XIX_E3V_EVCANFD: start 168, 8 bit, little-endian, data-type-policy=OVERRIDE, i-signal-type=PRIMITIVE, init-value=254, base-type=BT_ESP_VR_Bremsmoment, invalid-value=Invalid_ESP_VR_Bremsmoment_XIX_ESC_51_Auth_XIX_E3V_EVCANFD:255, compu {phys=raw*40 for raw 0..253, 254=Cxfe_Init (CM_ESP_VR_Bremsmoment_Cxfe_Init), 255=Cxff_Fehler (CM_ESP_VR_Bremsmoment_Cxff_Fehler); unit Unit_NewtoMeter}, range phys 0..10120 Unit_NewtoMeter, raw 0..255, unit=Unit_NewtoMeter, transfer-property=PENDING  # Bremsmoment VR Ausgabe nach LAH: Ausgabe der internen Radbremsmomente / Radbremsdrücke / durch das ESP
          signal ESP_VL_Bremsmoment_XIX_ESC_51_Auth_XIX_E3V_EVCANFD: start 176, 8 bit, little-endian, data-type-policy=OVERRIDE, i-signal-type=PRIMITIVE, init-value=254, base-type=BT_ESP_VL_Bremsmoment, invalid-value=Invalid_ESP_VL_Bremsmoment_XIX_ESC_51_Auth_XIX_E3V_EVCANFD:255, compu {phys=raw*40 for raw 0..253, 254=Cxfe_Init (CM_ESP_VL_Bremsmoment_Cxfe_Init), 255=Cxff_Fehler (CM_ESP_VL_Bremsmoment_Cxff_Fehler); unit Unit_NewtoMeter}, range phys 0..10120 Unit_NewtoMeter, raw 0..255, unit=Unit_NewtoMeter, transfer-property=PENDING  # Bremsmoment VL Ausgabe nach LAH: Ausgabe der internen Radbremsmomente / Radbremsdrücke / durch das ESP
          signal ESP_FDR_uebersteuern_XIX_ESC_51_Auth_XIX_E3V_EVCANFD: start 184, 8 bit, little-endian, data-type-policy=OVERRIDE, i-signal-type=PRIMITIVE, init-value=254, base-type=BT_ESP_FDR_uebersteuern, invalid-value=Invalid_ESP_FDR_uebersteuern_XIX_ESC_51_Auth_XIX_E3V_EVCANFD:255, compu {phys=raw*0.004 for raw 0..250, 254=Cxfe_Init (CM_ESP_FDR_uebersteuern_Cxfe_Init), 255=Cxff_Fehler (CM_ESP_FDR_uebersteuern_Cxff_Fehler)}, range phys 0..1, raw 0..255, transfer-property=PENDING  # Modularer Fahrdynamikregler erkennt Übersteuern. Bei Integration modularer Fahrdynamikregler in ESC MEB: Verwendung durch eAllradfunktion in MSG.
          signal ESP_FDR_untersteuern_XIX_ESC_51_Auth_XIX_E3V_EVCANFD: start 192, 8 bit, little-endian, data-type-policy=OVERRIDE, i-signal-type=PRIMITIVE, init-value=254, base-type=BT_ESP_FDR_untersteuern, invalid-value=Invalid_ESP_FDR_untersteuern_XIX_ESC_51_Auth_XIX_E3V_EVCANFD:255, compu {phys=raw*0.004 for raw 0..250, 254=Cxfe_Init (CM_ESP_FDR_untersteuern_Cxfe_Init), 255=Cxff_Fehler (CM_ESP_FDR_untersteuern_Cxff_Fehler)}, range phys 0..1, raw 0..255, transfer-property=PENDING  # Modularer Fahrdynamikregler erkennt Untersteuern. Bei Integration modularer Fahrdynamikregler in ESC MEB: Verwendung durch eAllradfunktion in MSG.
          signal TSMomBegrenzung_XIX_ESC_51_Auth_XIX_E3V_EVCANFD: start 268, 12 bit, little-endian, data-type-policy=OVERRIDE, i-signal-type=PRIMITIVE, init-value=4094, base-type=BT_TSMomBegrenzung, invalid-value=Invalid_TSMomBegrenzung_XIX_ESC_51_Auth_XIX_E3V_EVCANFD:4095, compu {phys=raw*3-12279 for raw 0..4093, 4094=Cxffe_Init (CM_TSMomBegrenzung_Cxffe_Init), 4095=Cxfff_Fehler (CM_TSMomBegrenzung_Cxfff_Fehler)}, range phys -12279..0, raw 0..4095, transfer-property=PENDING  # In MLBevo Faktor in TS_Faktor_Radmomente beachten! Begrenzung des verzögernd wirkenden Antriebsstrangsollmomentenanteil auf Summenradebene
          signal ESC_Allrad_Anteil_max_sek_XIX_ESC_51_Auth_XIX_E3V_EVCANFD: start 280, 9 bit, little-endian, data-type-policy=OVERRIDE, i-signal-type=PRIMITIVE, init-value=510, base-type=BT_ESC_Allrad_Anteil_max_sek, invalid-value=Invalid_ESC_Allrad_Anteil_max_sek_XIX_ESC_51_Auth_XIX_E3V_EVCANFD:511, compu {phys=raw*0.2 for raw 0..500, 510=Cx1fe_Init (CM_ESC_Allrad_Anteil_max_sek_Cx1fe_Init), 511=Cx1ff_Fehler (CM_ESC_Allrad_Anteil_max_sek_Cx1ff_Fehler); unit Unit_PerCent}, range phys 0..100 Unit_PerCent, raw 0..511, unit=Unit_PerCent, transfer-property=PENDING  # Maximaler prozentualer Anteil der sekundären Antriebsachse am Gesamtmoment - wird soweit dies durch die Leistungsfähigkeit der Achse möglich ist eingehalten
          signal ESC_Allrad_Anteil_min_sek_XIX_ESC_51_Auth_XIX_E3V_EVCANFD: start 289, 9 bit, little-endian, data-type-policy=OVERRIDE, i-signal-type=PRIMITIVE, init-value=510, base-type=BT_ESC_Allrad_Anteil_min_sek, invalid-value=Invalid_ESC_Allrad_Anteil_min_sek_XIX_ESC_51_Auth_XIX_E3V_EVCANFD:511, compu {phys=raw*0.2 for raw 0..500, 510=Cx1fe_Init (CM_ESC_Allrad_Anteil_min_sek_Cx1fe_Init), 511=Cx1ff_Fehler (CM_ESC_Allrad_Anteil_min_sek_Cx1ff_Fehler); unit Unit_PerCent}, range phys 0..100 Unit_PerCent, raw 0..511, unit=Unit_PerCent, transfer-property=PENDING  # Minimaler prozentualer Anteil der sekundären Antriebsachse am Gesamtmoment - wird soweit dies durch die Leistungsfähigkeit der Achse möglich ist eingehalten
          signal ESC_Status_Eingriff_XIX_ESC_51_Auth_XIX_E3V_EVCANFD: start 298, 2 bit, little-endian, data-type-policy=OVERRIDE, i-signal-type=PRIMITIVE, init-value=0, base-type=BT_ESC_Status_Eingriff, compu {0=Cx0_kein_Eingriff (CM_ESC_Status_Eingriff_Cx0_kein_Eingriff) (kein Eingriff), 1=Cx1_ASR_Eingriff (CM_ESC_Status_Eingriff_Cx1_ASR_Eingriff) (ASR-Eingriff), 2=Cx2_MSR_Eingriff (CM_ESC_Status_Eingriff_Cx2_MSR_Eingriff) (MSR-Eingriff), 3=Cx3_nicht_belegt (CM_ESC_Status_Eingriff_Cx3_nicht_belegt) (nicht belegt)}, range raw 0..3, transfer-property=PENDING  # Das Signal qualifiziert „ESC_MomRad_Eingriff“ und gibt an, wie dieses Signal umzusetzen ist
          signal ESC_Status_Eingriff_sek_XIX_ESC_51_Auth_XIX_E3V_EVCANFD: start 300, 2 bit, little-endian, data-type-policy=OVERRIDE, i-signal-type=PRIMITIVE, init-value=0, base-type=BT_ESC_Status_Eingriff_sek, compu {0=Cx0_kein_Eingriff (CM_ESC_Status_Eingriff_sek_Cx0_kein_Eingriff) (kein Eingriff), 1=Cx1_ASR_Eingriff (CM_ESC_Status_Eingriff_sek_Cx1_ASR_Eingriff) (ASR-Eingriff), 2=Cx2_MSR_Eingriff (CM_ESC_Status_Eingriff_sek_Cx2_MSR_Eingriff) (MSR-Eingriff), 3=Cx3_nicht_belegt (CM_ESC_Status_Eingriff_sek_Cx3_nicht_belegt) (nicht belegt)}, range raw 0..3, transfer-property=PENDING  # Das Signal qualifiziert „ESC_MomRad_Eingriff_sek“ und gibt an, wie dieses Signal umzusetzen ist
          signal ESC_MomRad_Eingriff_XIX_ESC_51_Auth_XIX_E3V_EVCANFD: start 302, 13 bit, little-endian, data-type-policy=OVERRIDE, i-signal-type=PRIMITIVE, init-value=8190, base-type=BT_ESC_MomRad_Eingriff, invalid-value=Invalid_ESC_MomRad_Eingriff_XIX_ESC_51_Auth_XIX_E3V_EVCANFD:8191, compu {phys=raw*3-12279 for raw 0..8186, 8190=Cx1ffe_Init (CM_ESC_MomRad_Eingriff_Cx1ffe_Init), 8191=Cx1fff_Fehler (CM_ESC_MomRad_Eingriff_Cx1fff_Fehler); unit Unit_None}, range phys -12279..12279 Unit_None, raw 0..8191, unit=Unit_None, transfer-property=PENDING  # Eingriffs-Momenten-Anforderung vom ESC an das ASG für die primäre Achse; auf Bezugsebene „Moment am Rad; Faktor in TS_Faktor_Radmomente beachten!
          signal ESC_MomRad_Eingriff_sek_XIX_ESC_51_Auth_XIX_E3V_EVCANFD: start 315, 13 bit, little-endian, data-type-policy=OVERRIDE, i-signal-type=PRIMITIVE, init-value=8190, base-type=BT_ESC_MomRad_Eingriff_sek, invalid-value=Invalid_ESC_MomRad_Eingriff_sek_XIX_ESC_51_Auth_XIX_E3V_EVCANFD:8191, compu {phys=raw*3-12279 for raw 0..8186, 8190=Cx1ffe_Init (CM_ESC_MomRad_Eingriff_sek_Cx1ffe_Init), 8191=Cx1fff_Fehler (CM_ESC_MomRad_Eingriff_sek_Cx1fff_Fehler); unit Unit_None}, range phys -12279..12279 Unit_None, raw 0..8191, unit=Unit_None, transfer-property=PENDING  # Eingriffs-Momenten-Anforderung vom ESC an das ASG für die sekundäre Achse; auf Bezugsebene „Moment am Rad; Faktor in TS_Faktor_Radmomente beachten! Signal ist nur relevant für mechanisch getrennte Achsantriebe (z. B. equattro)
          signal ESC_Achsdrehzahl_Max_XIX_ESC_51_Auth_XIX_E3V_EVCANFD: start 328, 14 bit, little-endian, data-type-policy=OVERRIDE, i-signal-type=PRIMITIVE, init-value=16382, base-type=BT_ESC_Achsdrehzahl_Max, invalid-value=Invalid_ESC_Achsdrehzahl_Max_XIX_ESC_51_Auth_XIX_E3V_EVCANFD:16383, compu {phys=raw*0.4-800 for raw 0..16381, 16382=Cx3ffe_Init (CM_ESC_Achsdrehzahl_Max_Cx3ffe_Init), 16383=Cx3fff_Fehler (CM_ESC_Achsdrehzahl_Max_Cx3fff_Fehler); unit Unit_MinutInver}, range phys -800..5752.4 Unit_MinutInver, raw 0..16383, unit=Unit_MinutInver, transfer-property=PENDING  # Limit Achsdrehzahl für die Primärachse
          signal ESC_Achsdrehzahl_Min_XIX_ESC_51_Auth_XIX_E3V_EVCANFD: start 342, 14 bit, little-endian, data-type-policy=OVERRIDE, i-signal-type=PRIMITIVE, init-value=16382, base-type=BT_ESC_Achsdrehzahl_Min, invalid-value=Invalid_ESC_Achsdrehzahl_Min_XIX_ESC_51_Auth_XIX_E3V_EVCANFD:16383, compu {phys=raw*0.4-800 for raw 0..16381, 16382=Cx3ffe_Init (CM_ESC_Achsdrehzahl_Min_Cx3ffe_Init), 16383=Cx3fff_Fehler (CM_ESC_Achsdrehzahl_Min_Cx3fff_Fehler); unit Unit_MinutInver}, range phys -800..5752.4 Unit_MinutInver, raw 0..16383, unit=Unit_MinutInver, transfer-property=PENDING  # Limit Achsdrehzahl für die Primärachse
          signal ESC_Achsdrehzahl_Max_sek_XIX_ESC_51_Auth_XIX_E3V_EVCANFD: start 356, 14 bit, little-endian, data-type-policy=OVERRIDE, i-signal-type=PRIMITIVE, init-value=16382, base-type=BT_ESC_Achsdrehzahl_Max_sek, invalid-value=Invalid_ESC_Achsdrehzahl_Max_sek_XIX_ESC_51_Auth_XIX_E3V_EVCANFD:16383, compu {phys=raw*0.4-800 for raw 0..16381, 16382=Cx3ffe_Init (CM_ESC_Achsdrehzahl_Max_sek_Cx3ffe_Init), 16383=Cx3fff_Fehler (CM_ESC_Achsdrehzahl_Max_sek_Cx3fff_Fehler); unit Unit_MinutInver}, range phys -800..5752.4 Unit_MinutInver, raw 0..16383, unit=Unit_MinutInver, transfer-property=PENDING  # Limit Achsdrehzahl für die Sekundärachse
          signal ESC_Achsdrehzahl_Min_sek_XIX_ESC_51_Auth_XIX_E3V_EVCANFD: start 370, 14 bit, little-endian, data-type-policy=OVERRIDE, i-signal-type=PRIMITIVE, init-value=16382, base-type=BT_ESC_Achsdrehzahl_Min_sek, invalid-value=Invalid_ESC_Achsdrehzahl_Min_sek_XIX_ESC_51_Auth_XIX_E3V_EVCANFD:16383, compu {phys=raw*0.4-800 for raw 0..16381, 16382=Cx3ffe_Init (CM_ESC_Achsdrehzahl_Min_sek_Cx3ffe_Init), 16383=Cx3fff_Fehler (CM_ESC_Achsdrehzahl_Min_sek_Cx3fff_Fehler); unit Unit_MinutInver}, range phys -800..5752.4 Unit_MinutInver, raw 0..16383, unit=Unit_MinutInver, transfer-property=PENDING  # Limit Achsdrehzahl für die Sekundärachse
      frame ESP_21_XIX_E3V_EVCANFD: id 0xFD, to Klima, frame-length=8, can-addressing-mode=STANDARD, can-frame-rx-behavior=CAN-FD, can-frame-tx-behavior=CAN-FD
        pdu ESP_21_XIX_E3V_EVCANFD: length=8, transmission-mode-true-timing=cyclic-timing={time-offset=0.0, time-period=0.02}, unused-bit-pattern=0  # Neue Momente im MQB Struktur ab MQB mit CRC8 entstanden aus ESP_01
          signal ESP_21_CRC_XIX_ESP_21_XIX_E3V_EVCANFD: start 0, 8 bit, little-endian, data-type-policy=OVERRIDE, i-signal-type=PRIMITIVE, base-type=BT_ESP_21_CRC, compu {phys=raw for raw 0..255}, range phys 0..255, raw 0..255, transfer-property=PENDING  # Für MLB: "Berechnung siehe Lastenheft "Kommunikationsabsicherung für FlexRay und CAN"" Ab MQB und MLBevo: "Berechnung siehe Lastenheft "End-to-End Kommunikationsabsicherung"" Endwerte siehe Begleitdokument "S-PDU Kennungsfolgen"
          signal ESP_21_BZ_XIX_ESP_21_XIX_E3V_EVCANFD: start 8, 4 bit, little-endian, data-type-policy=OVERRIDE, i-signal-type=PRIMITIVE, base-type=BT_ESP_21_BZ, compu {phys=raw for raw 0..15}, range phys 0..15, raw 0..15, transfer-property=PENDING
          signal BR_Eingriffsmoment_XIX_ESP_21_XIX_E3V_EVCANFD: start 12, 10 bit, little-endian, data-type-policy=OVERRIDE, i-signal-type=PRIMITIVE, init-value=1022, base-type=BT_BR_Eingriffsmoment, invalid-value=Invalid_BR_Eingriffsmoment_XIX_ESP_21_XIX_E3V_EVCANFD:1023, compu {phys=raw-509 for raw 0..1018, 1022=Cx3fe_Init (CM_BR_Eingriffsmoment_Cx3fe_Init), 1023=Cx3ff_Fehler (CM_BR_Eingriffsmoment_Cx3ff_Fehler)}, range phys -509..509, raw 0..1023, transfer-property=PENDING  # Einheitenloser Wert! Faktor in MO_Faktor_Momente_02 in Motor_Code_01 beachten! Schnelle reduzierende (ASR) oder erhöhende (MSR) Momentanforderung an den Motor.
          signal ESP_PLA_Bremseingriff_XIX_ESP_21_XIX_E3V_EVCANFD: start 22, 1 bit, little-endian, data-type-policy=OVERRIDE, i-signal-type=PRIMITIVE, init-value=0, base-type=BT_ESP_PLA_Bremseingriff, compu {0=Cx0_inaktiv (CM_ESP_PLA_Bremseingriff_Cx0_inaktiv), 1=Cx1_aktiv (CM_ESP_PLA_Bremseingriff_Cx1_aktiv)}, range raw 0..1, transfer-property=PENDING  # Signalisierung des aktiven Bremseingriffes des ESP aufgrund einer Bremsanforderung vom PLA.
          signal ESP_Diagnose_XIX_ESP_21_XIX_E3V_EVCANFD: start 23, 1 bit, little-endian, data-type-policy=OVERRIDE, i-signal-type=PRIMITIVE, init-value=0, base-type=BT_ESP_Diagnose, compu {0=Cx0_ESP_nicht_in_Diagnose (CM_ESP_Diagnose_Cx0_ESP_nicht_in_Diagnose), 1=Cx1_ESP_in_Diagnose (CM_ESP_Diagnose_Cx1_ESP_in_Diagnose)}, range raw 0..1, transfer-property=PENDING  # MLB: Nach Diagnoseende wird ein SW-Reset ausgelöst welcher einen Kommunikatiosausfall für max. 150ms verursacht. Dies ist bei SG mit verschärfter Timeoutüberwachung (nicht nach Konzern-LH) zu beachten. MQB: Weiterführende Informationen im Lastenheft spezifiziert und in der entsprechenden Fachabteilung zu erfragen.
          signal ESC_Reku_Freigabe_XIX_ESP_21_XIX_E3V_EVCANFD: start 24, 1 bit, little-endian, data-type-policy=OVERRIDE, i-signal-type=PRIMITIVE, init-value=0, base-type=BT_ESC_Reku_Freigabe, compu {0=Cx0_keine_Freigabe_der_Rekuperation (CM_ESC_Reku_Freigabe_Cx0_keine_Freigabe_der_Rekuperation), 1=Cx1_Freigabe_der_Rekuperation (CM_ESC_Reku_Freigabe_Cx1_Freigabe_der_Rekuperation)}, range raw 0..1, transfer-property=PENDING  # Mit diesem Bit wird die Rekuperation im Motorsteuergerät erlaubt. Bei Ausfall ESC wird Rekuperation nicht freigegeben. MQB/MQB2020: Wird nur von einem blendfähigen ESC unterstützt, wie es in mHEV und pHEV Fahrzeugen eingesetzt wird.
          signal ESC_v_Signal_Qualifier_High_Low_XIX_ESP_21_XIX_E3V_EVCANFD: start 25, 3 bit, little-endian, data-type-policy=OVERRIDE, i-signal-type=PRIMITIVE, init-value=6, base-type=BT_ESC_v_Signal_Qualifier_High_Low, invalid-value=Invalid_ESC_v_Signal_Qualifier_High_Low_XIX_ESP_21_XIX_E3V_EVCANFD:7, compu {0=Cx0_Gueteschwelle_kleiner_1kmh (CM_ESC_v_Signal_Qualifier_High_Low_Cx0_Gueteschwelle_kleiner_1kmh), 1=Cx1_Gueteschwelle_kleiner_3kmh (CM_ESC_v_Signal_Qualifier_High_Low_Cx1_Gueteschwelle_kleiner_3kmh), 2=Cx2_Gueteschwelle_kleiner_5kmh (CM_ESC_v_Signal_Qualifier_High_Low_Cx2_Gueteschwelle_kleiner_5kmh), 3=Cx3_Gueteschwelle_kleiner_10kmh (CM_ESC_v_Signal_Qualifier_High_Low_Cx3_Gueteschwelle_kleiner_10kmh), 4=Cx4_Gueteschwelle_kleiner_20kmh (CM_ESC_v_Signal_Qualifier_High_Low_Cx4_Gueteschwelle_kleiner_20kmh), 5=Cx5_Gueteschwelle_groessergleich_20kmh (CM_ESC_v_Signal_Qualifier_High_Low_Cx5_Gueteschwelle_groessergleich_20kmh), 6=Cx6_Init (CM_ESC_v_Signal_Qualifier_High_Low_Cx6_Init), 7=Cx7_Fehler (CM_ESC_v_Signal_Qualifier_High_Low_Cx7_Fehler)}, range raw 0..7, transfer-property=PENDING  # Das Qualifizerungssignal ESC_v_Signal_Qualifier_High_Low gibt eine Information über die Güte der vom Bremsregelsystem ausgegebenen Geschwindigkeitsinformation "mittlere Geschwindigkeit", wobei Vertrauensbereiche für das ausgegebene Geschwindigkeitssignal angezeigt werden. Angezeigt werden über das Qualifizerungssignal sowohl Einschränkungen in der Güte des Signals durch funktionale Einschränkungen (Radschlupf an Einzelrädern, z.B. während aktiver ESC-Regelungen) als auch fehlerbedingte Abweichungen der Geschwindigkeitsinforma-tion (z.B. durch fehlerhafte Raddrehzahlsensorsignale).
          signal ESP_Vorsteuerung_XIX_ESP_21_XIX_E3V_EVCANFD: start 28, 1 bit, little-endian, data-type-policy=OVERRIDE, i-signal-type=PRIMITIVE, init-value=0, base-type=BT_ESP_Vorsteuerung, compu {0=Cx0_keine_Vorsteuerung_aktiv (CM_ESP_Vorsteuerung_Cx0_keine_Vorsteuerung_aktiv), 1=Cx1_Vorsteuerung_aktiv (CM_ESP_Vorsteuerung_Cx1_Vorsteuerung_aktiv)}, range raw 0..1, transfer-property=PENDING  # zur Unterscheidung zwischen ESP-Vorsteuermaßnahmen und ESP-Regeleingriffen
          signal ESP_AWV3_Brems_aktiv_XIX_ESP_21_XIX_E3V_EVCANFD: start 29, 1 bit, little-endian, data-type-policy=OVERRIDE, i-signal-type=PRIMITIVE, init-value=0, base-type=BT_ESP_AWV3_Brems_aktiv, compu {0=Cx0_inaktiv (CM_ESP_AWV3_Brems_aktiv_Cx0_inaktiv), 1=Cx1_aktiv (CM_ESP_AWV3_Brems_aktiv_Cx1_aktiv)}, range raw 0..1, transfer-property=PENDING  # Teil-, Ziel- oder Notbremsung wird im ESP für AWV3 umgesetzt (das MSG nutzt diese Info für den Abwurf der GRA-Regelung).
          signal OBD_Schlechtweg_XIX_ESP_21_XIX_E3V_EVCANFD: start 30, 1 bit, little-endian, data-type-policy=OVERRIDE, i-signal-type=PRIMITIVE, init-value=0, base-type=BT_OBD_Schlechtweg, compu {0=Cx0_kein_Schlechtweg_erkannt (CM_OBD_Schlechtweg_Cx0_kein_Schlechtweg_erkannt), 1=Cx1_Schlechtweg_erkannt (CM_OBD_Schlechtweg_Cx1_Schlechtweg_erkannt)}, range raw 0..1, transfer-property=PENDING  # Für Ausblendung der Zündaussetzererkennung im Motorsteuergerät (Otto). Bit wird gesetzt, wenn Rad-Drehbeschleunigung im ESP > Grenzwert ist. Vorteil gegenüber Radgeschwindigkeiten, dass ESP alle 2 ms dynamisch die Rad-Drehbeschleunigung errechnet und dem Motor eine bessere Güte liefert. Bit darf nur vom Motor ausgewertet werden. Es gilt Signalspezifikation OBD_Schlechtweg V2.0 Im MQB wird dieses Signal nicht unterstützt!
          signal OBD_QBit_Schlechtweg_XIX_ESP_21_XIX_E3V_EVCANFD: start 31, 1 bit, little-endian, data-type-policy=OVERRIDE, i-signal-type=PRIMITIVE, init-value=1, base-type=BT_OBD_QBit_Schlechtweg, compu {0=Cx0_gueltiger_Wert (CM_OBD_QBit_Schlechtweg_Cx0_gueltiger_Wert), 1=Cx1_Ersatz_Init_oder_Fehlerwert (CM_OBD_QBit_Schlechtweg_Cx1_Ersatz_Init_oder_Fehlerwert)}, range raw 0..1, transfer-property=PENDING
          signal ESP_v_Signal_XIX_ESP_21_XIX_E3V_EVCANFD: start 32, 16 bit, little-endian, data-type-policy=OVERRIDE, i-signal-type=PRIMITIVE, init-value=65534, base-type=BT_ESP_v_Signal, invalid-value=Invalid_ESP_v_Signal_XIX_ESP_21_XIX_E3V_EVCANFD:65535, compu {phys=raw*0.01 for raw 0..65532, 65533=Cxfffd_Unterspannung (CM_ESP_v_Signal_Cxfffd_Unterspannung), 65534=Cxfffe_Init (CM_ESP_v_Signal_Cxfffe_Init), 65535=Cxffff_Fehler (CM_ESP_v_Signal_Cxffff_Fehler); unit Unit_KiloMeterPerHour}, range phys 0..655.32 Unit_KiloMeterPerHour, raw 0..65535, unit=Unit_KiloMeterPerHour, transfer-property=PENDING, to Klima(timeout 0.5 s)  # Geschwindigkeitssignal vom ABS/ASR oder ESP. Mittelwert der angetriebenen Räder. Bei MSR oder ABS Eingriffen wird die ABS-Referenzgeschwindigkeit für >= 200ms eingespiegelt (Zeit wird mit Aktiv-Flanke der Funktionsbits getriggert) MQB: Bei Frontantrieb und gesteuertem Allrad (Haldex) Mittelwert der Vorderräder.
          signal ASR_Tastung_passiv_XIX_ESP_21_XIX_E3V_EVCANFD: start 48, 1 bit, little-endian, data-type-policy=OVERRIDE, i-signal-type=PRIMITIVE, init-value=0, base-type=BT_ASR_Tastung_passiv, compu {0=Cx0_ASR_aktiviert (CM_ASR_Tastung_passiv_Cx0_ASR_aktiviert), 1=Cx1_ASR_passiv_getastet_oder_Schwellen_geaendert (CM_ASR_Tastung_passiv_Cx1_ASR_passiv_getastet_oder_Schwellen_geaendert)}, range raw 0..1, transfer-property=PENDING  # ASR deaktiviert oder Schwellen geändert (projektabhängig) Weiterführende Informationen im Lastenheft spezifiziert und in der entsprechenden Fachabteilung zu erfragen.
          signal ESP_Tastung_passiv_XIX_ESP_21_XIX_E3V_EVCANFD: start 49, 1 bit, little-endian, data-type-policy=OVERRIDE, i-signal-type=PRIMITIVE, init-value=0, base-type=BT_ESP_Tastung_passiv, compu {0=Cx0_ESP_aktiviert (CM_ESP_Tastung_passiv_Cx0_ESP_aktiviert), 1=Cx1_ESP_passiv_getastet_oder_Schwellen_geaendert (CM_ESP_Tastung_passiv_Cx1_ESP_passiv_getastet_oder_Schwellen_geaendert)}, range raw 0..1, transfer-property=PENDING  # ESP deaktiviert oder Schwellen geändert (projektabhängig) Weiterführende Informationen im Lastenheft spezifiziert und in der entsprechenden Fachabteilung zu erfragen.
          signal ESP_Systemstatus_XIX_ESP_21_XIX_E3V_EVCANFD: start 50, 1 bit, little-endian, data-type-policy=OVERRIDE, i-signal-type=PRIMITIVE, init-value=0, base-type=BT_ESP_Systemstatus, compu {0=Cx0_iO (CM_ESP_Systemstatus_Cx0_iO), 1=Cx1_Fehler (CM_ESP_Systemstatus_Cx1_Fehler)}, range raw 0..1, transfer-property=PENDING  # Fehler steht für Stillegung ESP mit Fehlereintrag. MLB: Flag wird bei Unterspannung im Stand bis einmalig 6km/h (AU48x) oder 10 km/h (AU641, AU57x) überschritten nicht gesetzt (Ausblendung Startvorgang) Im AU64x, AU57x gilt ESP D4 Funktionsanforderungen (DOORS-Modul)
          signal ASR_Schalteingriff_XIX_ESP_21_XIX_E3V_EVCANFD: start 51, 2 bit, little-endian, data-type-policy=OVERRIDE, i-signal-type=PRIMITIVE, init-value=0, base-type=BT_ASR_Schalteingriff, compu {0=Cx0_keine_Anforderung (CM_ASR_Schalteingriff_Cx0_keine_Anforderung), 1=Cx1_ASR_Schaltkennfeld (CM_ASR_Schalteingriff_Cx1_ASR_Schaltkennfeld), 2=Cx2_Rueckschaltung (CM_ASR_Schalteingriff_Cx2_Rueckschaltung), 3=Cx3_Schaltverbot (CM_ASR_Schalteingriff_Cx3_Schaltverbot)}, range raw 0..3, transfer-property=PENDING  # Wunsch an das Getriebe während einer ASR Regelung MLB: Es wird nur 0x0 und 0x1 genutzt
          signal ESP_Haltebestaetigung_XIX_ESP_21_XIX_E3V_EVCANFD: start 53, 1 bit, little-endian, data-type-policy=OVERRIDE, i-signal-type=PRIMITIVE, init-value=0, base-type=BT_ESP_Haltebestaetigung, compu {0=Cx0_kein_sicheres_Halten (CM_ESP_Haltebestaetigung_Cx0_kein_sicheres_Halten), 1=Cx1_sicheres_Halten (CM_ESP_Haltebestaetigung_Cx1_sicheres_Halten)}, range raw 0..1, transfer-property=PENDING  # Rückmeldung vom ESP-SG, dass das Fahrzeug aufgrund einer externen Bremsanforderung (z. B. ACC, PLA, ANB, o. ä.) abgebremst wurde und im Stillstand gehalten wird.
          signal ESP_MKB_Abbruch_Geschw_XIX_ESP_21_XIX_E3V_EVCANFD: start 54, 1 bit, little-endian, data-type-policy=OVERRIDE, i-signal-type=PRIMITIVE, init-value=0, base-type=BT_ESP_MKB_Abbruch_Geschw, compu {0=Cx0_MKB_nicht_beendet_wg_v_Schwelle (CM_ESP_MKB_Abbruch_Geschw_Cx0_MKB_nicht_beendet_wg_v_Schwelle), 1=Cx1_MKB_beendet_wg_v_Schwelle (CM_ESP_MKB_Abbruch_Geschw_Cx1_MKB_beendet_wg_v_Schwelle)}, range raw 0..1, transfer-property=PENDING  # Im Falle einer Multikollisionsbremsung teilt das ESP den Abbruch der MKB aufgrund der unteren Geschwindigkeitsschwelle mit.
          signal ESP_QBit_v_Signal_XIX_ESP_21_XIX_E3V_EVCANFD: start 55, 1 bit, little-endian, data-type-policy=OVERRIDE, i-signal-type=PRIMITIVE, init-value=1, base-type=BT_ESP_QBit_v_Signal, compu {0=Cx0_gueltiger_Wert (CM_ESP_QBit_v_Signal_Cx0_gueltiger_Wert), 1=Cx1_Ersatz_Init_oder_Fehlerwert (CM_ESP_QBit_v_Signal_Cx1_Ersatz_Init_oder_Fehlerwert)}, range raw 0..1, transfer-property=PENDING, to Klima(timeout 0.5 s)  # Geschwindigkeit wird vom ABS/ASR oder ESP aus Ersatzwerten errechnet, wenn Bit gesetzt ist. Güte des Signals ist verändert.
          signal ABS_Bremsung_XIX_ESP_21_XIX_E3V_EVCANFD: start 56, 1 bit, little-endian, data-type-policy=OVERRIDE, i-signal-type=PRIMITIVE, init-value=0, base-type=BT_ABS_Bremsung, compu {0=Cx0_keine_ABS_Regelung (CM_ABS_Bremsung_Cx0_keine_ABS_Regelung), 1=Cx1_ABS_Regelung_aktiv (CM_ABS_Bremsung_Cx1_ABS_Regelung_aktiv)}, range raw 0..1, transfer-property=PENDING  # Antiblockiersystem, Bit zeigt auch Druckabbau an (z.B. ESP hat zuviel Druck aufgebaut oder ungebremste Regelung auf Bahnübergang) Weiterführende Informationen im Lastenheft spezifiziert und in der entsprechenden Fachabteilung zu erfragen.
          signal ASR_Anf_XIX_ESP_21_XIX_E3V_EVCANFD: start 57, 1 bit, little-endian, data-type-policy=OVERRIDE, i-signal-type=PRIMITIVE, init-value=0, base-type=BT_ASR_Anf, compu {0=Cx0_keine_Anforderung (CM_ASR_Anf_Cx0_keine_Anforderung), 1=Cx1_ASR_Anforderung (CM_ASR_Anf_Cx1_ASR_Anforderung)}, range raw 0..1, transfer-property=PENDING  # MLB: Die Momentenanforderung "ASR_MSR_Moment_schnell" und "ASR_Moment_langsam" sind auszuführen MQB: Die Momentenanforderung "BR_Eingriffsmoment" ist auszuführen
          signal MSR_Anf_XIX_ESP_21_XIX_E3V_EVCANFD: start 58, 1 bit, little-endian, data-type-policy=OVERRIDE, i-signal-type=PRIMITIVE, init-value=0, base-type=BT_MSR_Anf, compu {0=Cx0_keine_Anfoderung (CM_MSR_Anf_Cx0_keine_Anfoderung) (keine Anfoderung), 1=Cx1_MSR_Anforderung (CM_MSR_Anf_Cx1_MSR_Anforderung) (MSR-Anforderung)}, range raw 0..1, transfer-property=PENDING  # MLB: Die Momentenanforderung "ASR_MSR_Moment_schnell" ist auszuführen. MQB: Die Momentenanforderung "BR_Eingriffsmoment" ist auszuführen
          signal EBV_Eingriff_XIX_ESP_21_XIX_E3V_EVCANFD: start 59, 1 bit, little-endian, data-type-policy=OVERRIDE, i-signal-type=PRIMITIVE, init-value=0, base-type=BT_EBV_Eingriff, compu {0=Cx0_kein_EBV_Eingriff (CM_EBV_Eingriff_Cx0_kein_EBV_Eingriff), 1=Cx1_EBV_Eingriff (CM_EBV_Eingriff_Cx1_EBV_Eingriff)}, range raw 0..1, transfer-property=PENDING  # Elektronische Bremskraftverteilung, aktueller Eingriff (Druckhalten, Druckabbau) Im MLB: kein ABS / ESP-Eingriff ???
          signal EDS_Eingriff_XIX_ESP_21_XIX_E3V_EVCANFD: start 60, 1 bit, little-endian, data-type-policy=OVERRIDE, i-signal-type=PRIMITIVE, init-value=0, base-type=BT_EDS_Eingriff, compu {0=Cx0_kein_EDS_Eingriff (CM_EDS_Eingriff_Cx0_kein_EDS_Eingriff), 1=Cx1_EDS_Eingriff (CM_EDS_Eingriff_Cx1_EDS_Eingriff)}, range raw 0..1, transfer-property=PENDING  # Elektronische Differentialsperre
          signal ESP_Eingriff_XIX_ESP_21_XIX_E3V_EVCANFD: start 61, 1 bit, little-endian, data-type-policy=OVERRIDE, i-signal-type=PRIMITIVE, init-value=0, base-type=BT_ESP_Eingriff, compu {0=Cx0_kein_ESP_Eingriff (CM_ESP_Eingriff_Cx0_kein_ESP_Eingriff), 1=Cx1_ESP_Eingriff_aktiv (CM_ESP_Eingriff_Cx1_ESP_Eingriff_aktiv)}, range raw 0..1, transfer-property=PENDING  # Eingriff des Fahrdynamikreglers
          signal ESP_ASP_XIX_ESP_21_XIX_E3V_EVCANFD: start 62, 1 bit, little-endian, data-type-policy=OVERRIDE, i-signal-type=PRIMITIVE, init-value=0, base-type=BT_ESP_ASP, compu {0=Cx0_inaktiv (CM_ESP_ASP_Cx0_inaktiv), 1=Cx1_aktiv (CM_ESP_ASP_Cx1_aktiv)}, range raw 0..1, transfer-property=PENDING  # MLB: Anhaenger-Stabilisierungs-Programm MQB: Gespannstabilisierung
          signal ESP_Anhaltevorgang_ACC_aktiv_XIX_ESP_21_XIX_E3V_EVCANFD: start 63, 1 bit, little-endian, data-type-policy=OVERRIDE, i-signal-type=PRIMITIVE, init-value=0, base-type=BT_ESP_Anhaltevorgang_ACC_aktiv, compu {0=Cx0_inaktiv (CM_ESP_Anhaltevorgang_ACC_aktiv_Cx0_inaktiv), 1=Cx1_aktiv (CM_ESP_Anhaltevorgang_ACC_aktiv_Cx1_aktiv)}, range raw 0..1, transfer-property=PENDING  # Zeigt an, ob ACC-Anhaltevorgang aktiv
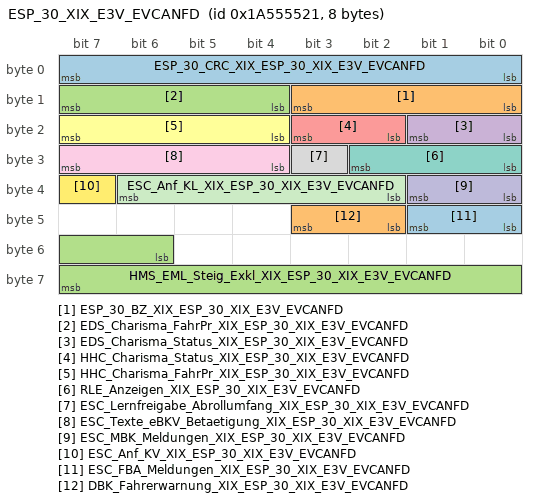
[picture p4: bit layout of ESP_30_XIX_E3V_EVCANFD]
      frame ESP_30_XIX_E3V_EVCANFD: id 0x1A555521, to Klima, frame-length=8, can-addressing-mode=EXTENDED, can-frame-rx-behavior=CAN-FD, can-frame-tx-behavior=CAN-FD
        pdu ESP_30_XIX_E3V_EVCANFD: length=8, minimum-delay=0.05, transmission-mode-true-timing={cyclic-timing={time-offset=0, time-period=1.0}, event-controlled-timing={number-of-repetitions=0, repetition-period=0.0}}, unused-bit-pattern=0
          signal ESP_30_CRC_XIX_ESP_30_XIX_E3V_EVCANFD: start 0, 8 bit, little-endian, data-type-policy=OVERRIDE, i-signal-type=PRIMITIVE, base-type=BT_ESP_30_CRC, compu {phys=raw for raw 0..255}, range phys 0..255, raw 0..255, transfer-property=PENDING  # Für MLB: Berechnung siehe Lastenheft "Kommunikationsabsicherung für FlexRay und CAN" Ab MQB und MLBevo: Berechnung siehe Lastenheft "End-to-End Kommunikationsabsicherung" Endwerte siehe Begleitdokument "S-PDU Kennungsfolgen"
          signal ESP_30_BZ_XIX_ESP_30_XIX_E3V_EVCANFD: start 8, 4 bit, little-endian, data-type-policy=OVERRIDE, i-signal-type=PRIMITIVE, base-type=BT_ESP_30_BZ, compu {phys=raw for raw 0..15}, range phys 0..15, raw 0..15, transfer-property=PENDING  # 4bit Botschaftszähler, wird mit jeder Sendebotschaft inkrementiert
          signal EDS_Charisma_FahrPr_XIX_ESP_30_XIX_E3V_EVCANFD: start 12, 4 bit, little-endian, data-type-policy=OVERRIDE, i-signal-type=PRIMITIVE, init-value=0, base-type=BT_EDS_Charisma_FahrPr, compu {0=Cx0_keine_Funktion (CM_EDS_Charisma_FahrPr_Cx0_keine_Funktion), 1=Cx1_Programm_1 (CM_EDS_Charisma_FahrPr_Cx1_Programm_1), 2=Cx2_Programm_2 (CM_EDS_Charisma_FahrPr_Cx2_Programm_2), 3=Cx3_Programm_3 (CM_EDS_Charisma_FahrPr_Cx3_Programm_3), 4=Cx4_Programm_4 (CM_EDS_Charisma_FahrPr_Cx4_Programm_4), 5=Cx5_Programm_5 (CM_EDS_Charisma_FahrPr_Cx5_Programm_5), 6=Cx6_Programm_6 (CM_EDS_Charisma_FahrPr_Cx6_Programm_6), 7=Cx7_Programm_7 (CM_EDS_Charisma_FahrPr_Cx7_Programm_7), 8=Cx8_Programm_8 (CM_EDS_Charisma_FahrPr_Cx8_Programm_8), 9=Cx9_Programm_9 (CM_EDS_Charisma_FahrPr_Cx9_Programm_9), 10=Cxa_Programm_10 (CM_EDS_Charisma_FahrPr_Cxa_Programm_10), 11=Cxb_Programm_11 (CM_EDS_Charisma_FahrPr_Cxb_Programm_11), 12=Cxc_Programm_12 (CM_EDS_Charisma_FahrPr_Cxc_Programm_12), 13=Cxd_Programm_13 (CM_EDS_Charisma_FahrPr_Cxd_Programm_13), 14=Cxe_Programm_14 (CM_EDS_Charisma_FahrPr_Cxe_Programm_14), 15=Cxf_Programm_15 (CM_EDS_Charisma_FahrPr_Cxf_Programm_15)}, range raw 0..15, transfer-property=TRIGGERED-ON-CHANGE-WITHOUT-REPETITION  # Aktuelles Fahrprogramm des Charisma-Teilnehmers Elektronische Differentialsperre EDS
          signal EDS_Charisma_Status_XIX_ESP_30_XIX_E3V_EVCANFD: start 16, 2 bit, little-endian, data-type-policy=OVERRIDE, i-signal-type=PRIMITIVE, init-value=0, base-type=BT_EDS_Charisma_Status, compu {0=Cx0_Init (CM_EDS_Charisma_Status_Cx0_Init), 1=Cx1_verfuegbar (CM_EDS_Charisma_Status_Cx1_verfuegbar), 2=Cx2_nicht_verfuegbar (CM_EDS_Charisma_Status_Cx2_nicht_verfuegbar), 3=Cx3_asynchron_durch_Fahrerwunsch (CM_EDS_Charisma_Status_Cx3_asynchron_durch_Fahrerwunsch)}, range raw 0..3, transfer-property=TRIGGERED-ON-CHANGE-WITHOUT-REPETITION  # Systemstatus des Charismateilnehmers Elektronische Differentialsperre EDS
          signal HHC_Charisma_Status_XIX_ESP_30_XIX_E3V_EVCANFD: start 18, 2 bit, little-endian, data-type-policy=OVERRIDE, i-signal-type=PRIMITIVE, init-value=0, base-type=BT_HHC_Charisma_Status, compu {0=Cx0_Init (CM_HHC_Charisma_Status_Cx0_Init), 1=Cx1_verfuegbar (CM_HHC_Charisma_Status_Cx1_verfuegbar), 2=Cx2_nicht_verfuegbar (CM_HHC_Charisma_Status_Cx2_nicht_verfuegbar), 3=Cx3_asynchron_durch_Fahrerwunsch (CM_HHC_Charisma_Status_Cx3_asynchron_durch_Fahrerwunsch)}, range raw 0..3, transfer-property=TRIGGERED-ON-CHANGE-WITHOUT-REPETITION  # Systemstatus des Charismateilnehmers Berganfahrassistent HHC
          signal HHC_Charisma_FahrPr_XIX_ESP_30_XIX_E3V_EVCANFD: start 20, 4 bit, little-endian, data-type-policy=OVERRIDE, i-signal-type=PRIMITIVE, init-value=0, base-type=BT_HHC_Charisma_FahrPr, compu {0=Cx0_keine_Funktion (CM_HHC_Charisma_FahrPr_Cx0_keine_Funktion), 1=Cx1_Programm_1 (CM_HHC_Charisma_FahrPr_Cx1_Programm_1), 2=Cx2_Programm_2 (CM_HHC_Charisma_FahrPr_Cx2_Programm_2), 3=Cx3_Programm_3 (CM_HHC_Charisma_FahrPr_Cx3_Programm_3), 4=Cx4_Programm_4 (CM_HHC_Charisma_FahrPr_Cx4_Programm_4), 5=Cx5_Programm_5 (CM_HHC_Charisma_FahrPr_Cx5_Programm_5), 6=Cx6_Programm_6 (CM_HHC_Charisma_FahrPr_Cx6_Programm_6), 7=Cx7_Programm_7 (CM_HHC_Charisma_FahrPr_Cx7_Programm_7), 8=Cx8_Programm_8 (CM_HHC_Charisma_FahrPr_Cx8_Programm_8), 9=Cx9_Programm_9 (CM_HHC_Charisma_FahrPr_Cx9_Programm_9), 10=Cxa_Programm_10 (CM_HHC_Charisma_FahrPr_Cxa_Programm_10), 11=Cxb_Programm_11 (CM_HHC_Charisma_FahrPr_Cxb_Programm_11), 12=Cxc_Programm_12 (CM_HHC_Charisma_FahrPr_Cxc_Programm_12), 13=Cxd_Programm_13 (CM_HHC_Charisma_FahrPr_Cxd_Programm_13), 14=Cxe_Programm_14 (CM_HHC_Charisma_FahrPr_Cxe_Programm_14), 15=Cxf_Programm_15 (CM_HHC_Charisma_FahrPr_Cxf_Programm_15)}, range raw 0..15, transfer-property=TRIGGERED-ON-CHANGE-WITHOUT-REPETITION  # Aktuelles Fahrprogramm des Charisma-Teilnehmers Berganfahrassistent HHC
          signal RLE_Anzeigen_XIX_ESP_30_XIX_E3V_EVCANFD: start 24, 3 bit, little-endian, data-type-policy=OVERRIDE, i-signal-type=PRIMITIVE, init-value=0, base-type=BT_RLE_Anzeigen, compu {0=Cx0_keine_Anzeige (CM_RLE_Anzeigen_Cx0_keine_Anzeige), 1=Cx1_Rad_lose_allgemein (CM_RLE_Anzeigen_Cx1_Rad_lose_allgemein), 2=Cx2_Rad_VL_lose (CM_RLE_Anzeigen_Cx2_Rad_VL_lose), 3=Cx3_Rad_VR_lose (CM_RLE_Anzeigen_Cx3_Rad_VR_lose), 4=Cx4_Rad_HL_lose (CM_RLE_Anzeigen_Cx4_Rad_HL_lose), 5=Cx5_Rad_HR_lose (CM_RLE_Anzeigen_Cx5_Rad_HR_lose), 6=Cx6_RLE_Pruefphase (CM_RLE_Anzeigen_Cx6_RLE_Pruefphase), 7=Cx7_RLE_Systemstoerung (CM_RLE_Anzeigen_Cx7_RLE_Systemstoerung)}, range raw 0..7, transfer-property=PENDING  # Anzeigen für die Radlöseerkennung
          signal ESC_Lernfreigabe_Abrollumfang_XIX_ESP_30_XIX_E3V_EVCANFD: start 27, 1 bit, little-endian, data-type-policy=OVERRIDE, i-signal-type=PRIMITIVE, init-value=0, base-type=BT_ESC_Lernfreigabe_Abrollumfang, compu {0=Cx0_keine_Lernfreigabe (CM_ESC_Lernfreigabe_Abrollumfang_Cx0_keine_Lernfreigabe), 1=Cx1_Lernfreigabe (CM_ESC_Lernfreigabe_Abrollumfang_Cx1_Lernfreigabe)}, range raw 0..1, transfer-property=TRIGGERED-ON-CHANGE-WITHOUT-REPETITION  # Meldet einen Fahrdynamikzustand, der es zulässt, dass der Abrollumfang der Räder genauer errechnet werden darf. Die Verwendung des Signals ist ausschließlich für die MQB-Plattform zugelassen.
          signal ESC_Texte_eBKV_Betaetigung_XIX_ESP_30_XIX_E3V_EVCANFD: start 28, 4 bit, little-endian, data-type-policy=OVERRIDE, i-signal-type=PRIMITIVE, init-value=0, base-type=BT_ESC_Texte_eBKV_Betaetigung, compu {0=Cx0_keine_Anzeige (CM_ESC_Texte_eBKV_Betaetigung_Cx0_keine_Anzeige), 1=Cx1_Halten_ueber_Schaltwippen_aktiv (CM_ESC_Texte_eBKV_Betaetigung_Cx1_Halten_ueber_Schaltwippen_aktiv), 2=Cx2_Beide_Schaltwippen_betaetigen (CM_ESC_Texte_eBKV_Betaetigung_Cx2_Beide_Schaltwippen_betaetigen), 3=Cx3_Abbr_Halten_ueber_Schaltwippen (CM_ESC_Texte_eBKV_Betaetigung_Cx3_Abbr_Halten_ueber_Schaltwippen), 4=Cx4_Bremspedal_betaetigen (CM_ESC_Texte_eBKV_Betaetigung_Cx4_Bremspedal_betaetigen), 5=Cx5_Fahrpedal_loesen_Bremse_treten (CM_ESC_Texte_eBKV_Betaetigung_Cx5_Fahrpedal_loesen_Bremse_treten)}, range raw 0..5, transfer-property=TRIGGERED-ON-CHANGE-WITHOUT-REPETITION  # Anweisungen an den Fahrer für die Betätigung der Bremse über den eBKV unter Verwendung der Schaltwippen am Lenkrad.
          signal ESC_MBK_Meldungen_XIX_ESP_30_XIX_E3V_EVCANFD: start 32, 2 bit, little-endian, data-type-policy=OVERRIDE, i-signal-type=PRIMITIVE, init-value=0, base-type=BT_ESC_MBK_Meldungen, compu {0=Cx0_kein_Text (CM_ESC_MBK_Meldungen_Cx0_kein_Text), 1=Cx1_MBK_Hinweis_aktiv (CM_ESC_MBK_Meldungen_Cx1_MBK_Hinweis_aktiv), 2=Cx2_MBK_Eskalation1_aktiv (CM_ESC_MBK_Meldungen_Cx2_MBK_Eskalation1_aktiv)}, range raw 0..2, transfer-property=TRIGGERED-ON-CHANGE-WITHOUT-REPETITION  # Das Signal steuert die Schaltempfehlung im Kombi, die bei Bergabfahrt den Fahrer darauf hinweist in eine geeignete Fahrstufe zu schalten um eine Rekuperation zu ermöglichen.
          signal ESC_Anf_KL_XIX_ESP_30_XIX_E3V_EVCANFD: start 34, 5 bit, little-endian, data-type-policy=OVERRIDE, i-signal-type=PRIMITIVE, init-value=0, base-type=BT_ESC_Anf_KL, compu {phys=raw*3.22580645 for raw 0..31; unit Unit_PerCent}, range phys 0..99.99999995 Unit_PerCent, raw 0..31, unit=Unit_PerCent, transfer-property=PENDING  # Nachricht an Motor- bzw. Antriebssteuergerät zur Festlegung der Motorluefterdrehzahl Angabe in Prozent der Maximaldrehzahl
          signal ESC_Anf_KV_XIX_ESP_30_XIX_E3V_EVCANFD: start 39, 1 bit, little-endian, data-type-policy=OVERRIDE, i-signal-type=PRIMITIVE, init-value=0, base-type=BT_ESC_Anf_KV, compu {0=Cx0_kein_Oeffnen (CM_ESC_Anf_KV_Cx0_kein_Oeffnen), 1=Cx1_Oeffnen (CM_ESC_Anf_KV_Cx1_Oeffnen)}, range raw 0..1, transfer-property=PENDING, to Klima(timeout 5 s)  # Nachricht an Motor bzw. Antriebssteuergerät zum Öffnen der Kühlerjalousie.
          signal ESC_FBA_Meldungen_XIX_ESP_30_XIX_E3V_EVCANFD: start 40, 2 bit, little-endian, data-type-policy=OVERRIDE, i-signal-type=PRIMITIVE, init-value=0, base-type=BT_ESC_FBA_Meldungen, compu {0=Cx0_kein_Text (CM_ESC_FBA_Meldungen_Cx0_kein_Text), 1=Cx1_FBA_Warnung_aktiv_MT (CM_ESC_FBA_Meldungen_Cx1_FBA_Warnung_aktiv_MT), 2=Cx2_FBA_Warnung_aktiv_AT (CM_ESC_FBA_Meldungen_Cx2_FBA_Warnung_aktiv_AT)}, range raw 0..2, transfer-property=TRIGGERED-ON-CHANGE-WITHOUT-REPETITION  # Hinweis an den Fahrer über das Kombi, bei dauerhafter Bergabfahrt einen Gang einzulegen um die Motorbremse zu nutzen. Unterscheidung zwischen: Handschalterfahrzeugen (FBA_Warnung_aktiv_MT) Automatikfahrzeugen (FBA_Warnung_aktiv_AT)
          signal DBK_Fahrerwarnung_XIX_ESP_30_XIX_E3V_EVCANFD: start 42, 2 bit, little-endian, data-type-policy=OVERRIDE, i-signal-type=PRIMITIVE, init-value=0, base-type=BT_DBK_Fahrerwarnung, compu {0=Cx0_kein_Anfordern (CM_DBK_Fahrerwarnung_Cx0_kein_Anfordern), 1=Cx1_Warnung_Aufforderung_Anhalten (CM_DBK_Fahrerwarnung_Cx1_Warnung_Aufforderung_Anhalten), 2=Cx2_Warnung_Aufforderung_Werkstatt (CM_DBK_Fahrerwarnung_Cx2_Warnung_Aufforderung_Werkstatt), 3=Cx3_nicht_belegt (CM_DBK_Fahrerwarnung_Cx3_nicht_belegt)}, range raw 0..3, transfer-property=PENDING  # Warnt den Fahrer bei erkannter Dampfblase in der Bremsflüssigkeit und fordert ihn zum Anhalten sowie Werkstattbesuch auf (2 Bit): 0: kein Anfordern (Initwert) 1: Warnereignis 1 - fordert Warnlampe, Warnmeldung (Aufforderung Anhalten) und Warnton sowie Fehlerspeichereintrag an 2: Warnereignis 2 - fordert Warnlampe, Warnmeldung (Aufforderung Werkstattbesuch) und Warnton an 3: nicht belegt
          signal HMS_EML_Steig_Exkl_XIX_ESP_30_XIX_E3V_EVCANFD: start 54, 10 bit, little-endian, data-type-policy=OVERRIDE, i-signal-type=PRIMITIVE, init-value=0, base-type=BT_HMS_EML_Steig_Exkl, invalid-value=Invalid_HMS_EML_Steig_Exkl_XIX_ESP_30_XIX_E3V_EVCANFD:1023, compu {0=Cx0_Init (CM_HMS_EML_Steig_Exkl_Cx0_Init), phys=raw*0.2-102.2 for raw 1..1022, 1023=Cx3ff_Fehler (CM_HMS_EML_Steig_Exkl_Cx3ff_Fehler); unit Unit_PerCent}, range phys -102..102.2 Unit_PerCent, raw 0..1023, unit=Unit_PerCent, transfer-property=PENDING  # Steigung in Prozent. Das Signal dient der Weiterleitung der Steigung an den Basisdienst EML. Positive Werte > bergauf; Negative Werte < bergab Bitte Beachten: Das Signal darf von Kundenfunktionen nicht genutzt werden. Dieses Signal nutzt niemand außer der EML (Gültigkeit: nur für MEB)
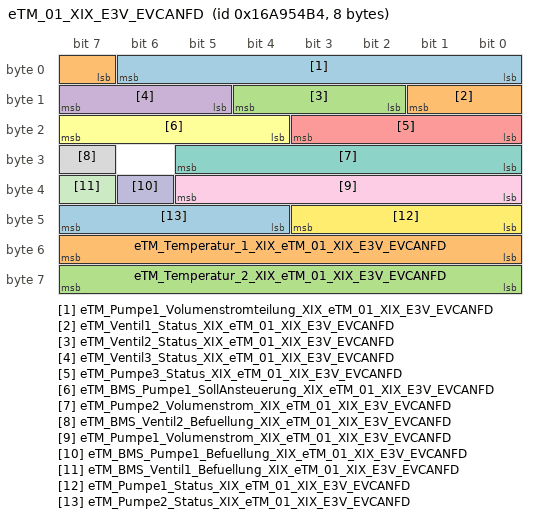
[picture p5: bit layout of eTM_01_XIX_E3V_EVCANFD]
      frame eTM_01_XIX_E3V_EVCANFD: id 0x16A954B4, to Klima, frame-length=8, can-addressing-mode=EXTENDED, can-frame-rx-behavior=CAN-FD, can-frame-tx-behavior=CAN-FD
        pdu eTM_01_XIX_E3V_EVCANFD: length=8, minimum-delay=0.1, transmission-mode-true-timing={cyclic-timing={time-offset=0.0, time-period=0.5}, event-controlled-timing={number-of-repetitions=0, repetition-period=0.0}}, unused-bit-pattern=0
          signal eTM_Pumpe1_Volumenstromteilung_XIX_eTM_01_XIX_E3V_EVCANFD: start 0, 7 bit, little-endian, data-type-policy=OVERRIDE, i-signal-type=PRIMITIVE, init-value=126, base-type=BT_eTM_Pumpe1_Volumenstromteilung, compu {phys=raw*0.01 for raw 0..100, 126=Cx7e_Init (CM_eTM_Pumpe1_Volumenstromteilung_Cx7e_Init), 127=Cx7f_keine_Parallelschaltung (CM_eTM_Pumpe1_Volumenstromteilung_Cx7f_keine_Parallelschaltung); unit Unit_None}, range phys 0..1 Unit_None, raw 0..127, unit=Unit_None, transfer-property=PENDING  # Volumenstrom Aufteilungsfaktor für den Hauptzweig in der Parallelschaltung nach der Pumpe 1 im Kühlkreis HV Komponenten. Aufteilungsfaktor für den Zusatzzweig lässt sich durch "1.0 - Verteilungsfaktor Hauptzweig" bestimmen. Rohwert 126: init Rohwert 127: keine_Parallelschaltung
          signal eTM_Ventil1_Status_XIX_eTM_01_XIX_E3V_EVCANFD: start 7, 3 bit, little-endian, data-type-policy=OVERRIDE, i-signal-type=PRIMITIVE, init-value=6, base-type=BT_eTM_Ventil1_Status, invalid-value=Invalid_eTM_Ventil1_Status_XIX_eTM_01_XIX_E3V_EVCANFD:7, compu {0=Cx0_Ventil_nicht_angesteuert (CM_eTM_Ventil1_Status_Cx0_Ventil_nicht_angesteuert), 1=Cx1_Ventil_angesteuert (CM_eTM_Ventil1_Status_Cx1_Ventil_angesteuert), 5=Cx5_Ventil_nicht_verbaut (CM_eTM_Ventil1_Status_Cx5_Ventil_nicht_verbaut), 6=Cx6_Init (CM_eTM_Ventil1_Status_Cx6_Init), 7=Cx7_Fehler (CM_eTM_Ventil1_Status_Cx7_Fehler)}, range raw 0..7, transfer-property=TRIGGERED-ON-CHANGE-WITHOUT-REPETITION, to Klima(timeout 5 s)  # Ansteuerung NT2 Kuehler-Bypassventil im Kuehlkreis HV-Komponenten
          signal eTM_Ventil2_Status_XIX_eTM_01_XIX_E3V_EVCANFD: start 10, 3 bit, little-endian, data-type-policy=OVERRIDE, i-signal-type=PRIMITIVE, init-value=6, base-type=BT_eTM_Ventil2_Status, invalid-value=Invalid_eTM_Ventil2_Status_XIX_eTM_01_XIX_E3V_EVCANFD:7, compu {0=Cx0_Ventil_nicht_angesteuert (CM_eTM_Ventil2_Status_Cx0_Ventil_nicht_angesteuert), 1=Cx1_Ventil_angesteuert (CM_eTM_Ventil2_Status_Cx1_Ventil_angesteuert), 5=Cx5_Ventil_nicht_verbaut (CM_eTM_Ventil2_Status_Cx5_Ventil_nicht_verbaut), 6=Cx6_Init (CM_eTM_Ventil2_Status_Cx6_Init), 7=Cx7_Fehler (CM_eTM_Ventil2_Status_Cx7_Fehler)}, range raw 0..7, transfer-property=TRIGGERED-ON-CHANGE-WITHOUT-REPETITION, to Klima(timeout 5 s)  # Ansteuerung Heizkreisabsperrventil im Kühlkreis HT Kreis
          signal eTM_Ventil3_Status_XIX_eTM_01_XIX_E3V_EVCANFD: start 13, 3 bit, little-endian, data-type-policy=OVERRIDE, i-signal-type=PRIMITIVE, init-value=6, base-type=BT_eTM_Ventil3_Status, invalid-value=Invalid_eTM_Ventil3_Status_XIX_eTM_01_XIX_E3V_EVCANFD:7, compu {0=Cx0_Ventil_nicht_angesteuert (CM_eTM_Ventil3_Status_Cx0_Ventil_nicht_angesteuert), 1=Cx1_Ventil_angesteuert (CM_eTM_Ventil3_Status_Cx1_Ventil_angesteuert), 5=Cx5_Ventil_nicht_verbaut (CM_eTM_Ventil3_Status_Cx5_Ventil_nicht_verbaut), 6=Cx6_Init (CM_eTM_Ventil3_Status_Cx6_Init), 7=Cx7_Fehler (CM_eTM_Ventil3_Status_Cx7_Fehler)}, range raw 0..7, transfer-property=TRIGGERED-ON-CHANGE-WITHOUT-REPETITION, to Klima(timeout 5 s)  # Ansteuerung Getriebeölkühler-Absperrventil im Kühlkreis HT Kreis
          signal eTM_Pumpe3_Status_XIX_eTM_01_XIX_E3V_EVCANFD: start 16, 4 bit, little-endian, data-type-policy=OVERRIDE, i-signal-type=PRIMITIVE, init-value=14, base-type=BT_eTM_Pumpe3_Status, invalid-value=Invalid_eTM_Pumpe3_Status_XIX_eTM_01_XIX_E3V_EVCANFD:15, compu {phys=raw*10 for raw 0..12, 13=Cxd_nicht_verbaut (CM_eTM_Pumpe3_Status_Cxd_nicht_verbaut), 14=Cxe_Init (CM_eTM_Pumpe3_Status_Cxe_Init), 15=Cxf_Fehler (CM_eTM_Pumpe3_Status_Cxf_Fehler); unit Unit_PerCent}, range phys 0..120 Unit_PerCent, raw 0..15, unit=Unit_PerCent, transfer-property=TRIGGERED-ON-CHANGE-WITHOUT-REPETITION  # Ansteuerung Pumpe NT1 (Kühlkreis NT Komponenten)
          signal eTM_BMS_Pumpe1_SollAnsteuerung_XIX_eTM_01_XIX_E3V_EVCANFD: start 20, 4 bit, little-endian, data-type-policy=OVERRIDE, i-signal-type=PRIMITIVE, init-value=14, base-type=BT_eTM_BMS_Pumpe1_SollAnsteuerung, invalid-value=Invalid_eTM_BMS_Pumpe1_SollAnsteuerung_XIX_eTM_01_XIX_E3V_EVCANFD:15, compu {phys=raw*10 for raw 0..13, 14=Cxe_Init (CM_eTM_BMS_Pumpe1_SollAnsteuerung_Cxe_Init), 15=Cxf_Fehler (CM_eTM_BMS_Pumpe1_SollAnsteuerung_Cxf_Fehler); unit Unit_PerCent}, range phys 0..130 Unit_PerCent, raw 0..15, unit=Unit_PerCent, transfer-property=PENDING, to Klima(timeout 5 s)  # Sollwert Ansteuerung BMS Pumpe1 für Befüllung
          signal eTM_Pumpe2_Volumenstrom_XIX_eTM_01_XIX_E3V_EVCANFD: start 24, 6 bit, little-endian, data-type-policy=OVERRIDE, i-signal-type=PRIMITIVE, init-value=62, base-type=BT_eTM_Pumpe2_Volumenstrom, invalid-value=Invalid_eTM_Pumpe2_Volumenstrom_XIX_eTM_01_XIX_E3V_EVCANFD:63, compu {phys=raw*0.5 for raw 0..60, 61=Cx3d_nicht_verbaut (CM_eTM_Pumpe2_Volumenstrom_Cx3d_nicht_verbaut), 62=Cx3e_Init (CM_eTM_Pumpe2_Volumenstrom_Cx3e_Init), 63=Cx3f_Fehler (CM_eTM_Pumpe2_Volumenstrom_Cx3f_Fehler); unit Unit_LiterPerMinut}, range phys 0..30 Unit_LiterPerMinut, raw 0..63, unit=Unit_LiterPerMinut, transfer-property=PENDING, to Klima(timeout 5 s)  # Soll- Kühlwasservolumenstrom von Pumpe 2 Kühlkreis HV Komponenten
          signal eTM_BMS_Ventil2_Befuellung_XIX_eTM_01_XIX_E3V_EVCANFD: start 31, 1 bit, little-endian, data-type-policy=OVERRIDE, i-signal-type=PRIMITIVE, init-value=0, base-type=BT_eTM_BMS_Ventil2_Befuellung, compu {0=Cx0_false (CM_eTM_BMS_Ventil2_Befuellung_Cx0_false), 1=Cx1_true (CM_eTM_BMS_Ventil2_Befuellung_Cx1_true)}, range raw 0..1, transfer-property=PENDING, to Klima(timeout 5 s)  # Ansteuerung BMS Ventil2 für Befüllung
          signal eTM_Pumpe1_Volumenstrom_XIX_eTM_01_XIX_E3V_EVCANFD: start 32, 6 bit, little-endian, data-type-policy=OVERRIDE, i-signal-type=PRIMITIVE, init-value=62, base-type=BT_eTM_Pumpe1_Volumenstrom, invalid-value=Invalid_eTM_Pumpe1_Volumenstrom_XIX_eTM_01_XIX_E3V_EVCANFD:63, compu {phys=raw*0.5 for raw 0..60, 61=Cx3d_nicht_verbaut (CM_eTM_Pumpe1_Volumenstrom_Cx3d_nicht_verbaut), 62=Cx3e_Init (CM_eTM_Pumpe1_Volumenstrom_Cx3e_Init), 63=Cx3f_Fehler (CM_eTM_Pumpe1_Volumenstrom_Cx3f_Fehler); unit Unit_LiterPerMinut}, range phys 0..30 Unit_LiterPerMinut, raw 0..63, unit=Unit_LiterPerMinut, transfer-property=PENDING, to Klima(timeout 5 s)  # Soll- Kühlwasservolumenstrom von Pumpe 1 Kühlkreis HV Komponenten
          signal eTM_BMS_Pumpe1_Befuellung_XIX_eTM_01_XIX_E3V_EVCANFD: start 38, 1 bit, little-endian, data-type-policy=OVERRIDE, i-signal-type=PRIMITIVE, init-value=0, base-type=BT_eTM_BMS_Pumpe1_Befuellung, compu {0=Cx0_false (CM_eTM_BMS_Pumpe1_Befuellung_Cx0_false), 1=Cx1_true (CM_eTM_BMS_Pumpe1_Befuellung_Cx1_true)}, range raw 0..1, transfer-property=PENDING, to Klima(timeout 5 s)  # Ansteuerung BMS Pumpe1 für Befüllung aktiv
          signal eTM_BMS_Ventil1_Befuellung_XIX_eTM_01_XIX_E3V_EVCANFD: start 39, 1 bit, little-endian, data-type-policy=OVERRIDE, i-signal-type=PRIMITIVE, init-value=0, base-type=BT_eTM_BMS_Ventil1_Befuellung, compu {0=Cx0_false (CM_eTM_BMS_Ventil1_Befuellung_Cx0_false), 1=Cx1_true (CM_eTM_BMS_Ventil1_Befuellung_Cx1_true)}, range raw 0..1, transfer-property=PENDING, to Klima(timeout 5 s)  # Ansteuerung BMS Ventil1 für Befüllung
          signal eTM_Pumpe1_Status_XIX_eTM_01_XIX_E3V_EVCANFD: start 40, 4 bit, little-endian, data-type-policy=OVERRIDE, i-signal-type=PRIMITIVE, init-value=14, base-type=BT_eTM_Pumpe1_Status, invalid-value=Invalid_eTM_Pumpe1_Status_XIX_eTM_01_XIX_E3V_EVCANFD:15, compu {phys=raw*10 for raw 0..12, 13=Cxd_nicht_verbaut (CM_eTM_Pumpe1_Status_Cxd_nicht_verbaut), 14=Cxe_Init (CM_eTM_Pumpe1_Status_Cxe_Init), 15=Cxf_Fehler (CM_eTM_Pumpe1_Status_Cxf_Fehler); unit Unit_PerCent}, range phys 0..120 Unit_PerCent, raw 0..15, unit=Unit_PerCent, transfer-property=TRIGGERED-ON-CHANGE-WITHOUT-REPETITION, to Klima(timeout 5 s)  # Ansteuerung Pumpe 1 Kühlkreis HV Komponenten
          signal eTM_Pumpe2_Status_XIX_eTM_01_XIX_E3V_EVCANFD: start 44, 4 bit, little-endian, data-type-policy=OVERRIDE, i-signal-type=PRIMITIVE, init-value=14, base-type=BT_eTM_Pumpe2_Status, invalid-value=Invalid_eTM_Pumpe2_Status_XIX_eTM_01_XIX_E3V_EVCANFD:15, compu {phys=raw*10 for raw 0..12, 13=Cxd_nicht_verbaut (CM_eTM_Pumpe2_Status_Cxd_nicht_verbaut), 14=Cxe_Init (CM_eTM_Pumpe2_Status_Cxe_Init), 15=Cxf_Fehler (CM_eTM_Pumpe2_Status_Cxf_Fehler); unit Unit_PerCent}, range phys 0..120 Unit_PerCent, raw 0..15, unit=Unit_PerCent, transfer-property=TRIGGERED-ON-CHANGE-WITHOUT-REPETITION, to Klima(timeout 5 s)  # Ansteuerung Pumpe 2 Kühlkreis HV Komponenten
          signal eTM_Temperatur_1_XIX_eTM_01_XIX_E3V_EVCANFD: start 48, 8 bit, little-endian, data-type-policy=OVERRIDE, i-signal-type=PRIMITIVE, init-value=254, base-type=BT_eTM_Temperatur_1, invalid-value=Invalid_eTM_Temperatur_1_XIX_eTM_01_XIX_E3V_EVCANFD:255, compu {phys=raw*0.75-40 for raw 0..253, 254=Cxfe_Init (CM_eTM_Temperatur_1_Cxfe_Init), 255=Cxff_Fehler (CM_eTM_Temperatur_1_Cxff_Fehler); unit Unit_DegreCelsi}, range phys -40..149.75 Unit_DegreCelsi, raw 0..255, unit=Unit_DegreCelsi, transfer-property=PENDING, to Klima(timeout 5 s)  # Wassertemperatur 1 Kühlkreis HV Komponenten
          signal eTM_Temperatur_2_XIX_eTM_01_XIX_E3V_EVCANFD: start 56, 8 bit, little-endian, data-type-policy=OVERRIDE, i-signal-type=PRIMITIVE, init-value=254, base-type=BT_eTM_Temperatur_2, invalid-value=Invalid_eTM_Temperatur_2_XIX_eTM_01_XIX_E3V_EVCANFD:255, compu {phys=raw*0.75-40 for raw 0..252, 253=Cxfd_nicht_verbaut (CM_eTM_Temperatur_2_Cxfd_nicht_verbaut), 254=Cxfe_Init (CM_eTM_Temperatur_2_Cxfe_Init), 255=Cxff_Fehler (CM_eTM_Temperatur_2_Cxff_Fehler); unit Unit_DegreCelsi}, range phys -40..149 Unit_DegreCelsi, raw 0..255, unit=Unit_DegreCelsi, transfer-property=PENDING, to Klima(timeout 5 s)  # Wassertemperatur 2 Kühlkreis HV Komponenten
      frame eTM_02_XIX_E3V_EVCANFD: id 0x1A5554F0, to Klima, frame-length=8, can-addressing-mode=EXTENDED, can-frame-rx-behavior=CAN-FD, can-frame-tx-behavior=CAN-FD
        pdu eTM_02_XIX_E3V_EVCANFD: length=8, minimum-delay=0.1, transmission-mode-true-timing={cyclic-timing={time-offset=0.0, time-period=0.5}, event-controlled-timing={number-of-repetitions=0, repetition-period=0.0}}, unused-bit-pattern=0
          signal eTM_BMS_Konditionierung_moeglich_XIX_eTM_02_XIX_E3V_EVCANFD: start 12, 4 bit, little-endian, data-type-policy=OVERRIDE, i-signal-type=PRIMITIVE, init-value=0, base-type=BT_eTM_BMS_Konditionierung_moeglich, compu {0=Cx0_Konditionierung_nicht_bewertet (CM_eTM_BMS_Konditionierung_moeglich_Cx0_Konditionierung_nicht_bewertet), 1=Cx1_Kuehlen_moeglich (CM_eTM_BMS_Konditionierung_moeglich_Cx1_Kuehlen_moeglich), 2=Cx2_Heizen_moeglich (CM_eTM_BMS_Konditionierung_moeglich_Cx2_Heizen_moeglich), 3=Cx3_Kuehlen_nicht_moeglich (CM_eTM_BMS_Konditionierung_moeglich_Cx3_Kuehlen_nicht_moeglich), 4=Cx4_Heizen_nicht_moeglich (CM_eTM_BMS_Konditionierung_moeglich_Cx4_Heizen_nicht_moeglich), 15=Cxf_Konditionierung_nicht_moeglich (CM_eTM_BMS_Konditionierung_moeglich_Cxf_Konditionierung_nicht_moeglich)}, range raw 0..15, transfer-property=PENDING  # ASG teilt der HV-Batterie mit, ob der von ihr gesendete Kühl-/Heizwunsch umsetzbar ist oder nicht. Zugehörige CAN-Signale: - Der Kühl-/Heizwunsch wird seitens Batterie auf CAN-Signal BMS_eTM_KonditionierungsWunsch gestellt. - Die geforderte Ziel-Wassertemperatur wird auf CAN-Signal BMS_Soll_VorlaufTemperatur übermittelt.
          signal eTM_BMS_ThermischeIstLeistung_XIX_eTM_02_XIX_E3V_EVCANFD: start 16, 9 bit, little-endian, data-type-policy=OVERRIDE, i-signal-type=PRIMITIVE, init-value=510, base-type=BT_eTM_BMS_ThermischeIstLeistung, invalid-value=Invalid_eTM_BMS_ThermischeIstLeistung_XIX_eTM_02_XIX_E3V_EVCANFD:511, compu {phys=raw*50-12700 for raw 0..509, 510=Cx1fe_Init (CM_eTM_BMS_ThermischeIstLeistung_Cx1fe_Init), 511=Cx1ff_Fehler (CM_eTM_BMS_ThermischeIstLeistung_Cx1ff_Fehler); unit Unit_Watt}, range phys -12700..12750 Unit_Watt, raw 0..511, unit=Unit_Watt, transfer-property=TRIGGERED-ON-CHANGE-WITHOUT-REPETITION, to Klima(timeout 5 s)  # Thermische Leistung, die von der HV-Batterie in das Kühlmittel eingetragen wird. Pos.: Wärme wird in das Kühlmittel eingetragen Neg.: Wärme wird dem Kühlmittel entzogen
      frame eTM_03_XIX_E3V_EVCANFD: id 0x16A955DA, to Klima, frame-length=32, can-addressing-mode=EXTENDED, can-frame-rx-behavior=CAN-FD, can-frame-tx-behavior=CAN-FD
        pdu eTM_03_XIX_E3V_EVCANFD: length=32, transmission-mode-true-timing=cyclic-timing={time-offset=0, time-period=0.2}, unused-bit-pattern=0
          signal eTM_Wasserheizer_IstVolumenstrom_XIX_eTM_03_XIX_E3V_EVCANFD: start 16, 9 bit, little-endian, data-type-policy=OVERRIDE, i-signal-type=PRIMITIVE, init-value=510, base-type=BT_eTM_Wasserheizer_IstVolumenstrom, invalid-value=Invalid_eTM_Wasserheizer_IstVolumenstrom_XIX_eTM_03_XIX_E3V_EVCANFD:511, compu {phys=raw*0.1 for raw 0..300, 510=Cx1fe_Init (CM_eTM_Wasserheizer_IstVolumenstrom_Cx1fe_Init), 511=Cx1ff_Fehler (CM_eTM_Wasserheizer_IstVolumenstrom_Cx1ff_Fehler); unit Unit_LiterPerMinut}, range phys 0..30 Unit_LiterPerMinut, raw 0..511, unit=Unit_LiterPerMinut, transfer-property=PENDING, to Klima(timeout 2 s)  # Kühlmittel-Istvolumenstrom über den HV-Wasserheizer.
          signal eTM_PV1_Ansteuerung_XIX_eTM_03_XIX_E3V_EVCANFD: start 25, 7 bit, little-endian, data-type-policy=OVERRIDE, i-signal-type=PRIMITIVE, init-value=126, base-type=BT_eTM_PV1_Ansteuerung, invalid-value=Invalid_eTM_PV1_Ansteuerung_XIX_eTM_03_XIX_E3V_EVCANFD:127, compu {phys=raw for raw 0..100, 126=Cx7e_Init (CM_eTM_PV1_Ansteuerung_Cx7e_Init), 127=Cx7f_Fehler (CM_eTM_PV1_Ansteuerung_Cx7f_Fehler); unit Unit_PerCent}, range phys 0..100 Unit_PerCent, raw 0..127, unit=Unit_PerCent, transfer-property=PENDING, to Klima(timeout 2 s)  # Relative Ansteuerung des Proportionalventils 1.
          signal eTM_PV2_Ansteuerung_XIX_eTM_03_XIX_E3V_EVCANFD: start 32, 7 bit, little-endian, data-type-policy=OVERRIDE, i-signal-type=PRIMITIVE, init-value=126, base-type=BT_eTM_PV2_Ansteuerung, invalid-value=Invalid_eTM_PV2_Ansteuerung_XIX_eTM_03_XIX_E3V_EVCANFD:127, compu {phys=raw for raw 0..100, 126=Cx7e_Init (CM_eTM_PV2_Ansteuerung_Cx7e_Init), 127=Cx7f_Fehler (CM_eTM_PV2_Ansteuerung_Cx7f_Fehler); unit Unit_PerCent}, range phys 0..100 Unit_PerCent, raw 0..127, unit=Unit_PerCent, transfer-property=PENDING, to Klima(timeout 2 s)  # Relative Ansteuerung des Proportionalventils 2.
          signal eTM_PumpeBat_Ansteuerung_XIX_eTM_03_XIX_E3V_EVCANFD: start 39, 7 bit, little-endian, data-type-policy=OVERRIDE, i-signal-type=PRIMITIVE, init-value=126, base-type=BT_eTM_PumpeBat_Ansteuerung, invalid-value=Invalid_eTM_PumpeBat_Ansteuerung_XIX_eTM_03_XIX_E3V_EVCANFD:127, compu {phys=raw for raw 0..100, 126=Cx7e_Init (CM_eTM_PumpeBat_Ansteuerung_Cx7e_Init), 127=Cx7f_Fehler (CM_eTM_PumpeBat_Ansteuerung_Cx7f_Fehler); unit Unit_PerCent}, range phys 0..100 Unit_PerCent, raw 0..127, unit=Unit_PerCent, transfer-property=PENDING, to Klima(timeout 2 s)  # Relative Ansteuerung der Kühlmittelpumpe für die Batterie.
          signal eTM_PumpeAntrieb_Ansteuerung_XIX_eTM_03_XIX_E3V_EVCANFD: start 46, 7 bit, little-endian, data-type-policy=OVERRIDE, i-signal-type=PRIMITIVE, init-value=126, base-type=BT_eTM_PumpeAntrieb_Ansteuerung, invalid-value=Invalid_eTM_PumpeAntrieb_Ansteuerung_XIX_eTM_03_XIX_E3V_EVCANFD:127, compu {phys=raw for raw 0..100, 126=Cx7e_Init (CM_eTM_PumpeAntrieb_Ansteuerung_Cx7e_Init), 127=Cx7f_Fehler (CM_eTM_PumpeAntrieb_Ansteuerung_Cx7f_Fehler); unit Unit_PerCent}, range phys 0..100 Unit_PerCent, raw 0..127, unit=Unit_PerCent, transfer-property=PENDING, to Klima(timeout 2 s)  # Relative Ansteuerung der Kühlmittelpumpe für den Antrieb.
          signal eTM_Ist_rLM_XIX_eTM_03_XIX_E3V_EVCANFD: start 53, 7 bit, little-endian, data-type-policy=OVERRIDE, i-signal-type=PRIMITIVE, init-value=126, base-type=BT_eTM_Ist_rLM, invalid-value=Invalid_eTM_Ist_rLM_XIX_eTM_03_XIX_E3V_EVCANFD:127, compu {phys=raw for raw 0..100, 126=Cx7e_Init (CM_eTM_Ist_rLM_Cx7e_Init), 127=Cx7f_Fehler (CM_eTM_Ist_rLM_Cx7f_Fehler); unit Unit_PerCent}, range phys 0..100 Unit_PerCent, raw 0..127, unit=Unit_PerCent, transfer-property=PENDING, to Klima(timeout 2 s)  # Relativer Ist-Kühlluftmassenstrom.
          signal eTM_PumpeHWT_Ansteuerung_XIX_eTM_03_XIX_E3V_EVCANFD: start 60, 7 bit, little-endian, data-type-policy=OVERRIDE, i-signal-type=PRIMITIVE, init-value=126, base-type=BT_eTM_PumpeHWT_Ansteuerung, invalid-value=Invalid_eTM_PumpeHWT_Ansteuerung_XIX_eTM_03_XIX_E3V_EVCANFD:127, compu {phys=raw for raw 0..100, 126=Cx7e_Init (CM_eTM_PumpeHWT_Ansteuerung_Cx7e_Init), 127=Cx7f_Fehler (CM_eTM_PumpeHWT_Ansteuerung_Cx7f_Fehler); unit Unit_PerCent}, range phys 0..100 Unit_PerCent, raw 0..127, unit=Unit_PerCent, transfer-property=PENDING, to Klima(timeout 2 s)  # Relative Ansteuerung der Kühlmittelpumpe für den HWT.
          signal eTM_HWT_IstVolumenstrom_XIX_eTM_03_XIX_E3V_EVCANFD: start 67, 7 bit, little-endian, data-type-policy=OVERRIDE, i-signal-type=PRIMITIVE, init-value=126, base-type=BT_eTM_HWT_IstVolumenstrom, invalid-value=Invalid_eTM_HWT_IstVolumenstrom_XIX_eTM_03_XIX_E3V_EVCANFD:127, compu {phys=raw*0.1 for raw 0..100, 126=Cx7e_Init (CM_eTM_HWT_IstVolumenstrom_Cx7e_Init), 127=Cx7f_Fehler (CM_eTM_HWT_IstVolumenstrom_Cx7f_Fehler); unit Unit_LiterPerMinut}, range phys 0..10 Unit_LiterPerMinut, raw 0..127, unit=Unit_LiterPerMinut, transfer-property=PENDING, to Klima(timeout 2 s)  # Kühlmittel-Istvolumenstrom über den Heizungswärmetauscher.
          signal eTM_PWR_MinVorlaufTemp_XIX_eTM_03_XIX_E3V_EVCANFD: start 74, 10 bit, little-endian, data-type-policy=OVERRIDE, i-signal-type=PRIMITIVE, init-value=1022, base-type=BT_eTM_PWR_MinVorlaufTemp, invalid-value=Invalid_eTM_PWR_MinVorlaufTemp_XIX_eTM_03_XIX_E3V_EVCANFD:1023, compu {phys=raw*0.25-50 for raw 0..880, 1022=Cx3fe_Init (CM_eTM_PWR_MinVorlaufTemp_Cx3fe_Init), 1023=Cx3ff_Fehler (CM_eTM_PWR_MinVorlaufTemp_Cx3ff_Fehler); unit Unit_DegreCelsi}, range phys -50..170 Unit_DegreCelsi, raw 0..1023, unit=Unit_DegreCelsi, transfer-property=PENDING, to Klima(timeout 2 s)  # Minimaltemperatur (Grenzwert) vor PWR für die Wasserwärmepumpe.
          signal eTM_Wasserheizer_SollTemp_Ausgng_XIX_eTM_03_XIX_E3V_EVCANFD: start 84, 10 bit, little-endian, data-type-policy=OVERRIDE, i-signal-type=PRIMITIVE, init-value=1022, base-type=BT_eTM_Wasserheizer_SollTemp_Ausgng, invalid-value=Invalid_eTM_Wasserheizer_SollTemp_Ausgng_XIX_eTM_03_XIX_E3V_EVCANFD:1023, compu {phys=raw*0.25-50 for raw 0..600, 1022=Cx3fe_Init (CM_eTM_Wasserheizer_SollTemp_Ausgng_Cx3fe_Init), 1023=Cx3ff_Fehler (CM_eTM_Wasserheizer_SollTemp_Ausgng_Cx3ff_Fehler); unit Unit_DegreCelsi}, range phys -50..100 Unit_DegreCelsi, raw 0..1023, unit=Unit_DegreCelsi, transfer-property=PENDING, to Klima(timeout 2 s)  # Sollaustrittstemperatur des HV-Wasserheizers.
          signal eTM_Batterieheizen_Anf_XIX_eTM_03_XIX_E3V_EVCANFD: start 94, 3 bit, little-endian, data-type-policy=OVERRIDE, i-signal-type=PRIMITIVE, init-value=6, base-type=BT_eTM_Batterieheizen_Anf, invalid-value=Invalid_eTM_Batterieheizen_Anf_XIX_eTM_03_XIX_E3V_EVCANFD:7, compu {0=Cx0_Keine_Anforderung (CM_eTM_Batterieheizen_Anf_Cx0_Keine_Anforderung), 1=Cx1_Heizanforderung_Stufe_1 (CM_eTM_Batterieheizen_Anf_Cx1_Heizanforderung_Stufe_1), 2=Cx2_Heizanforderung_Stufe_2 (CM_eTM_Batterieheizen_Anf_Cx2_Heizanforderung_Stufe_2), 3=Cx3_Heizanforderung_Stufe_3 (CM_eTM_Batterieheizen_Anf_Cx3_Heizanforderung_Stufe_3), 6=Cx6_Init (CM_eTM_Batterieheizen_Anf_Cx6_Init), 7=Cx7_Fehler (CM_eTM_Batterieheizen_Anf_Cx7_Fehler)}, range raw 0..7, transfer-property=PENDING, to Klima(timeout 2 s)  # Anforderung Heizbedarf des ASG zum Heizen der Batterie.
          signal eTM_HVBatt_IstVolumenstrom_XIX_eTM_03_XIX_E3V_EVCANFD: start 97, 9 bit, little-endian, data-type-policy=OVERRIDE, i-signal-type=PRIMITIVE, init-value=510, base-type=BT_eTM_HVBatt_IstVolumenstrom, invalid-value=Invalid_eTM_HVBatt_IstVolumenstrom_XIX_eTM_03_XIX_E3V_EVCANFD:511, compu {phys=raw*0.1 for raw 0..300, 510=Cx1fe_Init (CM_eTM_HVBatt_IstVolumenstrom_Cx1fe_Init), 511=Cx1ff_Fehler (CM_eTM_HVBatt_IstVolumenstrom_Cx1ff_Fehler); unit Unit_LiterPerMinut}, range phys 0..30 Unit_LiterPerMinut, raw 0..511, unit=Unit_LiterPerMinut, transfer-property=PENDING, to Klima(timeout 2 s)  # Kühlmittel-Istvolumenstrom über die HV-Batterie
          signal eTM_Kuehlung_Status_XIX_eTM_03_XIX_E3V_EVCANFD: start 106, 21 bit, little-endian, data-type-policy=OVERRIDE, i-signal-type=PRIMITIVE, init-value=524288, base-type=BT_eTM_Kuehlung_Status, compu {1=Cx1_keine_Kuehlung (CM_eTM_Kuehlung_Status_Cx1_keine_Kuehlung), 2=Cx2_passive_Kuehlung (CM_eTM_Kuehlung_Status_Cx2_passive_Kuehlung), 4=Cx4_aktive_Kuehlung (CM_eTM_Kuehlung_Status_Cx4_aktive_Kuehlung), 8=Cx8_passives_Heizen (CM_eTM_Kuehlung_Status_Cx8_passives_Heizen), 16=Cx10_aktives_Heizen (CM_eTM_Kuehlung_Status_Cx10_aktives_Heizen), 32=Cx20_Reheat (CM_eTM_Kuehlung_Status_Cx20_Reheat), 64=Cx40_Enteisungsbetrieb (CM_eTM_Kuehlung_Status_Cx40_Enteisungsbetrieb), 128=Cx80_Entlueftungsbetrieb (CM_eTM_Kuehlung_Status_Cx80_Entlueftungsbetrieb), 256=Cx100_Befuellung (CM_eTM_Kuehlung_Status_Cx100_Befuellung), 512=Cx200_Waermepumpe_Antriebskreis_aktiv (CM_eTM_Kuehlung_Status_Cx200_Waermepumpe_Antriebskreis_aktiv), 1024=Cx400_Waermepumpe_Batteriekreis_aktiv (CM_eTM_Kuehlung_Status_Cx400_Waermepumpe_Batteriekreis_aktiv), 2048=Cx800_passives_Kuehlen_moeglich (CM_eTM_Kuehlung_Status_Cx800_passives_Kuehlen_moeglich), 4096=Cx1000_aktives_Kuehlen_moeglich (CM_eTM_Kuehlung_Status_Cx1000_aktives_Kuehlen_moeglich), 8192=Cx2000_passives_Heizen_moeglich (CM_eTM_Kuehlung_Status_Cx2000_passives_Heizen_moeglich), 16384=Cx4000_aktives_Heizen_moeglich (CM_eTM_Kuehlung_Status_Cx4000_aktives_Heizen_moeglich), 32768=Cx8000_Waermepume_moeglich (CM_eTM_Kuehlung_Status_Cx8000_Waermepume_moeglich), 65536=Cx10000_Vorhalt_1 (CM_eTM_Kuehlung_Status_Cx10000_Vorhalt_1), 131072=Cx20000_Vorhalt_2 (CM_eTM_Kuehlung_Status_Cx20000_Vorhalt_2), 262144=Cx40000_Vorhalt_3 (CM_eTM_Kuehlung_Status_Cx40000_Vorhalt_3), 524288=Cx80000_Init (CM_eTM_Kuehlung_Status_Cx80000_Init), 1048576=Cx100000_Fehler_vorhanden (CM_eTM_Kuehlung_Status_Cx100000_Fehler_vorhanden)}, range raw 1..1048576, transfer-property=PENDING, to Klima(timeout 2 s)  # Betriebszustand in dem sich das Kühlsystem befindet.
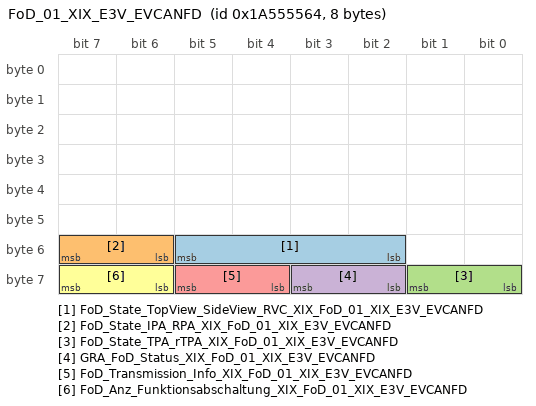
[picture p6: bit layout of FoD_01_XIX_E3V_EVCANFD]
      frame FoD_01_XIX_E3V_EVCANFD: id 0x1A555564, to Klima, frame-length=8, can-addressing-mode=EXTENDED, can-frame-rx-behavior=CAN-FD, can-frame-tx-behavior=CAN-FD
        pdu FoD_01_XIX_E3V_EVCANFD: length=8, minimum-delay=0.2, transmission-mode-true-timing={cyclic-timing={time-offset=0.0, time-period=1.0}, event-controlled-timing={number-of-repetitions=0, repetition-period=0.0}}, unused-bit-pattern=0
          signal FoD_State_TopView_SideView_RVC_XIX_FoD_01_XIX_E3V_EVCANFD: start 50, 4 bit, little-endian, data-type-policy=OVERRIDE, i-signal-type=PRIMITIVE, init-value=0, base-type=BT_FoD_State_TopView_SideView_RVC, compu {0=Cx0_default (CM_FoD_State_TopView_SideView_RVC_Cx0_default), 1=Cx1_RVC_TopView_SideView_nicht_aktiv (CM_FoD_State_TopView_SideView_RVC_Cx1_RVC_TopView_SideView_nicht_aktiv), 2=Cx2_RVC_aktiv (CM_FoD_State_TopView_SideView_RVC_Cx2_RVC_aktiv), 3=Cx3_RVC_nicht_aktiv (CM_FoD_State_TopView_SideView_RVC_Cx3_RVC_nicht_aktiv), 4=Cx4_TopView_SideView_nicht_aktiv (CM_FoD_State_TopView_SideView_RVC_Cx4_TopView_SideView_nicht_aktiv), 5=Cx5_RVC_TopView_aktiv (CM_FoD_State_TopView_SideView_RVC_Cx5_RVC_TopView_aktiv), 6=Cx6_SideView_aktiv (CM_FoD_State_TopView_SideView_RVC_Cx6_SideView_aktiv), 7=Cx7_RVC_SideView_aktiv (CM_FoD_State_TopView_SideView_RVC_Cx7_RVC_SideView_aktiv), 8=Cx8_RVC_TopView_SideView_aktiv (CM_FoD_State_TopView_SideView_RVC_Cx8_RVC_TopView_SideView_aktiv)}, range raw 0..8, transfer-property=PENDING  # Function on Demand State for TopView and SideView and RearView
          signal FoD_State_IPA_RPA_XIX_FoD_01_XIX_E3V_EVCANFD: start 54, 2 bit, little-endian, data-type-policy=OVERRIDE, i-signal-type=PRIMITIVE, init-value=0, base-type=BT_FoD_State_IPA_RPA, compu {0=Cx0_default (CM_FoD_State_IPA_RPA_Cx0_default), 1=Cx1_nicht_aktiv (CM_FoD_State_IPA_RPA_Cx1_nicht_aktiv), 2=Cx2_IPA_aktiv (CM_FoD_State_IPA_RPA_Cx2_IPA_aktiv), 3=Cx3_IPA_und_RPA_aktiv (CM_FoD_State_IPA_RPA_Cx3_IPA_und_RPA_aktiv)}, range raw 0..3, transfer-property=PENDING  # Function on Demand Activation State for IPA and RPA
          signal FoD_State_TPA_rTPA_XIX_FoD_01_XIX_E3V_EVCANFD: start 56, 2 bit, little-endian, data-type-policy=OVERRIDE, i-signal-type=PRIMITIVE, init-value=0, base-type=BT_FoD_State_TPA_rTPA, compu {0=Cx0_default (CM_FoD_State_TPA_rTPA_Cx0_default), 1=Cx1_nicht_aktiv (CM_FoD_State_TPA_rTPA_Cx1_nicht_aktiv), 2=Cx2_TPA_aktiv (CM_FoD_State_TPA_rTPA_Cx2_TPA_aktiv), 3=Cx3_TPA_und_rTPA_aktiv (CM_FoD_State_TPA_rTPA_Cx3_TPA_und_rTPA_aktiv)}, range raw 0..3, transfer-property=PENDING  # Function on Demand Activation State for TPA and rTPA from Function Master
          signal GRA_FoD_Status_XIX_FoD_01_XIX_E3V_EVCANFD: start 58, 2 bit, little-endian, data-type-policy=OVERRIDE, i-signal-type=PRIMITIVE, init-value=0, base-type=BT_GRA_FoD_Status, compu {0=Cx0_Init (CM_GRA_FoD_Status_Cx0_Init), 1=Cx1_Funktion_inaktiv (CM_GRA_FoD_Status_Cx1_Funktion_inaktiv), 2=Cx2_Funktion_aktiv (CM_GRA_FoD_Status_Cx2_Funktion_aktiv)}, range raw 0..2, transfer-property=TRIGGERED-ON-CHANGE-WITHOUT-REPETITION  # Verortung des FOD-Slaves für die Funktion GRA erfolgt im Gateway. Signal übermittelt den FOD-Status an das MSG.
          signal FoD_Transmission_Info_XIX_FoD_01_XIX_E3V_EVCANFD: start 60, 2 bit, little-endian, data-type-policy=OVERRIDE, i-signal-type=PRIMITIVE, init-value=0, base-type=BT_FoD_Transmission_Info, compu {0=Cx0_Initwert (CM_FoD_Transmission_Info_Cx0_Initwert), 1=Cx1_start_transmission (CM_FoD_Transmission_Info_Cx1_start_transmission), 2=Cx2_finish_transmission (CM_FoD_Transmission_Info_Cx2_finish_transmission)}, range raw 0..2, transfer-property=TRIGGERED-ON-CHANGE-WITHOUT-REPETITION, to Klima(timeout 5 s)  # Mit dem Signal zeigt der FoD-Master allen FoD-Slaves den Beginn und das Ende eines Freischaltuebertragungszykluses (FS-ID-Zyklus) an.
          signal FoD_Anz_Funktionsabschaltung_XIX_FoD_01_XIX_E3V_EVCANFD: start 62, 2 bit, little-endian, data-type-policy=OVERRIDE, i-signal-type=PRIMITIVE, init-value=0, base-type=BT_FoD_Anz_Funktionsabschaltung, compu {0=Cx0_Init (CM_FoD_Anz_Funktionsabschaltung_Cx0_Init), 1=Cx1_Popup_aufschalten (CM_FoD_Anz_Funktionsabschaltung_Cx1_Popup_aufschalten)}, range raw 0..1, transfer-property=TRIGGERED-ON-CHANGE-WITHOUT-REPETITION  # Signal triggert Aufschaltung eines Popups, um dem Fahrer die Abschaltung einer Funktion zu melden.
      frame FoD_Klima_Req_XIX_E3V_EVCANFD: id 0x17FC0346, to Klima, frame-length=8, can-addressing-mode=EXTENDED, can-frame-rx-behavior=CAN-FD, can-frame-tx-behavior=CAN-FD
        n pdu FoD_Klima_Req_XIX_E3V_EVCANFD: length=8
      frame FoD_Klima_Resp_XIX_E3V_EVCANFD: id 0x17FE0346, from Klima, frame-length=8, can-addressing-mode=EXTENDED, can-frame-rx-behavior=CAN-FD, can-frame-tx-behavior=CAN-FD
        n pdu FoD_Klima_Resp_XIX_E3V_EVCANFD: length=8
